VERSION ""

NS_ :

BS_:

BU_: SBZA_R_LS SBZA_L_LS VIS2_LS SDM_LS PEPS_LS UPA_LS PTM_LS MSM_LS HFP_LS EOCM_F_LS ECC_LS DCAC_LS CGM_LS BSM_LS BCM_LS AOS_LS

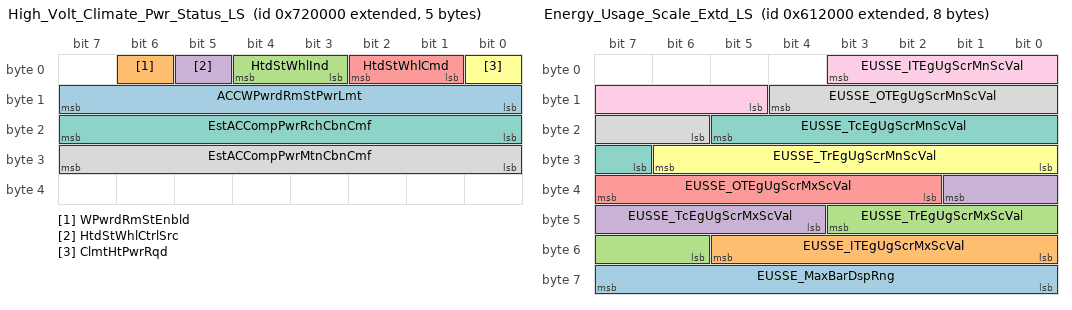
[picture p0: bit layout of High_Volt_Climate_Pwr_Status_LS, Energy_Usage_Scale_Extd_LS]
BO_ 2154954752 High_Volt_Climate_Pwr_Status_LS: 5 ECC_LS
 SG_ ACCWPwrdRmStPwrLmt : 15|8@0+ (0.1,0) [0|25.5] "kW"  CGM_LS
 SG_ WPwrdRmStEnbld : 6|1@0+ (1,0) [0|1] ""  CGM_LS
 SG_ HtdStWhlInd : 4|2@0+ (1,0) [0|3] ""  CGM_LS
 SG_ HtdStWhlCtrlSrc : 5|1@0+ (1,0) [0|1] ""  CGM_LS
 SG_ HtdStWhlCmd : 2|2@0+ (1,0) [0|3] ""  CGM_LS
 SG_ ClmtHtPwrRqd : 0|1@0+ (1,0) [0|1] ""  CGM_LS
 SG_ EstACCompPwrRchCbnCmf : 23|8@0+ (0.04,0) [0|10.2] "kw"  CGM_LS,BSM_LS
 SG_ EstACCompPwrMtnCbnCmf : 31|8@0+ (0.04,0) [0|10.2] "kW"  CGM_LS,BSM_LS

BO_ 2153848832 Energy_Usage_Scale_Extd_LS: 8 BSM_LS
 SG_ EUSSE_MaxBarDspRng : 63|8@0+ (1,0) [0|255] ""  CGM_LS
 SG_ EUSSE_ITEgUgScrMxScVal : 53|6@0+ (5,0) [0|315] ""  CGM_LS
 SG_ EUSSE_TrEgUgScrMxScVal : 43|6@0+ (5,0) [0|315] ""  CGM_LS
 SG_ EUSSE_TcEgUgScrMxScVal : 33|6@0+ (5,0) [0|315] ""  CGM_LS
 SG_ EUSSE_OTEgUgScrMxScVal : 39|6@0+ (5,0) [0|315] ""  CGM_LS
 SG_ EUSSE_TrEgUgScrMnScVal : 30|7@0- (5,0) [-320|315] ""  CGM_LS
 SG_ EUSSE_TcEgUgScrMnScVal : 21|7@0- (5,0) [-320|315] ""  CGM_LS
 SG_ EUSSE_OTEgUgScrMnScVal : 12|7@0- (5,0) [-320|315] ""  CGM_LS
 SG_ EUSSE_ITEgUgScrMnScVal : 3|7@0- (5,0) [-320|315] ""  CGM_LS

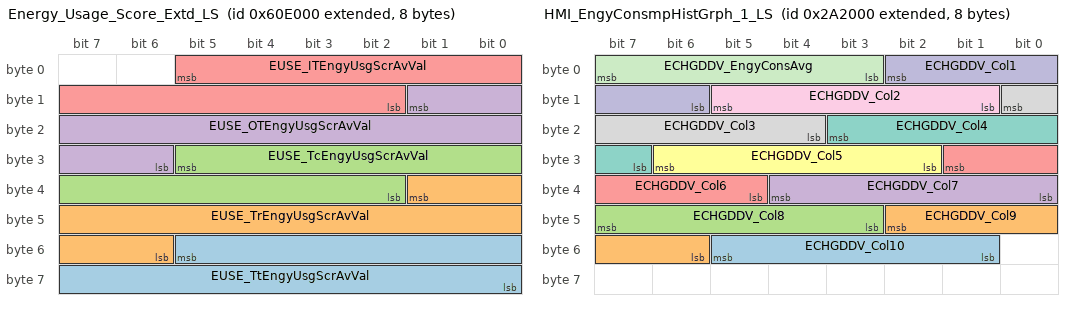
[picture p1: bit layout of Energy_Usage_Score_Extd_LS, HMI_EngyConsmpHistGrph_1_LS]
BO_ 2153832448 Energy_Usage_Score_Extd_LS: 8 BSM_LS
 SG_ EUSE_TtEngyUsgScrAvVal : 53|14@0- (0.1,0) [-819.2|819.1] ""  CGM_LS
 SG_ EUSE_TrEngyUsgScrAvVal : 33|12@0- (0.1,0) [-204.8|204.7] ""  CGM_LS
 SG_ EUSE_TcEngyUsgScrAvVal : 29|12@0- (0.1,0) [-204.8|204.7] ""  CGM_LS
 SG_ EUSE_OTEngyUsgScrAvVal : 9|12@0- (0.1,0) [-204.8|204.7] ""  CGM_LS
 SG_ EUSE_ITEngyUsgScrAvVal : 5|12@0- (0.1,0) [-204.8|204.7] ""  CGM_LS

BO_ 2150244352 HMI_EngyConsmpHistGrph_1_LS: 8 BSM_LS
 SG_ ECHGDDV_Col10 : 53|5@0+ (1,0) [0|31] ""  CGM_LS
 SG_ ECHGDDV_Col9 : 42|5@0+ (1,0) [0|31] ""  CGM_LS
 SG_ ECHGDDV_Col8 : 47|5@0+ (1,0) [0|31] ""  CGM_LS
 SG_ ECHGDDV_Col7 : 36|5@0+ (1,0) [0|31] ""  CGM_LS
 SG_ ECHGDDV_Col6 : 25|5@0+ (1,0) [0|31] ""  CGM_LS
 SG_ ECHGDDV_Col5 : 30|5@0+ (1,0) [0|31] ""  CGM_LS
 SG_ ECHGDDV_Col4 : 19|5@0+ (1,0) [0|31] ""  CGM_LS
 SG_ ECHGDDV_Col3 : 8|5@0+ (1,0) [0|31] ""  CGM_LS
 SG_ ECHGDDV_Col2 : 13|5@0+ (1,0) [0|31] ""  CGM_LS
 SG_ ECHGDDV_Col1 : 2|5@0+ (1,0) [0|31] ""  CGM_LS
 SG_ ECHGDDV_EngyConsAvg : 7|5@0+ (1,0) [0|31] ""  CGM_LS

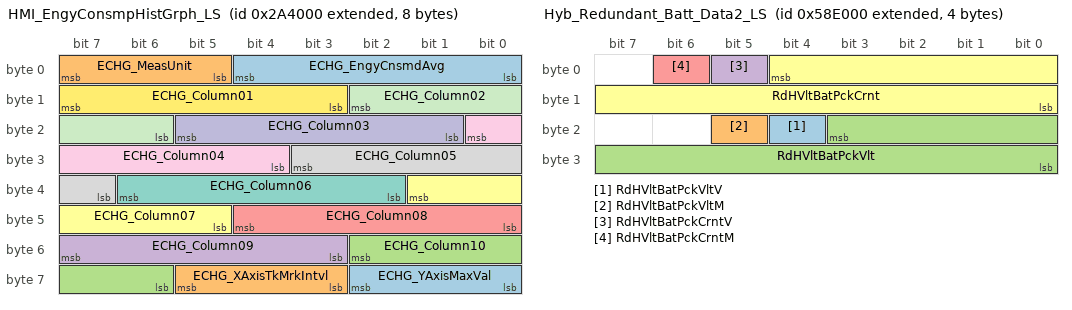
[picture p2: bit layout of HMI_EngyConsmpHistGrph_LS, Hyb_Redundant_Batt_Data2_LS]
BO_ 2150252544 HMI_EngyConsmpHistGrph_LS: 8 BSM_LS
 SG_ ECHG_YAxisMaxVal : 58|3@0+ (1,0) [0|7] ""  CGM_LS
 SG_ ECHG_XAxisTkMrkIntvl : 61|3@0+ (1,0) [0|7] ""  CGM_LS
 SG_ ECHG_Column10 : 50|5@0+ (1,0) [0|31] ""  CGM_LS
 SG_ ECHG_Column09 : 55|5@0+ (1,0) [0|31] ""  CGM_LS
 SG_ ECHG_Column08 : 44|5@0+ (1,0) [0|31] ""  CGM_LS
 SG_ ECHG_Column07 : 33|5@0+ (1,0) [0|31] ""  CGM_LS
 SG_ ECHG_Column06 : 38|5@0+ (1,0) [0|31] ""  CGM_LS
 SG_ ECHG_Column05 : 27|5@0+ (1,0) [0|31] ""  CGM_LS
 SG_ ECHG_Column04 : 16|5@0+ (1,0) [0|31] ""  CGM_LS
 SG_ ECHG_Column03 : 21|5@0+ (1,0) [0|31] ""  CGM_LS
 SG_ ECHG_Column02 : 10|5@0+ (1,0) [0|31] ""  CGM_LS
 SG_ ECHG_Column01 : 15|5@0+ (1,0) [0|31] ""  CGM_LS
 SG_ ECHG_EngyCnsmdAvg : 4|5@0+ (1,0) [0|31] ""  CGM_LS
 SG_ ECHG_MeasUnit : 7|3@0+ (1,0) [0|7] ""  CGM_LS

BO_ 2153308160 Hyb_Redundant_Batt_Data2_LS: 4 BSM_LS
 SG_ RdHVltBatPckVltV : 20|1@0+ (1,0) [0|1] ""  CGM_LS
 SG_ RdHVltBatPckVltM : 21|1@0+ (1,0) [0|1] ""  CGM_LS
 SG_ RdHVltBatPckVlt : 19|12@0+ (0.125,0) [0|511.875] "V"  CGM_LS
 SG_ RdHVltBatPckCrntV : 5|1@0+ (1,0) [0|1] ""  CGM_LS
 SG_ RdHVltBatPckCrntM : 6|1@0+ (1,0) [0|1] ""  CGM_LS
 SG_ RdHVltBatPckCrnt : 4|13@0- (0.15,0) [-614.4|614.25] "A"  CGM_LS

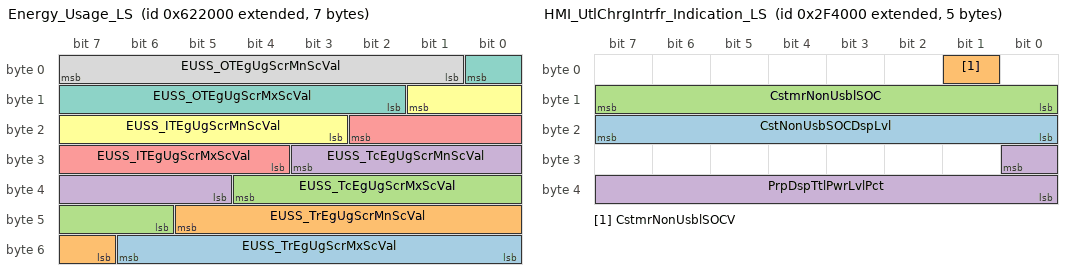
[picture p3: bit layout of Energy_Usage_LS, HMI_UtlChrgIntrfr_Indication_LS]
BO_ 2153914368 Energy_Usage_LS: 7 BSM_LS
 SG_ EUSS_TrEgUgScrMxScVal : 54|7@0- (0.1,0) [-5|5] ""  CGM_LS
 SG_ EUSS_TrEgUgScrMnScVal : 45|7@0- (0.1,0) [-5|5] ""  CGM_LS
 SG_ EUSS_TcEgUgScrMxScVal : 36|7@0- (0.1,0) [-5|5] ""  CGM_LS
 SG_ EUSS_TcEgUgScrMnScVal : 27|7@0- (0.1,0) [-5|5] ""  CGM_LS
 SG_ EUSS_ITEgUgScrMxScVal : 18|7@0- (0.1,0) [-5|5] ""  CGM_LS
 SG_ EUSS_ITEgUgScrMnScVal : 9|7@0- (0.1,0) [-5|5] ""  CGM_LS
 SG_ EUSS_OTEgUgScrMxScVal : 0|7@0- (0.1,0) [-5|5] ""  CGM_LS
 SG_ EUSS_OTEgUgScrMnScVal : 7|7@0- (0.1,0) [-5|5] ""  CGM_LS

BO_ 2150580224 HMI_UtlChrgIntrfr_Indication_LS: 5 BSM_LS
 SG_ CstNonUsbSOCDspLvl : 23|8@0+ (0.392157,0) [0|100.000035] "%"  CGM_LS
 SG_ CstmrNonUsblSOCV : 1|1@0+ (1,0) [0|1] ""  CGM_LS
 SG_ CstmrNonUsblSOC : 15|8@0+ (0.392157,0) [0|100.000035] "%"  CGM_LS
 SG_ PrpDspTtlPwrLvlPct : 24|9@0- (0.392157,0) [-100.392192|100.000035] "%"  CGM_LS

BO_ 2150080512 Aux_Coolant_Heater_Status_LS: 8 BSM_LS
 SG_ LBCVLS_VehGPSLctV : 27|1@0+ (1,0) [0|1] ""  CGM_LS
 SG_ LBCVLS_VehGPSLct : 26|3@0+ (1,0) [0|7] ""  CGM_LS
 SG_ LBCPSS_PosUpdtStat : 20|2@0+ (1,0) [0|3] ""  CGM_LS
 SG_ LBCPSS_PosUpdtLct : 18|3@0+ (1,0) [0|7] ""  CGM_LS
 SG_ LBCCsStAvl : 7|1@0+ (1,0) [0|1] ""  CGM_LS
 SG_ LBCCsCrStVal : 2|2@0+ (1,0) [0|3] ""  CGM_LS
 SG_ LBCCF_Lct4PosStrdIO : 28|1@0+ (1,0) [0|1] ""  CGM_LS
 SG_ LBCCF_Lct3PosStrdIO : 29|1@0+ (1,0) [0|1] ""  CGM_LS
 SG_ LBCCF_Lct2PosStrdIO : 30|1@0+ (1,0) [0|1] ""  CGM_LS
 SG_ LBCCF_Lct1PosStrdIO : 31|1@0+ (1,0) [0|1] ""  CGM_LS
 SG_ LBCCDRR_PosNumbr : 10|3@0+ (1,0) [0|7] ""  CGM_LS
 SG_ LBCCDRR_ClrStrdPosResp : 12|2@0+ (1,0) [0|3] ""  CGM_LS
 SG_ ChrgCyclOvrlEngyEcnEq : 51|12@0+ (0.1,0) [0|409.5] "km/l"  CGM_LS
 SG_ ChrgCyclElecEngyEcnEq : 35|12@0+ (0.1,0) [0|409.5] "km/l"  CGM_LS
 SG_ LBCChrgLvlPrfExpIO : 6|1@0+ (1,0) [0|1] ""  CGM_LS
 SG_ EngAstHtDfrdHtMdAct : 0|1@0+ (1,0) [0|1] ""  ECC_LS,CGM_LS
 SG_ AuxClntHtrVlvStat : 5|3@0+ (1,0) [0|7] ""  ECC_LS,CGM_LS

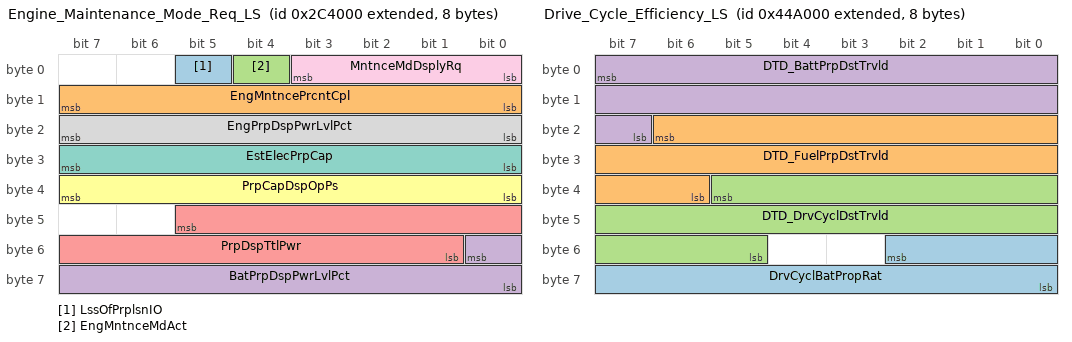
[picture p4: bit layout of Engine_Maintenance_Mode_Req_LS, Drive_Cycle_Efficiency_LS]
BO_ 2150383616 Engine_Maintenance_Mode_Req_LS: 8 BSM_LS
 SG_ LssOfPrplsnIO : 5|1@0+ (1,0) [0|1] ""  CGM_LS
 SG_ EngMntncePrcntCpl : 15|8@0+ (0.392157,0) [0|100.000035] "%"  CGM_LS
 SG_ EngMntnceMdAct : 4|1@0+ (1,0) [0|1] ""  CGM_LS
 SG_ BatPrpDspPwrLvlPct : 48|9@0- (0.392157,0) [-100.392192|100.000035] "%"  CGM_LS
 SG_ PrpDspTtlPwr : 45|13@0+ (0.5,-326.6) [-326.6|3768.9] "kW"  CGM_LS
 SG_ PrpCapDspOpPs : 39|8@0+ (0.392157,0) [0|100.000035] "%"  CGM_LS
 SG_ EstElecPrpCap : 31|8@0+ (0.392157,0) [0|100.000035] "%"  CGM_LS
 SG_ EngPrpDspPwrLvlPct : 23|8@0+ (0.392157,0) [0|100.000035] "%"  CGM_LS
 SG_ MntnceMdDsplyRq : 3|4@0+ (1,0) [0|15] ""  CGM_LS

BO_ 2151981056 Drive_Cycle_Efficiency_LS: 8 BSM_LS
 SG_ DrvCyclBatPropRat : 50|11@0+ (0.048852,0) [0|100.000044] "%"  CGM_LS
 SG_ DTD_FuelPrpDstTrvld : 22|17@0+ (0.015625,0) [0|2047.984375] "km"  CGM_LS
 SG_ DTD_DrvCyclDstTrvld : 37|17@0+ (0.015625,0) [0|2047.984375] "km"  CGM_LS
 SG_ DTD_BattPrpDstTrvld : 7|17@0+ (0.015625,0) [0|2047.984375] "km"  CGM_LS

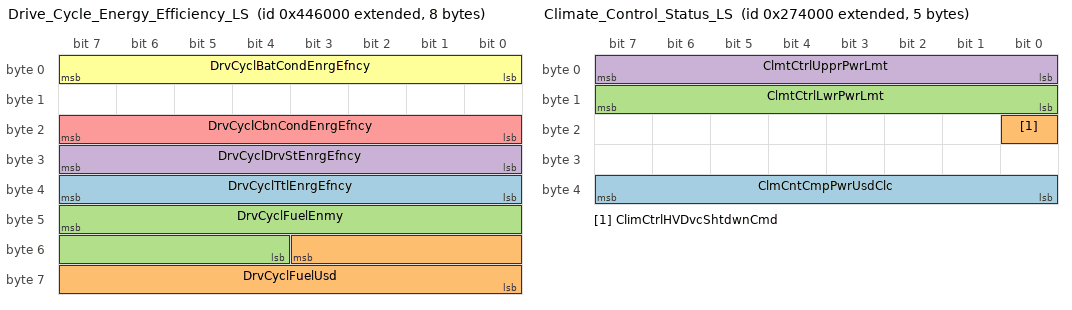
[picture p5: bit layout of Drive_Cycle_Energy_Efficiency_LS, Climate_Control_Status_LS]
BO_ 2151964672 Drive_Cycle_Energy_Efficiency_LS: 8 BSM_LS
 SG_ DrvCyclTtlEnrgEfncy : 39|8@0+ (0.392157,0) [0|100.000035] "%"  CGM_LS
 SG_ DrvCyclFuelUsd : 51|12@0+ (0.125,0) [0|511.875] "liters"  CGM_LS
 SG_ DrvCyclFuelEnmy : 47|12@0+ (0.1,0) [0|409.5] "km/liters"  CGM_LS
 SG_ DrvCyclDrvStEnrgEfncy : 31|8@0+ (0.392157,0) [0|100.000035] "%"  CGM_LS
 SG_ DrvCyclCbnCondEnrgEfncy : 23|8@0+ (0.392157,0) [0|100.000035] "%"  CGM_LS
 SG_ DrvCyclBatCondEnrgEfncy : 7|8@0+ (0.392157,0) [0|100.000035] "%"  CGM_LS

BO_ 2150055936 Climate_Control_Status_LS: 5 BSM_LS
 SG_ ClmCntCmpPwrUsdClc : 39|8@0+ (0.04,0) [0|10.2] "kW"  ECC_LS,CGM_LS
 SG_ ClimCtrlHVDvcShtdwnCmd : 16|1@0+ (1,0) [0|1] ""  ECC_LS,CGM_LS
 SG_ ClmtCtrlLwrPwrLmt : 15|8@0+ (0.1,0) [0|25.5] "kW"  ECC_LS,CGM_LS
 SG_ ClmtCtrlUpprPwrLmt : 7|8@0+ (0.1,0) [0|25.5] "kW"  ECC_LS,CGM_LS

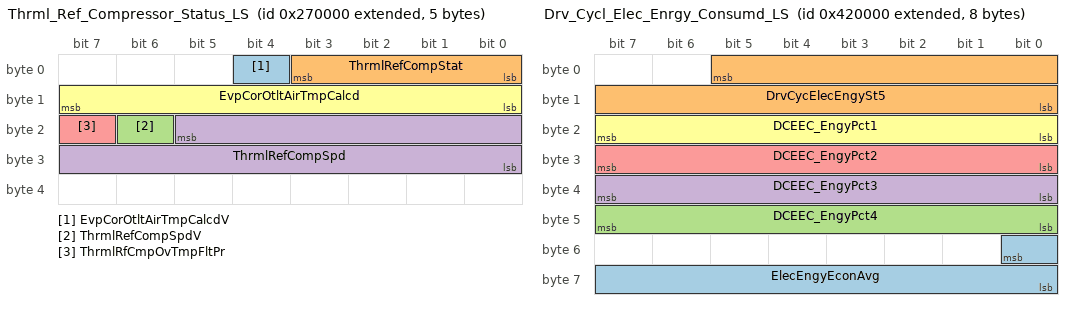
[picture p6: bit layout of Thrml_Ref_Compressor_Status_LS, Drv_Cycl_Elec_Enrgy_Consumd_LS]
BO_ 2150039552 Thrml_Ref_Compressor_Status_LS: 5 BSM_LS
 SG_ EvpCorOtltAirTmpCalcdV : 4|1@0+ (1,0) [0|1] ""  ECC_LS,CGM_LS
 SG_ ThrmlRefCompStat : 3|4@0+ (1,0) [0|15] ""  ECC_LS,CGM_LS
 SG_ ThrmlRefCompSpdV : 22|1@0+ (1,0) [0|1] ""  ECC_LS,CGM_LS
 SG_ ThrmlRefCompSpd : 21|14@0+ (1,0) [0|16383] "rpm"  ECC_LS,CGM_LS
 SG_ ThrmlRfCmpOvTmpFltPr : 23|1@0+ (1,0) [0|1] ""  ECC_LS,CGM_LS
 SG_ EvpCorOtltAirTmpCalcd : 15|8@0+ (0.5,-40) [-40|87.5] "deg C"  ECC_LS,CGM_LS

BO_ 2151809024 Drv_Cycl_Elec_Enrgy_Consumd_LS: 8 BSM_LS
 SG_ ElecEngyEconAvg : 48|9@0+ (0.1,0) [0|51.1] ""  CGM_LS
 SG_ DrvCycElecEngySt5 : 5|14@0+ (0.36,0) [0|5897.88] "MJ"  CGM_LS
 SG_ DCEEC_EngyPct4 : 47|8@0+ (0.392157,0) [0|100.000035] "%"  CGM_LS
 SG_ DCEEC_EngyPct3 : 39|8@0+ (0.392157,0) [0|100.000035] "%"  CGM_LS
 SG_ DCEEC_EngyPct2 : 31|8@0+ (0.392157,0) [0|100.000035] "%"  CGM_LS
 SG_ DCEEC_EngyPct1 : 23|8@0+ (0.392157,0) [0|100.000035] "%"  CGM_LS

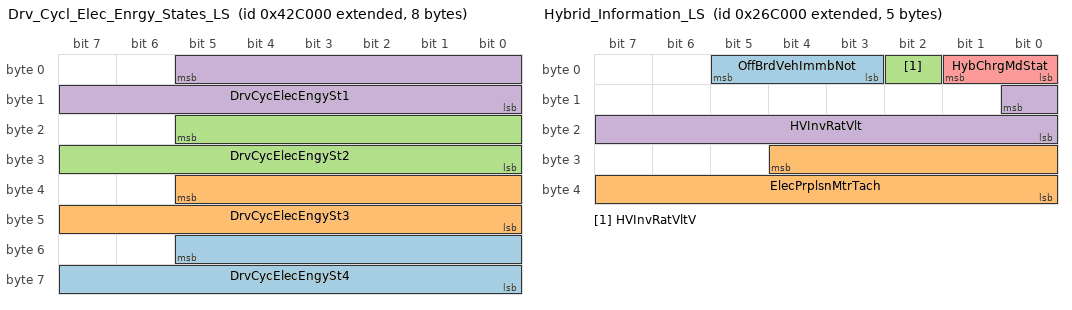
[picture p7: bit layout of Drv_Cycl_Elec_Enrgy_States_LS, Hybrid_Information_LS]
BO_ 2151858176 Drv_Cycl_Elec_Enrgy_States_LS: 8 BSM_LS
 SG_ DrvCycElecEngySt4 : 53|14@0+ (0.36,0) [0|5897.88] "MJ"  CGM_LS
 SG_ DrvCycElecEngySt3 : 37|14@0+ (0.36,0) [0|5897.88] "MJ"  CGM_LS
 SG_ DrvCycElecEngySt2 : 21|14@0+ (0.36,0) [0|5897.88] "MJ"  CGM_LS
 SG_ DrvCycElecEngySt1 : 5|14@0+ (0.36,0) [0|5897.88] "MJ"  CGM_LS

BO_ 2150023168 Hybrid_Information_LS: 5 BSM_LS
 SG_ OffBrdVehImmbNot : 5|3@0+ (1,0) [0|7] ""  CGM_LS
 SG_ ElecPrplsnMtrTach : 28|13@0+ (1,0) [0|8191] "rpm"  CGM_LS
 SG_ HVInvRatVltV : 2|1@0+ (1,0) [0|1] ""  ECC_LS,CGM_LS
 SG_ HVInvRatVlt : 8|9@0+ (1,0) [0|511] "volts"  ECC_LS,CGM_LS
 SG_ HybChrgMdStat : 1|2@0+ (1,0) [0|3] ""  ECC_LS,CGM_LS

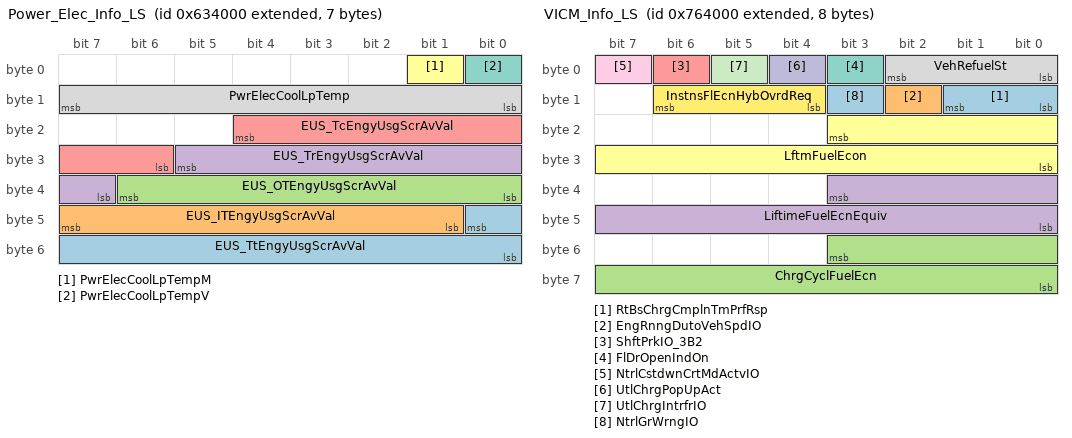
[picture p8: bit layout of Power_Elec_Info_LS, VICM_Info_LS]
BO_ 2153988096 Power_Elec_Info_LS: 7 BSM_LS
 SG_ EUS_TtEngyUsgScrAvVal : 40|9@0- (0.1,0) [-20|20] ""  CGM_LS
 SG_ EUS_ITEngyUsgScrAvVal : 47|7@0- (0.1,0) [-5|5] ""  CGM_LS
 SG_ EUS_OTEngyUsgScrAvVal : 38|7@0- (0.1,0) [-5|5] ""  CGM_LS
 SG_ EUS_TrEngyUsgScrAvVal : 29|7@0- (0.1,0) [-5|5] ""  CGM_LS
 SG_ EUS_TcEngyUsgScrAvVal : 20|7@0- (0.1,0) [-5|5] ""  CGM_LS
 SG_ PwrElecCoolLpTempM : 1|1@0+ (1,0) [0|1] ""  ECC_LS,CGM_LS
 SG_ PwrElecCoolLpTempV : 0|1@0+ (1,0) [0|1] ""  ECC_LS,CGM_LS
 SG_ PwrElecCoolLpTemp : 15|8@0+ (1,-40) [-40|215] "deg C"  ECC_LS,CGM_LS

BO_ 1516 UUDT_Resp_From_VICM_LS: 8 BSM_LS
 SG_ DgnInf_LS5EC : 7|64@0+ (1,0) [0|1.84467440737096E+019] ""  CGM_LS

BO_ 2155233280 VICM_Info_LS: 8 BSM_LS
 SG_ RtBsChrgCmplnTmPrfRsp : 9|2@0+ (1,0) [0|3] ""  CGM_LS
 SG_ EngRnngDutoVehSpdIO : 10|1@0+ (1,0) [0|1] ""  CGM_LS
 SG_ ChrgCyclFuelEcn : 51|12@0+ (0.1,0) [0|409.5] "km/l"  CGM_LS
 SG_ LiftimeFuelEcnEquiv : 35|12@0+ (0.1,0) [0|409.5] "km/l"  CGM_LS
 SG_ ShftPrkIO_3B2 : 6|1@0+ (1,0) [0|1] ""  CGM_LS
 SG_ LftmFuelEcon : 19|12@0+ (0.1,0) [0|409.5] "kilometers/liter"  CGM_LS
 SG_ FlDrOpenIndOn : 3|1@0+ (1,0) [0|1] ""  CGM_LS
 SG_ VehRefuelSt : 2|3@0+ (1,0) [0|7] ""  CGM_LS
 SG_ NtrlCstdwnCrtMdActvIO : 7|1@0+ (1,0) [0|1] ""  CGM_LS
 SG_ UtlChrgPopUpAct : 4|1@0+ (1,0) [0|1] ""  CGM_LS
 SG_ UtlChrgIntrfrIO : 5|1@0+ (1,0) [0|1] ""  CGM_LS
 SG_ InstnsFlEcnHybOvrdReq : 14|3@0+ (1,0) [0|7] ""  CGM_LS
 SG_ NtrlGrWrngIO : 11|1@0+ (1,0) [0|1] ""  CGM_LS

BO_ 2028 USDT_Resp_From_VICM_LS: 8 BSM_LS
 SG_ DgnInf : 7|64@0+ (1,0) [0|1.84467440737096E+019] ""  CGM_LS

BO_ 2150121472 Remote_Trailer_Lighting_Req_LS: 1 CGM_LS
 SG_ RmtTrlrLtngSeqReq : 7|2@0+ (1,0) [0|3] ""  BCM_LS

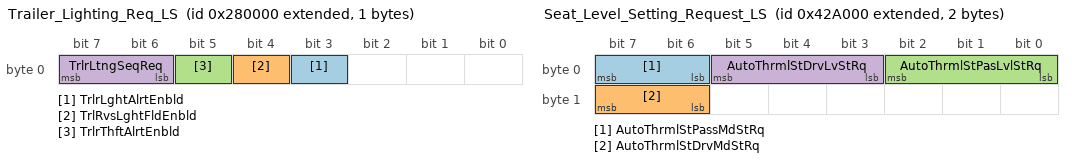
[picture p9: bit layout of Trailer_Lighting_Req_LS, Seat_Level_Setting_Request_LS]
BO_ 2150105088 Trailer_Lighting_Req_LS: 1 CGM_LS
 SG_ TrlrLghtAlrtEnbld : 3|1@0+ (1,0) [0|1] "" Vector__XXX
 SG_ TrlRvsLghtFldEnbld : 4|1@0+ (1,0) [0|1] "" Vector__XXX
 SG_ TrlrThftAlrtEnbld : 5|1@0+ (1,0) [0|1] "" Vector__XXX
 SG_ TrlrLtngSeqReq : 7|2@0+ (1,0) [0|3] ""  BCM_LS

BO_ 2152013824 Smart_High_Beam_Cust_LS: 1 VIS2_LS
 SG_ SmrtHgBmAstCstSetAvail : 4|1@0+ (1,0) [0|1] ""  CGM_LS
 SG_ SmrtHgBmAstCstCurrSetVal : 7|3@0+ (1,0) [0|7] ""  CGM_LS,BCM_LS

BO_ 2159255552 ODI_CenterStack_2_BCM_LS: 8 CGM_LS
 SG_ ODI_CntrStck2BCM : 7|64@0+ (1,0) [0|1.84467440737096E+019] ""  BCM_LS

BO_ 2151817216 Heated_Wndshild_Cstmr_Req_LS: 1 ECC_LS
 SG_ HtdFrntWSCustRq : 7|1@0+ (1,0) [0|1] ""  CGM_LS,BCM_LS

BO_ 2151849984 Seat_Level_Setting_Request_LS: 2 ECC_LS
 SG_ AutoThrmlStPassMdStRq : 7|2@0+ (1,0) [0|3] ""  CGM_LS,BCM_LS
 SG_ AutoThrmlStDrvMdStRq : 15|2@0+ (1,0) [0|3] ""  CGM_LS,BCM_LS
 SG_ AutoThrmlStPasLvlStRq : 2|3@0+ (1,0) [0|7] ""  CGM_LS,BCM_LS
 SG_ AutoThrmlStDrvLvStRq : 5|3@0+ (1,0) [0|7] ""  CGM_LS,BCM_LS

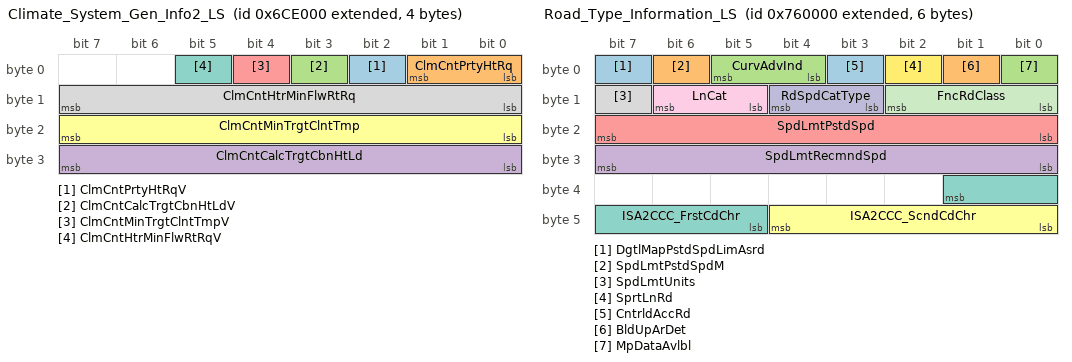
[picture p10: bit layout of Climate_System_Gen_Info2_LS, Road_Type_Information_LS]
BO_ 2154618880 Climate_System_Gen_Info2_LS: 4 ECC_LS
 SG_ ClmCntPrtyHtRqV : 2|1@0+ (1,0) [0|1] ""  CGM_LS,BCM_LS
 SG_ ClmCntPrtyHtRq : 1|2@0+ (1,0) [0|3] ""  CGM_LS,BCM_LS
 SG_ ClmCntCalcTrgtCbnHtLdV : 3|1@0+ (1,0) [0|1] ""  CGM_LS,BCM_LS
 SG_ ClmCntCalcTrgtCbnHtLd : 31|8@0+ (0.12549,0) [0|32] "kW"  CGM_LS,BCM_LS
 SG_ ClmCntMinTrgtClntTmpV : 4|1@0+ (1,0) [0|1] ""  CGM_LS,BCM_LS
 SG_ ClmCntMinTrgtClntTmp : 23|8@0+ (0.39216,0) [0|100.0008] "degC"  CGM_LS,BCM_LS
 SG_ ClmCntHtrMinFlwRtRqV : 5|1@0+ (1,0) [0|1] ""  CGM_LS,BCM_LS
 SG_ ClmCntHtrMinFlwRtRq : 15|8@0+ (0.25098,0) [0|63.9999] "l/min"  CGM_LS,BCM_LS

BO_ 2150129664 Hitch_Park_Brake_Assist_LS: 1 CGM_LS
 SG_ HtVwAutnmsEPBAplyReqd : 7|1@0+ (1,0) [0|1] ""  BCM_LS

BO_ 2155216896 Road_Type_Information_LS: 6 CGM_LS
 SG_ DgtlMapPstdSpdLimAsrd : 7|1@0+ (1,0) [0|1] ""  VIS2_LS
 SG_ SpdLmtPstdSpdM : 6|1@0+ (1,0) [0|1] ""  VIS2_LS
 SG_ CurvAdvInd : 5|2@0+ (1,0) [0|3] "" Vector__XXX
 SG_ SpdLmtRecmndSpd : 31|8@0+ (1,0) [0|255] ""  VIS2_LS
 SG_ SpdLmtPstdSpd : 23|8@0+ (1,0) [0|255] ""  VIS2_LS
 SG_ ISA2CCC_ScndCdChr : 44|5@0+ (1,0) [0|31] ""  VIS2_LS,BCM_LS
 SG_ ISA2CCC_FrstCdChr : 33|5@0+ (1,0) [0|31] ""  VIS2_LS,BCM_LS
 SG_ SpdLmtUnits : 15|1@0+ (1,0) [0|1] ""  VIS2_LS,BCM_LS
 SG_ LnCat : 14|2@0+ (1,0) [0|3] ""  VIS2_LS,BCM_LS
 SG_ RdSpdCatType : 12|2@0+ (1,0) [0|3] ""  VIS2_LS,EOCM_F_LS,BCM_LS
 SG_ FncRdClass : 10|3@0+ (1,0) [0|7] ""  VIS2_LS,EOCM_F_LS,BCM_LS
 SG_ SprtLnRd : 2|1@0+ (1,0) [0|1] ""  VIS2_LS,BCM_LS
 SG_ CntrldAccRd : 3|1@0+ (1,0) [0|1] ""  VIS2_LS,BCM_LS
 SG_ BldUpArDet : 1|1@0+ (1,0) [0|1] ""  VIS2_LS,EOCM_F_LS,BCM_LS
 SG_ MpDataAvlbl : 0|1@0+ (1,0) [0|1] ""  VIS2_LS,EOCM_F_LS,BCM_LS

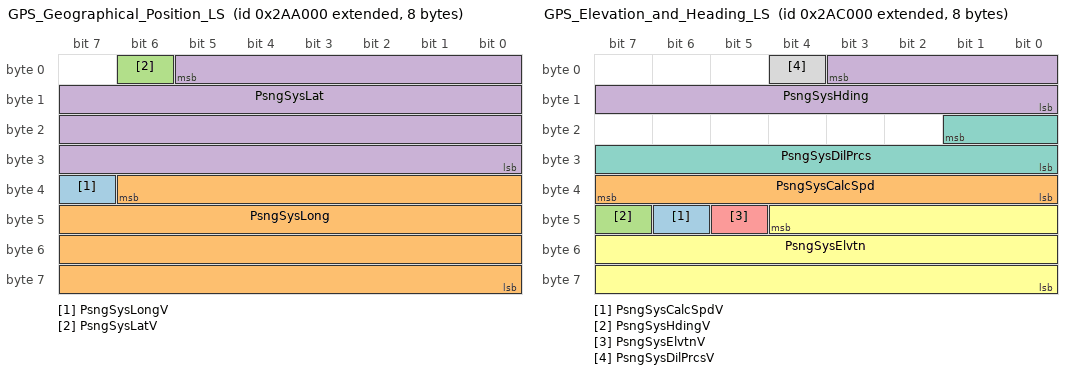
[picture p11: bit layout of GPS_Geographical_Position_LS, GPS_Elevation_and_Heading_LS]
BO_ 2150277120 GPS_Geographical_Position_LS: 8 CGM_LS
 SG_ PsngSysLongV : 39|1@0+ (1,0) [0|1] ""  SBZA_R_LS,SBZA_L_LS,VIS2_LS,EOCM_F_LS,ECC_LS,BCM_LS
 SG_ PsngSysLong : 38|31@0- (1,0) [-1073741824|1073741823] "ms arc"  SBZA_R_LS,SBZA_L_LS,VIS2_LS,EOCM_F_LS,ECC_LS,BCM_LS
 SG_ PsngSysLatV : 6|1@0+ (1,0) [0|1] ""  SBZA_R_LS,SBZA_L_LS,VIS2_LS,EOCM_F_LS,ECC_LS,BCM_LS
 SG_ PsngSysLat : 5|30@0- (1,0) [-536870912|536870911] "ms arc"  SBZA_R_LS,SBZA_L_LS,VIS2_LS,EOCM_F_LS,ECC_LS,BCM_LS

BO_ 2150285312 GPS_Elevation_and_Heading_LS: 8 CGM_LS
 SG_ PsngSysCalcSpdV : 46|1@0+ (1,0) [0|1] ""  SBZA_R_LS,SBZA_L_LS,EOCM_F_LS
 SG_ PsngSysCalcSpd : 39|8@0+ (1,0) [0|255] "km / h"  SBZA_R_LS,SBZA_L_LS,EOCM_F_LS
 SG_ PsngSysHdingV : 47|1@0+ (1,0) [0|1] ""  SBZA_R_LS,SBZA_L_LS,EOCM_F_LS,ECC_LS,BCM_LS
 SG_ PsngSysHding : 3|12@0+ (0.1,0) [0|409.5] "deg"  SBZA_R_LS,SBZA_L_LS,EOCM_F_LS,ECC_LS,BCM_LS
 SG_ PsngSysElvtnV : 45|1@0+ (1,0) [0|1] ""  SBZA_R_LS,SBZA_L_LS,EOCM_F_LS,ECC_LS,BSM_LS,BCM_LS
 SG_ PsngSysElvtn : 44|21@0+ (1,-100000) [-100000|1997151] "cm"  SBZA_R_LS,SBZA_L_LS,EOCM_F_LS,ECC_LS,BSM_LS,BCM_LS
 SG_ PsngSysDilPrcs : 17|10@0+ (0.1,0) [0|102.3] ""  SBZA_R_LS,SBZA_L_LS,EOCM_F_LS,BCM_LS
 SG_ PsngSysDilPrcsV : 4|1@0+ (1,0) [0|1] ""  SBZA_R_LS,SBZA_L_LS,EOCM_F_LS,BCM_LS

BO_ 2151047168 HUD_Status_LS: 1 CGM_LS
 SG_ HdUpDspAnmtStat : 3|3@0+ (1,0) [0|7] "" Vector__XXX
 SG_ HUDActv : 0|1@0+ (1,0) [0|1] ""  EOCM_F_LS,BCM_LS

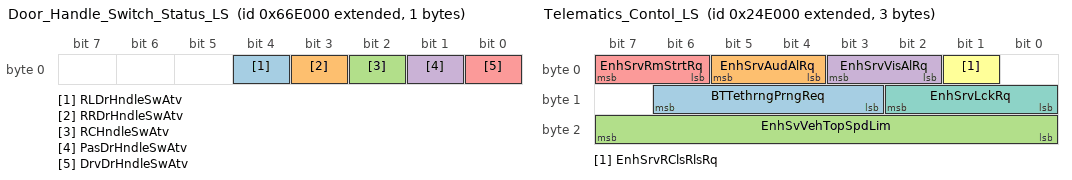
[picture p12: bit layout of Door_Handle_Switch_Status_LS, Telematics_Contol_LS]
BO_ 2154225664 Door_Handle_Switch_Status_LS: 1 PEPS_LS
 SG_ RLDrHndleSwAtv : 4|1@0+ (1,0) [0|1] ""  CGM_LS,BCM_LS
 SG_ RRDrHndleSwAtv : 3|1@0+ (1,0) [0|1] ""  CGM_LS,BCM_LS
 SG_ RCHndleSwAtv : 2|1@0+ (1,0) [0|1] ""  CGM_LS,BCM_LS
 SG_ PasDrHndleSwAtv : 1|1@0+ (1,0) [0|1] ""  CGM_LS,BCM_LS
 SG_ DrvDrHndleSwAtv : 0|1@0+ (1,0) [0|1] ""  CGM_LS,BCM_LS

BO_ 2149900288 Telematics_Contol_LS: 3 CGM_LS
 SG_ BTTethrngPrngReq : 14|4@0+ (1,0) [0|15] "" Vector__XXX
 SG_ EnhSrvAudAlRq : 5|2@0+ (1,0) [0|3] ""  BCM_LS
 SG_ EnhSvVehTopSpdLim : 23|8@0+ (2,0) [0|510] "km / h"  BCM_LS
 SG_ EnhSrvVisAlRq : 3|2@0+ (1,0) [0|3] ""  BCM_LS
 SG_ EnhSrvRmStrtRq : 7|2@0+ (1,0) [0|3] ""  BCM_LS
 SG_ EnhSrvRClsRlsRq : 1|1@0+ (1,0) [0|1] ""  PTM_LS,BCM_LS
 SG_ EnhSrvLckRq : 10|3@0+ (1,0) [0|7] ""  BCM_LS

BO_ 2157985792 Fob_Programming_Request_LS: 1 CGM_LS
 SG_ FobProgEvntRqd : 0|1@0+ (1,0) [0|1] ""  BCM_LS

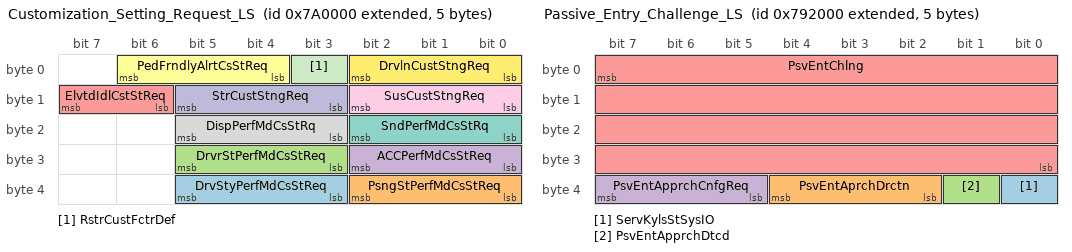
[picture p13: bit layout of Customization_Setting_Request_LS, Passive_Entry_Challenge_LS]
BO_ 2155479040 Customization_Setting_Request_LS: 5 CGM_LS
 SG_ DrvStyPerfMdCsStReq : 37|3@0+ (1,0) [0|7] ""  BCM_LS
 SG_ PsngStPerfMdCsStReq : 34|3@0+ (1,0) [0|7] ""  BCM_LS
 SG_ DrvrStPerfMdCsStReq : 29|3@0+ (1,0) [0|7] ""  BCM_LS
 SG_ ACCPerfMdCsStReq : 26|3@0+ (1,0) [0|7] ""  BCM_LS
 SG_ ElvtdIdlCstStReq : 15|2@0+ (1,0) [0|3] ""  BCM_LS
 SG_ PedFrndlyAlrtCsStReq : 6|3@0+ (1,0) [0|7] ""  BCM_LS
 SG_ SndPerfMdCsStRq : 18|3@0+ (1,0) [0|7] ""  BCM_LS
 SG_ DispPerfMdCsStRq : 21|3@0+ (1,0) [0|7] ""  BCM_LS
 SG_ SusCustStngReq : 10|3@0+ (1,0) [0|7] ""  BCM_LS
 SG_ StrCustStngReq : 13|3@0+ (1,0) [0|7] ""  BCM_LS
 SG_ RstrCustFctrDef : 3|1@0+ (1,0) [0|1] ""  VIS2_LS,BSM_LS,BCM_LS
 SG_ DrvlnCustStngReq : 2|3@0+ (1,0) [0|7] ""  BCM_LS

BO_ 2151383040 Reset_TP_request_LS: 1 CGM_LS
 SG_ TreInfMonSysRstReq : 0|1@0+ (1,0) [0|1] ""  BCM_LS

BO_ 2155421696 Passive_Entry_Challenge_LS: 5 PEPS_LS
 SG_ ServKylsStSysIO : 32|1@0+ (1,0) [0|1] ""  CGM_LS
 SG_ PsvEntAprchDrctn : 36|3@0+ (1,0) [0|7] ""  CGM_LS,BCM_LS
 SG_ PsvEntApprchDtcd : 33|1@0+ (1,0) [0|1] ""  CGM_LS,BCM_LS
 SG_ PsvEntApprchCnfgReq : 39|3@0+ (1,0) [0|7] ""  CGM_LS,BCM_LS
 SG_ PsvEntChlng : 7|32@0+ (1,0) [0|4294967295] "passwrd"  CGM_LS,BCM_LS

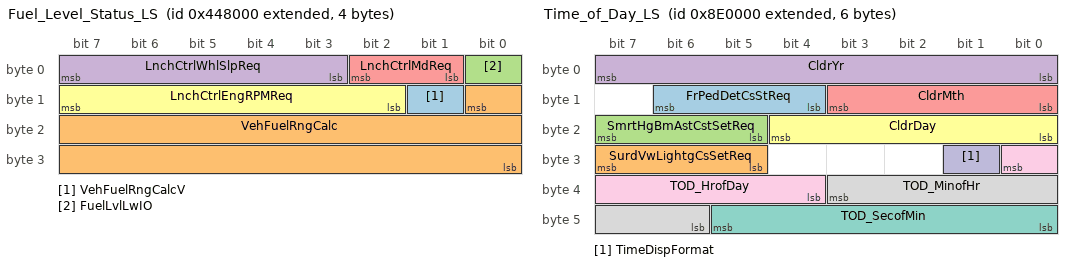
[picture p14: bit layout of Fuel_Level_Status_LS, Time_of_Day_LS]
BO_ 2151972864 Fuel_Level_Status_LS: 4 CGM_LS
 SG_ VehFuelRngCalcV : 9|1@0+ (1,0) [0|1] "" Vector__XXX
 SG_ VehFuelRngCalc : 8|17@0+ (0.015625,0) [0|2047.984375] "km" Vector__XXX
 SG_ FuelLvlLwIO : 0|1@0+ (1,0) [0|1] "" Vector__XXX
 SG_ LnchCtrlWhlSlpReq : 7|5@0+ (1,0) [0|31] ""  BCM_LS
 SG_ LnchCtrlMdReq : 2|2@0+ (1,0) [0|3] ""  BCM_LS
 SG_ LnchCtrlEngRPMReq : 15|6@0+ (1,0) [0|63] ""  BCM_LS

BO_ 2156789760 Time_of_Day_LS: 6 CGM_LS
 SG_ FrPedDetCsStReq : 14|3@0+ (1,0) [0|7] ""  EOCM_F_LS
 SG_ SurdVwLightgCsSetReq : 31|3@0+ (1,0) [0|7] "" Vector__XXX
 SG_ SmrtHgBmAstCstSetReq : 23|3@0+ (1,0) [0|7] ""  VIS2_LS
 SG_ CldrYr : 7|8@0+ (1,2000) [2000|2255] "year"  EOCM_F_LS,BSM_LS,BCM_LS
 SG_ CldrMth : 11|4@0+ (1,0) [0|15] ""  EOCM_F_LS,ECC_LS,BSM_LS,BCM_LS
 SG_ CldrDay : 20|5@0+ (1,0) [0|31] "days"  EOCM_F_LS,ECC_LS,BSM_LS,BCM_LS
 SG_ TOD_SecofMin : 45|6@0+ (1,0) [0|63] "s"  VIS2_LS,ECC_LS,BSM_LS,BCM_LS
 SG_ TOD_MinofHr : 35|6@0+ (1,0) [0|63] "min"  VIS2_LS,ECC_LS,BSM_LS,BCM_LS
 SG_ TOD_HrofDay : 24|5@0+ (1,0) [0|31] "hr"  VIS2_LS,ECC_LS,BSM_LS,BCM_LS
 SG_ TimeDispFormat : 25|1@0+ (1,0) [0|1] ""  BSM_LS

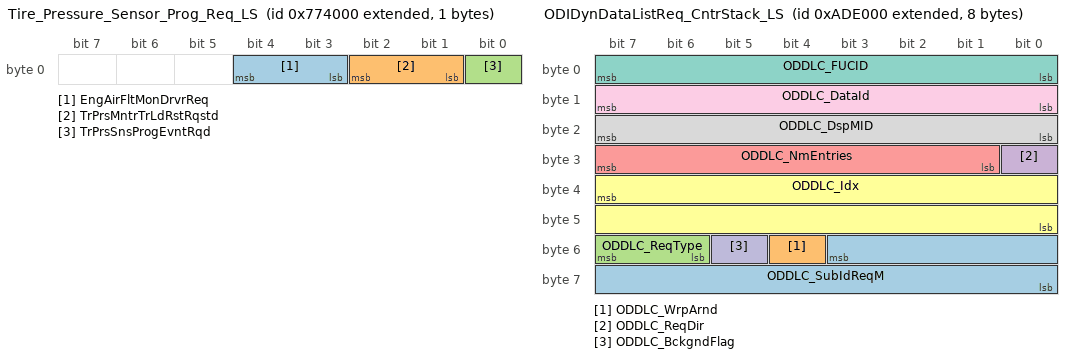
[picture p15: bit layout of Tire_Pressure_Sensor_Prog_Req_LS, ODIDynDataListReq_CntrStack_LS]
BO_ 2155298816 Tire_Pressure_Sensor_Prog_Req_LS: 1 CGM_LS
 SG_ EngAirFltMonDrvrReq : 4|2@0+ (1,0) [0|3] ""  BCM_LS
 SG_ TrPrsMntrTrLdRstRqstd : 2|2@0+ (1,0) [0|3] ""  BCM_LS
 SG_ TrPrsSnsProgEvntRqd : 0|1@0+ (1,0) [0|1] ""  BCM_LS

BO_ 2158878720 ODIDynDataListReq_CntrStack_LS: 8 CGM_LS
 SG_ ODDLC_SubIdReqM : 51|12@0+ (1,0) [0|4095] ""  VIS2_LS,BCM_LS
 SG_ ODDLC_WrpArnd : 52|1@0+ (1,0) [0|1] ""  VIS2_LS,BCM_LS
 SG_ ODDLC_ReqType : 55|2@0+ (1,0) [0|3] ""  VIS2_LS,BCM_LS
 SG_ ODDLC_ReqDir : 24|1@0+ (1,0) [0|1] ""  VIS2_LS,BCM_LS
 SG_ ODDLC_NmEntries : 31|7@0+ (1,0) [0|127] ""  VIS2_LS,BCM_LS
 SG_ ODDLC_Idx : 39|16@0+ (1,0) [0|65535] ""  VIS2_LS,BCM_LS
 SG_ ODDLC_FUCID : 7|8@0+ (1,0) [0|255] ""  VIS2_LS,BCM_LS
 SG_ ODDLC_DspMID : 23|8@0+ (1,0) [0|255] ""  VIS2_LS,BCM_LS
 SG_ ODDLC_DataId : 15|8@0+ (1,0) [0|255] ""  VIS2_LS,BCM_LS
 SG_ ODDLC_BckgndFlag : 53|1@0+ (1,0) [0|1] ""  VIS2_LS,BCM_LS

BO_ 2153938944 Remote_Reflash_Req_LS: 1 CGM_LS
 SG_ RmtRflshMdReqtd : 7|1@0+ (1,0) [0|1] ""  BCM_LS

BO_ 2150662144 Environment_Id_Resp_3_LS: 3 CGM_LS
 SG_ EnvIdRsp3 : 7|16@0+ (1,0) [0|65535] ""  BCM_LS
 SG_ EnvIdRspSt3 : 17|2@0+ (1,0) [0|3] ""  BCM_LS

BO_ 2150653952 Environment_Id_Resp_2_LS: 3 ECC_LS
 SG_ EnvIdRspSt2 : 17|2@0+ (1,0) [0|3] ""  CGM_LS,BCM_LS
 SG_ EnvIdRsp2 : 7|16@0+ (1,0) [0|65535] ""  CGM_LS,BCM_LS

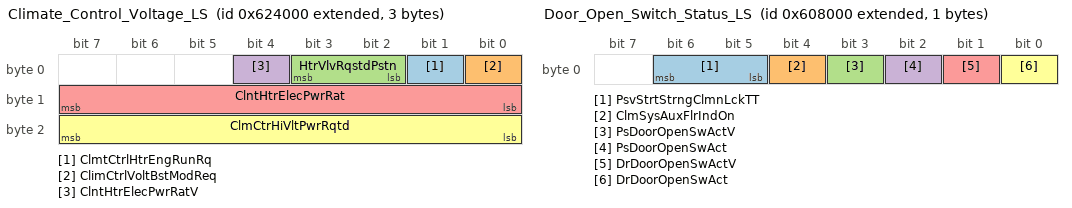
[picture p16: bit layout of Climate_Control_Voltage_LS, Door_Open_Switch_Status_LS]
BO_ 2153922560 Climate_Control_Voltage_LS: 3 ECC_LS
 SG_ ClmtCtrlHtrEngRunRq : 1|1@0+ (1,0) [0|1] ""  CGM_LS,BCM_LS
 SG_ ClimCtrlVoltBstModReq : 0|1@0+ (1,0) [0|1] ""  CGM_LS,BCM_LS
 SG_ HtrVlvRqstdPstn : 3|2@0+ (1,0) [0|3] ""  BSM_LS,CGM_LS
 SG_ ClntHtrElecPwrRatV : 4|1@0+ (1,0) [0|1] ""  BSM_LS,CGM_LS
 SG_ ClntHtrElecPwrRat : 15|8@0+ (0.04,0) [0|10.2] "kW"  BSM_LS,CGM_LS
 SG_ ClmCtrHiVltPwrRqtd : 23|8@0+ (0.1,0) [0|25.5] "kW"  BSM_LS,CGM_LS

BO_ 2153807872 Door_Open_Switch_Status_LS: 1 PEPS_LS
 SG_ PsvStrtStrngClmnLckTT : 6|2@0+ (1,0) [0|3] ""  CGM_LS
 SG_ ClmSysAuxFlrIndOn : 4|1@0+ (1,0) [0|1] ""  CGM_LS
 SG_ PsDoorOpenSwActV : 3|1@0+ (1,0) [0|1] ""  CGM_LS,BCM_LS
 SG_ PsDoorOpenSwAct : 2|1@0+ (1,0) [0|1] ""  CGM_LS,BCM_LS
 SG_ DrDoorOpenSwActV : 1|1@0+ (1,0) [0|1] ""  EOCM_F_LS,CGM_LS,BCM_LS
 SG_ DrDoorOpenSwAct : 0|1@0+ (1,0) [0|1] ""  EOCM_F_LS,CGM_LS,BCM_LS

BO_ 2151399424 Wash_Level_LS: 1 CGM_LS
 SG_ VhlFlRngLwIO : 1|1@0+ (1,0) [0|1] "" Vector__XXX
 SG_ WshFldLw : 0|1@0+ (1,0) [0|1] ""  BCM_LS

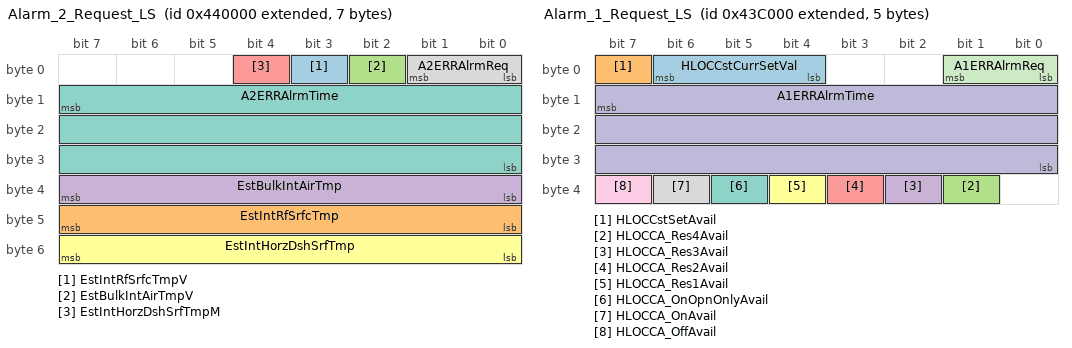
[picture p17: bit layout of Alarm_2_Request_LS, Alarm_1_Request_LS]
BO_ 2151940096 Alarm_2_Request_LS: 7 ECC_LS
 SG_ EstIntRfSrfcTmpV : 3|1@0+ (1,0) [0|1] ""  CGM_LS
 SG_ EstIntRfSrfcTmp : 47|8@0+ (0.5,-40) [-40|87.5] "deg C"  CGM_LS
 SG_ EstBulkIntAirTmpV : 2|1@0+ (1,0) [0|1] ""  CGM_LS
 SG_ EstBulkIntAirTmp : 39|8@0+ (0.5,-40) [-40|87.5] "deg C"  CGM_LS
 SG_ EstIntHorzDshSrfTmpM : 4|1@0+ (1,0) [0|1] ""  CGM_LS,BCM_LS
 SG_ EstIntHorzDshSrfTmp : 55|8@0+ (1,-40) [-40|215] "deg C"  CGM_LS,BCM_LS
 SG_ A2ERRAlrmTime : 15|24@0+ (1,0) [0|16777215] "min"  CGM_LS,BCM_LS
 SG_ A2ERRAlrmReq : 1|2@0+ (1,0) [0|3] ""  CGM_LS,BCM_LS

BO_ 2151923712 Alarm_1_Request_LS: 5 PTM_LS
 SG_ HLOCCstCurrSetVal : 6|3@0+ (1,0) [0|7] ""  PEPS_LS,CGM_LS
 SG_ HLOCCstSetAvail : 7|1@0+ (1,0) [0|1] ""  CGM_LS
 SG_ HLOCCA_Res4Avail : 33|1@0+ (1,0) [0|1] ""  CGM_LS
 SG_ HLOCCA_Res3Avail : 34|1@0+ (1,0) [0|1] ""  CGM_LS
 SG_ HLOCCA_Res2Avail : 35|1@0+ (1,0) [0|1] ""  CGM_LS
 SG_ HLOCCA_Res1Avail : 36|1@0+ (1,0) [0|1] ""  CGM_LS
 SG_ HLOCCA_OnOpnOnlyAvail : 37|1@0+ (1,0) [0|1] ""  CGM_LS
 SG_ HLOCCA_OnAvail : 38|1@0+ (1,0) [0|1] ""  CGM_LS
 SG_ HLOCCA_OffAvail : 39|1@0+ (1,0) [0|1] ""  CGM_LS
 SG_ A1ERRAlrmTime : 15|24@0+ (1,0) [0|16777215] "min"  CGM_LS,BCM_LS
 SG_ A1ERRAlrmReq : 1|2@0+ (1,0) [0|3] ""  CGM_LS,BCM_LS

BO_ 2150645760 Environment_Id_Resp_1_LS: 3 SDM_LS
 SG_ EnvIdRspSt1 : 17|2@0+ (1,0) [0|3] ""  CGM_LS,BCM_LS
 SG_ EnvIdRsp1 : 7|16@0+ (1,0) [0|65535] ""  CGM_LS,BCM_LS

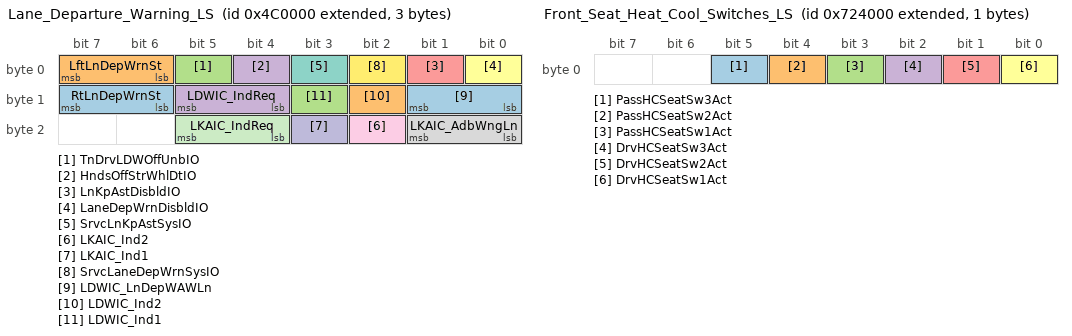
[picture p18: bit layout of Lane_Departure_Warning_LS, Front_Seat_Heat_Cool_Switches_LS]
BO_ 2152464384 Lane_Departure_Warning_LS: 3 EOCM_F_LS
 SG_ RtLnDepWrnSt : 15|2@0+ (1,0) [0|3] ""  CGM_LS
 SG_ LftLnDepWrnSt : 7|2@0+ (1,0) [0|3] ""  CGM_LS
 SG_ TnDrvLDWOffUnbIO : 5|1@0+ (1,0) [0|1] ""  CGM_LS
 SG_ HndsOffStrWhlDtIO : 4|1@0+ (1,0) [0|1] ""  CGM_LS
 SG_ LnKpAstDisbldIO : 1|1@0+ (1,0) [0|1] ""  CGM_LS
 SG_ LaneDepWrnDisbldIO : 0|1@0+ (1,0) [0|1] ""  CGM_LS
 SG_ SrvcLnKpAstSysIO : 3|1@0+ (1,0) [0|1] ""  CGM_LS,BCM_LS
 SG_ LKAIC_AdbWngLn : 17|2@0+ (1,0) [0|3] ""  CGM_LS,BCM_LS
 SG_ LKAIC_Ind2 : 18|1@0+ (1,0) [0|1] ""  CGM_LS,BCM_LS
 SG_ LKAIC_Ind1 : 19|1@0+ (1,0) [0|1] ""  CGM_LS,BCM_LS
 SG_ LKAIC_IndReq : 21|2@0+ (1,0) [0|3] ""  CGM_LS,BCM_LS
 SG_ SrvcLaneDepWrnSysIO : 2|1@0+ (1,0) [0|1] ""  CGM_LS,BCM_LS
 SG_ LDWIC_LnDepWAWLn : 9|2@0+ (1,0) [0|3] ""  CGM_LS,BCM_LS
 SG_ LDWIC_Ind2 : 10|1@0+ (1,0) [0|1] ""  CGM_LS,BCM_LS
 SG_ LDWIC_Ind1 : 11|1@0+ (1,0) [0|1] ""  CGM_LS,BCM_LS
 SG_ LDWIC_IndReq : 13|2@0+ (1,0) [0|3] ""  CGM_LS,BCM_LS

BO_ 2154971136 Front_Seat_Heat_Cool_Switches_LS: 1 CGM_LS
 SG_ PassHCSeatSw3Act : 5|1@0+ (1,0) [0|1] ""  MSM_LS,BCM_LS
 SG_ PassHCSeatSw2Act : 4|1@0+ (1,0) [0|1] ""  MSM_LS,BCM_LS
 SG_ PassHCSeatSw1Act : 3|1@0+ (1,0) [0|1] ""  MSM_LS,BCM_LS
 SG_ DrvHCSeatSw3Act : 2|1@0+ (1,0) [0|1] ""  MSM_LS,BCM_LS
 SG_ DrvHCSeatSw2Act : 1|1@0+ (1,0) [0|1] ""  MSM_LS,BCM_LS
 SG_ DrvHCSeatSw1Act : 0|1@0+ (1,0) [0|1] ""  MSM_LS,BCM_LS

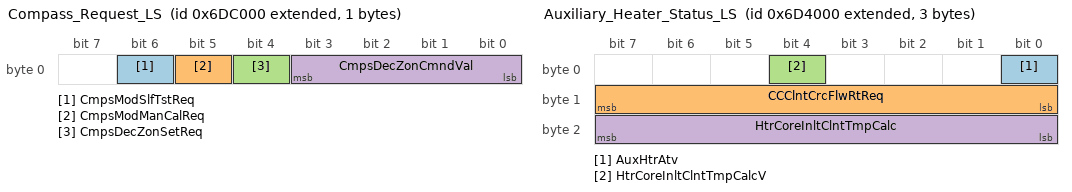
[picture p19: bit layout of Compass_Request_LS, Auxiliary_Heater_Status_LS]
BO_ 2154676224 Compass_Request_LS: 1 CGM_LS
 SG_ CmpsModSlfTstReq : 6|1@0+ (1,0) [0|1] ""  BCM_LS
 SG_ CmpsModManCalReq : 5|1@0+ (1,0) [0|1] ""  BCM_LS
 SG_ CmpsDecZonSetReq : 4|1@0+ (1,0) [0|1] ""  BCM_LS
 SG_ CmpsDecZonCmndVal : 3|4@0+ (1,0) [0|15] ""  BCM_LS

BO_ 2154643456 Auxiliary_Heater_Status_LS: 3 ECC_LS
 SG_ AuxHtrAtv : 0|1@0+ (1,0) [0|1] ""  CGM_LS,BCM_LS
 SG_ CCClntCrcFlwRtReq : 15|8@0+ (0.392157,0) [0|100.000035] "%"  CGM_LS,BSM_LS,BCM_LS
 SG_ HtrCoreInltClntTmpCalcV : 4|1@0+ (1,0) [0|1] ""  CGM_LS,BSM_LS
 SG_ HtrCoreInltClntTmpCalc : 23|8@0+ (1,-40) [-40|215] "deg C"  CGM_LS,BSM_LS

BO_TX_BU_ 2154971136 : ECC_LS,CGM_LS;
CM_ SG_ 2155216896 SpdLmtRecmndSpd "Seperate signal 'Speed Limit Units' must be used to define selectable units for this signal";
CM_ SG_ 2155216896 SpdLmtPstdSpd "Seperate signal 'Speed Limit Units' must be used to define selectable units for this signal";
CM_ SG_ 2155216896 SpdLmtUnits "This signal indicates the units used for the Speed Limit Posted Speed and Speed Limit Recommended Speed signals";
CM_ SG_ 2150277120 PsngSysLong "The units of the data are milli-arcseconds (1/3,600,000 of a degree).  The actual 'usable' range of this data is somewhat less than the encoded range (+/- 648,000,000, corresponding to +/- 180 degrees)";
CM_ SG_ 2150277120 PsngSysLat "The units of the data are milli-arcseconds (1/3,600,000 of a degree).  The actual 'usable' range of this data is somewhat less than the encoded range (+/- 324,000,000, corresponding to +/- 90 degrees)";
CM_ SG_ 2150285312 PsngSysHding "The 'usable' range is somewhat less than the encoded range (0.0 to 359.9 degrees).  0.0 degrees represents North, 90.0 degrees represents East.";
CM_ SG_ 2158878720 ODDLC_SubIdReqM "ODI-The number of list entries, starting at the Index, to send";
CM_ SG_ 2158878720 ODDLC_WrpArnd "ODI-Boolean that shall be set to true if the list shall wrap around.";
CM_ SG_ 2158878720 ODDLC_ReqType "ODI - Type of Request";
CM_ SG_ 2158878720 ODDLC_ReqDir "ODI-Boolean that shall be set to true if req down, set to false if set to up";
CM_ SG_ 2158878720 ODDLC_NmEntries "ODI-The number of list entries, starting at the Index, to send";
CM_ SG_ 2158878720 ODDLC_Idx "ODI-The index within the remote FU’s list at which to start sending data";
CM_ SG_ 2158878720 ODDLC_FUCID "ODI - Primary ID of Functional Unit in FU Database";
CM_ SG_ 2158878720 ODDLC_DspMID "ODI - ID that identifies the display requesting the data.  See detailed requirements in ODI GMLAN Protocol.";
CM_ SG_ 2158878720 ODDLC_DataId "ODI-Data Id for the dynamic list";
CM_ SG_ 2158878720 ODDLC_BckgndFlag "ODI-Informs FU as to priority of response.
Applies to all DataIds in the message.
$0=Immediate response required
$1=Background response";
CM_ SG_ 2154643456 AuxHtrAtv "Auxiliary Heater shall be used to denote a heater function that uses some kind of power, electrical or mechanical,  that was generated by the engine.";
BA_DEF_ SG_  "VNSigDiagnostic" ENUM  "No","Yes","DLCLS","DLCHS","DLCCE","DLCFO";
BA_DEF_ SG_  "VNSigUnused_4" ENUM  "No","Yes","DLCLS","DLCHS","DLCCE","DLCFO";
BA_DEF_ SG_  "VNSigIntermediate" ENUM  "No","Yes","DLCLS","DLCHS","DLCCE","DLCFO";
BA_DEF_ SG_  "VNSigParkedVehicle" ENUM  "No","Yes","DLCLS","DLCHS","DLCCE","DLCFO";
BA_DEF_ SG_  "VNSigRemoteDiagnostics" ENUM  "No","Yes","DLCLS","DLCHS","DLCCE","DLCFO";
BA_DEF_ SG_  "GenSigSendOnInit" ENUM  "Not Initialized","Application","Handler","DLCLS","DLCHS","DLCCE","DLCFO";
BA_DEF_ SG_  "GenSigSendType" ENUM  "not used","not used","not used","not used","not used","not used","not used","NoSigSendType","not used","not used","OnAnyChange","OnChangeIfActive","OnDelta","DLCLS","DLCHS","DLCCE","DLCFO";
BA_DEF_ SG_  "GenSigInactiveValue" INT 0 0;
BA_DEF_ SG_  "GenSigDeltaValue" INT 0 0;
BA_DEF_ SG_  "VNSigAllNodes" ENUM  "No","Yes","DLCLS","DLCHS","DLCCE","DLCFO";
BA_DEF_ SG_  "SignalType" STRING ;
BA_DEF_ SG_  "PacketOrder" INT 0 65535;
BA_DEF_ SG_  "SignalLongName" STRING ;
BA_DEF_ SG_  "GenSigStartValue" INT 0 65535;
BA_DEF_ SG_  "TxSignalSendOnInit" ENUM  "Not Initialized","Application","Handler";
BA_DEF_ BO_  "GenMsgILSupport" ENUM  "No","Yes","DLCLS","DLCHS","DLCCE","DLCFO";
BA_DEF_ BO_  "TpApplType" STRING ;
BA_DEF_ BO_  "Prio" INT 0 7;
BA_DEF_ BO_  "MessageSubnet" ENUM  "LS","MS","HS","CE","PE","HV","FO","S1","HE","LE","HE2","DLCLS","DLCHS","DLCCE","DLCFO","vector_leerstring";
BA_DEF_ BO_  "DiagState" ENUM  "No","Yes";
BA_DEF_ BO_  "GenMsgIlSupport" ENUM  "No","Yes";
BA_DEF_ BO_  "GenMsgStartDelayTime" INT 0 100000;
BA_DEF_ BO_  "GenMsgDelayTime" INT 0 100000;
BA_DEF_ BO_  "GenMsgCycleTime" INT 0 100000;
BA_DEF_ BO_  "GenMsgSendType" ENUM  "cyclicX","spontanX","cyclicIfActiveX","spontanWithDelay","cyclicAndSpontanX","cyclicAndSpontanWithDelay","spontanWithRepitition","cyclicIfActiveAndSpontanWD";
BA_DEF_ BO_  "DiagResponse" ENUM  "No","Yes";
BA_DEF_ BO_  "DiagRequest" ENUM  "No","Yes";
BA_DEF_ BO_  "NmMessage" ENUM  "No","Yes";
BA_DEF_REL_ BU_SG_REL_  "GenSigSuprvResp" ENUM  "None","Notify App","Substitute Default","DLCLS","DLCHS","DLCCE","DLCFO";
BA_DEF_REL_ BU_SG_REL_  "GenSigSuprvRespSubValue" INT 0 65535;
BA_DEF_REL_ BU_SG_REL_  "GenSigRxStartValue" STRING ;
BA_DEF_REL_ BU_SG_REL_  "GenSigVDAFailResp" ENUM  "No","Yes","DLCLS","DLCHS","DLCCE","DLCFO";
BA_DEF_REL_ BU_SG_REL_  "GenSigVDAFailComment" STRING ;
BA_DEF_REL_ BU_SG_REL_  "GenSigVBitRespComment" STRING ;
BA_DEF_REL_ BU_SG_REL_  "GenSigVBitResp" ENUM  "No","Yes","DLCLS","DLCHS","DLCCE","DLCFO";
BA_DEF_REL_ BU_SG_REL_  "GenSigSuprvRespComment" STRING ;
BA_DEF_REL_ BU_SG_REL_  "GenSigTimeoutTime" INT 0 5000;
BA_DEF_DEF_  "VNSigDiagnostic" "No";
BA_DEF_DEF_  "VNSigUnused_4" "No";
BA_DEF_DEF_  "VNSigIntermediate" "No";
BA_DEF_DEF_  "VNSigParkedVehicle" "No";
BA_DEF_DEF_  "VNSigRemoteDiagnostics" "No";
BA_DEF_DEF_  "GenSigSendOnInit" "Not Initialized";
BA_DEF_DEF_  "GenSigSendType" "NoSigSendType";
BA_DEF_DEF_  "GenSigInactiveValue" 0;
BA_DEF_DEF_  "GenSigDeltaValue" 0;
BA_DEF_DEF_  "VNSigAllNodes" "No";
BA_DEF_DEF_  "SignalType" "";
BA_DEF_DEF_  "PacketOrder" 0;
BA_DEF_DEF_  "SignalLongName" "";
BA_DEF_DEF_  "GenSigStartValue" 0;
BA_DEF_DEF_  "TxSignalSendOnInit" "Not Initialized";
BA_DEF_DEF_  "GenMsgILSupport" "Yes";
BA_DEF_DEF_  "TpApplType" "";
BA_DEF_DEF_  "Prio" 0;
BA_DEF_DEF_  "MessageSubnet" "LS";
BA_DEF_DEF_  "DiagState" "No";
BA_DEF_DEF_  "GenMsgIlSupport" "Yes";
BA_DEF_DEF_  "GenMsgStartDelayTime" 0;
BA_DEF_DEF_  "GenMsgDelayTime" 0;
BA_DEF_DEF_  "GenMsgCycleTime" 0;
BA_DEF_DEF_  "GenMsgSendType" "spontanX";
BA_DEF_DEF_  "DiagResponse" "No";
BA_DEF_DEF_  "DiagRequest" "No";
BA_DEF_DEF_  "NmMessage" "No";
BA_DEF_DEF_REL_ "GenSigSuprvResp" "None";
BA_DEF_DEF_REL_ "GenSigSuprvRespSubValue" 0;
BA_DEF_DEF_REL_ "GenSigRxStartValue" "";
BA_DEF_DEF_REL_ "GenSigVDAFailResp" "No";
BA_DEF_DEF_REL_ "GenSigVDAFailComment" "";
BA_DEF_DEF_REL_ "GenSigVBitRespComment" "";
BA_DEF_DEF_REL_ "GenSigVBitResp" "No";
BA_DEF_DEF_REL_ "GenSigSuprvRespComment" "";
BA_DEF_DEF_REL_ "GenSigTimeoutTime" 0;
BA_ "Prio" BO_ 2154954752 4;
BA_ "GenMsgDelayTime" BO_ 2154954752 100;
BA_ "Prio" BO_ 2153848832 4;
BA_ "GenMsgDelayTime" BO_ 2153848832 100;
BA_ "Prio" BO_ 2153832448 4;
BA_ "GenMsgDelayTime" BO_ 2153832448 100;
BA_ "Prio" BO_ 2150244352 4;
BA_ "GenMsgDelayTime" BO_ 2150244352 100;
BA_ "Prio" BO_ 2150252544 4;
BA_ "GenMsgDelayTime" BO_ 2150252544 100;
BA_ "Prio" BO_ 2153308160 4;
BA_ "GenMsgStartDelayTime" BO_ 2153308160 100;
BA_ "GenMsgCycleTime" BO_ 2153308160 1000;
BA_ "GenMsgSendType" BO_ 2153308160 0;
BA_ "Prio" BO_ 2153914368 4;
BA_ "GenMsgDelayTime" BO_ 2153914368 100;
BA_ "Prio" BO_ 2150580224 4;
BA_ "GenMsgDelayTime" BO_ 2150580224 100;
BA_ "Prio" BO_ 2150080512 4;
BA_ "GenMsgDelayTime" BO_ 2150080512 100;
BA_ "Prio" BO_ 2150383616 4;
BA_ "GenMsgDelayTime" BO_ 2150383616 100;
BA_ "Prio" BO_ 2151981056 4;
BA_ "GenMsgDelayTime" BO_ 2151981056 100;
BA_ "Prio" BO_ 2151964672 4;
BA_ "GenMsgDelayTime" BO_ 2151964672 100;
BA_ "Prio" BO_ 2150055936 4;
BA_ "GenMsgDelayTime" BO_ 2150055936 100;
BA_ "Prio" BO_ 2150039552 4;
BA_ "GenMsgDelayTime" BO_ 2150039552 100;
BA_ "Prio" BO_ 2151809024 4;
BA_ "GenMsgDelayTime" BO_ 2151809024 100;
BA_ "Prio" BO_ 2151858176 4;
BA_ "GenMsgDelayTime" BO_ 2151858176 100;
BA_ "Prio" BO_ 2150023168 4;
BA_ "GenMsgCycleTime" BO_ 2150023168 250;
BA_ "GenMsgSendType" BO_ 2150023168 0;
BA_ "Prio" BO_ 2153988096 4;
BA_ "GenMsgDelayTime" BO_ 2153988096 100;
BA_ "GenMsgILSupport" BO_ 1516 0;
BA_ "TpApplType" BO_ 1516 "DiagUUDTResponse";
BA_ "Prio" BO_ 2155233280 4;
BA_ "GenMsgDelayTime" BO_ 2155233280 100;
BA_ "DiagResponse" BO_ 2028 1;
BA_ "Prio" BO_ 2150121472 4;
BA_ "GenMsgDelayTime" BO_ 2150121472 100;
BA_ "Prio" BO_ 2150105088 4;
BA_ "GenMsgDelayTime" BO_ 2150105088 100;
BA_ "Prio" BO_ 2152013824 4;
BA_ "GenMsgDelayTime" BO_ 2152013824 100;
BA_ "Prio" BO_ 2159255552 4;
BA_ "GenMsgDelayTime" BO_ 2159255552 10;
BA_ "Prio" BO_ 2151817216 4;
BA_ "GenMsgDelayTime" BO_ 2151817216 20;
BA_ "Prio" BO_ 2151849984 4;
BA_ "GenMsgDelayTime" BO_ 2151849984 250;
BA_ "Prio" BO_ 2154618880 4;
BA_ "GenMsgCycleTime" BO_ 2154618880 1000;
BA_ "GenMsgSendType" BO_ 2154618880 0;
BA_ "Prio" BO_ 2150129664 4;
BA_ "GenMsgDelayTime" BO_ 2150129664 100;
BA_ "Prio" BO_ 2155216896 4;
BA_ "GenMsgDelayTime" BO_ 2155216896 100;
BA_ "Prio" BO_ 2150277120 4;
BA_ "GenMsgDelayTime" BO_ 2150277120 100;
BA_ "Prio" BO_ 2150285312 4;
BA_ "GenMsgDelayTime" BO_ 2150285312 100;
BA_ "Prio" BO_ 2151047168 4;
BA_ "GenMsgDelayTime" BO_ 2151047168 100;
BA_ "Prio" BO_ 2154225664 3;
BA_ "GenMsgDelayTime" BO_ 2154225664 100;
BA_ "Prio" BO_ 2149900288 4;
BA_ "GenMsgDelayTime" BO_ 2149900288 100;
BA_ "Prio" BO_ 2157985792 4;
BA_ "GenMsgDelayTime" BO_ 2157985792 100;
BA_ "Prio" BO_ 2155479040 4;
BA_ "GenMsgDelayTime" BO_ 2155479040 100;
BA_ "Prio" BO_ 2151383040 4;
BA_ "GenMsgDelayTime" BO_ 2151383040 100;
BA_ "Prio" BO_ 2155421696 3;
BA_ "GenMsgDelayTime" BO_ 2155421696 100;
BA_ "Prio" BO_ 2151972864 4;
BA_ "GenMsgDelayTime" BO_ 2151972864 100;
BA_ "Prio" BO_ 2156789760 4;
BA_ "GenMsgDelayTime" BO_ 2156789760 100;
BA_ "Prio" BO_ 2155298816 4;
BA_ "GenMsgDelayTime" BO_ 2155298816 100;
BA_ "Prio" BO_ 2158878720 4;
BA_ "GenMsgDelayTime" BO_ 2158878720 20;
BA_ "Prio" BO_ 2153938944 4;
BA_ "GenMsgDelayTime" BO_ 2153938944 100;
BA_ "Prio" BO_ 2150662144 4;
BA_ "GenMsgDelayTime" BO_ 2150662144 100;
BA_ "Prio" BO_ 2150653952 4;
BA_ "GenMsgDelayTime" BO_ 2150653952 100;
BA_ "Prio" BO_ 2153922560 4;
BA_ "GenMsgDelayTime" BO_ 2153922560 100;
BA_ "Prio" BO_ 2153807872 3;
BA_ "GenMsgDelayTime" BO_ 2153807872 100;
BA_ "Prio" BO_ 2151399424 4;
BA_ "GenMsgDelayTime" BO_ 2151399424 100;
BA_ "Prio" BO_ 2151940096 4;
BA_ "GenMsgDelayTime" BO_ 2151940096 100;
BA_ "Prio" BO_ 2151923712 4;
BA_ "GenMsgDelayTime" BO_ 2151923712 100;
BA_ "Prio" BO_ 2150645760 4;
BA_ "GenMsgDelayTime" BO_ 2150645760 100;
BA_ "Prio" BO_ 2152464384 4;
BA_ "GenMsgDelayTime" BO_ 2152464384 100;
BA_ "Prio" BO_ 2154971136 4;
BA_ "GenMsgDelayTime" BO_ 2154971136 100;
BA_ "Prio" BO_ 2154676224 4;
BA_ "GenMsgDelayTime" BO_ 2154676224 100;
BA_ "Prio" BO_ 2154643456 4;
BA_ "GenMsgDelayTime" BO_ 2154643456 100;
BA_ "GenSigSendType" SG_ 2154954752 ACCWPwrdRmStPwrLmt 12;
BA_ "GenSigDeltaValue" SG_ 2154954752 ACCWPwrdRmStPwrLmt 1;
BA_ "VNSigAllNodes" SG_ 2154954752 ACCWPwrdRmStPwrLmt 1;
BA_ "SignalType" SG_ 2154954752 ACCWPwrdRmStPwrLmt "UNM";
BA_ "SignalLongName" SG_ 2154954752 ACCWPwrdRmStPwrLmt "Air Conditioning Compressor Wall Powered Remote Start Power Limit";
BA_ "GenSigSendType" SG_ 2154954752 WPwrdRmStEnbld 10;
BA_ "VNSigAllNodes" SG_ 2154954752 WPwrdRmStEnbld 1;
BA_ "SignalType" SG_ 2154954752 WPwrdRmStEnbld "BLN";
BA_ "SignalLongName" SG_ 2154954752 WPwrdRmStEnbld "Wall Powered Remote Start Enabled";
BA_ "GenSigSendType" SG_ 2154954752 HtdStWhlInd 10;
BA_ "VNSigAllNodes" SG_ 2154954752 HtdStWhlInd 1;
BA_ "SignalType" SG_ 2154954752 HtdStWhlInd "ENM";
BA_ "SignalLongName" SG_ 2154954752 HtdStWhlInd "Heated Steering Wheel Indication";
BA_ "GenSigSendType" SG_ 2154954752 HtdStWhlCtrlSrc 10;
BA_ "VNSigAllNodes" SG_ 2154954752 HtdStWhlCtrlSrc 1;
BA_ "SignalType" SG_ 2154954752 HtdStWhlCtrlSrc "ENM";
BA_ "SignalLongName" SG_ 2154954752 HtdStWhlCtrlSrc "Heated Steering Wheel Control Source";
BA_ "GenSigSendType" SG_ 2154954752 HtdStWhlCmd 10;
BA_ "VNSigAllNodes" SG_ 2154954752 HtdStWhlCmd 1;
BA_ "SignalType" SG_ 2154954752 HtdStWhlCmd "ENM";
BA_ "SignalLongName" SG_ 2154954752 HtdStWhlCmd "Heated Steering Wheel Command";
BA_ "GenSigSendType" SG_ 2154954752 ClmtHtPwrRqd 10;
BA_ "VNSigAllNodes" SG_ 2154954752 ClmtHtPwrRqd 1;
BA_ "SignalType" SG_ 2154954752 ClmtHtPwrRqd "BLN";
BA_ "SignalLongName" SG_ 2154954752 ClmtHtPwrRqd "Climate Heating Power Required";
BA_ "GenSigSendType" SG_ 2154954752 EstACCompPwrRchCbnCmf 12;
BA_ "GenSigDeltaValue" SG_ 2154954752 EstACCompPwrRchCbnCmf 1;
BA_ "VNSigAllNodes" SG_ 2154954752 EstACCompPwrRchCbnCmf 1;
BA_ "SignalType" SG_ 2154954752 EstACCompPwrRchCbnCmf "UNM";
BA_ "SignalLongName" SG_ 2154954752 EstACCompPwrRchCbnCmf "Estimated Air Conditioning Control Power to Reach Cabin Comfort";
BA_ "GenSigSendType" SG_ 2154954752 EstACCompPwrMtnCbnCmf 12;
BA_ "GenSigDeltaValue" SG_ 2154954752 EstACCompPwrMtnCbnCmf 1;
BA_ "VNSigAllNodes" SG_ 2154954752 EstACCompPwrMtnCbnCmf 1;
BA_ "SignalType" SG_ 2154954752 EstACCompPwrMtnCbnCmf "UNM";
BA_ "SignalLongName" SG_ 2154954752 EstACCompPwrMtnCbnCmf "Estimated Air Conditioning Control Power to Maintain Cabin Comfort";
BA_ "GenSigSendOnInit" SG_ 2153848832 EUSSE_MaxBarDspRng 1;
BA_ "GenSigSendType" SG_ 2153848832 EUSSE_MaxBarDspRng 12;
BA_ "GenSigDeltaValue" SG_ 2153848832 EUSSE_MaxBarDspRng 1;
BA_ "VNSigAllNodes" SG_ 2153848832 EUSSE_MaxBarDspRng 1;
BA_ "SignalType" SG_ 2153848832 EUSSE_MaxBarDspRng "UNM";
BA_ "PacketOrder" SG_ 2153848832 EUSSE_MaxBarDspRng 9;
BA_ "SignalLongName" SG_ 2153848832 EUSSE_MaxBarDspRng "Energy Usage Score Scaling Extended : Maximum Bar Display Range";
BA_ "GenSigSendOnInit" SG_ 2153848832 EUSSE_ITEgUgScrMxScVal 1;
BA_ "GenSigSendType" SG_ 2153848832 EUSSE_ITEgUgScrMxScVal 12;
BA_ "GenSigDeltaValue" SG_ 2153848832 EUSSE_ITEgUgScrMxScVal 1;
BA_ "VNSigAllNodes" SG_ 2153848832 EUSSE_ITEgUgScrMxScVal 1;
BA_ "SignalType" SG_ 2153848832 EUSSE_ITEgUgScrMxScVal "UNM";
BA_ "PacketOrder" SG_ 2153848832 EUSSE_ITEgUgScrMxScVal 8;
BA_ "SignalLongName" SG_ 2153848832 EUSSE_ITEgUgScrMxScVal "Energy Usage Score Scaling Extended : Inside Temperature Energy Usage Score Maximum Scale Value";
BA_ "GenSigSendOnInit" SG_ 2153848832 EUSSE_TrEgUgScrMxScVal 1;
BA_ "GenSigSendType" SG_ 2153848832 EUSSE_TrEgUgScrMxScVal 12;
BA_ "GenSigDeltaValue" SG_ 2153848832 EUSSE_TrEgUgScrMxScVal 1;
BA_ "VNSigAllNodes" SG_ 2153848832 EUSSE_TrEgUgScrMxScVal 1;
BA_ "SignalType" SG_ 2153848832 EUSSE_TrEgUgScrMxScVal "UNM";
BA_ "PacketOrder" SG_ 2153848832 EUSSE_TrEgUgScrMxScVal 7;
BA_ "SignalLongName" SG_ 2153848832 EUSSE_TrEgUgScrMxScVal "Energy Usage Score Scaling Extended : Terrain Energy Usage Score Maximum Scale Value";
BA_ "GenSigSendOnInit" SG_ 2153848832 EUSSE_TcEgUgScrMxScVal 1;
BA_ "GenSigSendType" SG_ 2153848832 EUSSE_TcEgUgScrMxScVal 12;
BA_ "GenSigDeltaValue" SG_ 2153848832 EUSSE_TcEgUgScrMxScVal 1;
BA_ "VNSigAllNodes" SG_ 2153848832 EUSSE_TcEgUgScrMxScVal 1;
BA_ "SignalType" SG_ 2153848832 EUSSE_TcEgUgScrMxScVal "UNM";
BA_ "PacketOrder" SG_ 2153848832 EUSSE_TcEgUgScrMxScVal 6;
BA_ "SignalLongName" SG_ 2153848832 EUSSE_TcEgUgScrMxScVal "Energy Usage Score Scaling Extended : Technique Energy Usage Score Maximum Scale Value";
BA_ "GenSigSendOnInit" SG_ 2153848832 EUSSE_OTEgUgScrMxScVal 1;
BA_ "GenSigSendType" SG_ 2153848832 EUSSE_OTEgUgScrMxScVal 12;
BA_ "GenSigDeltaValue" SG_ 2153848832 EUSSE_OTEgUgScrMxScVal 1;
BA_ "VNSigAllNodes" SG_ 2153848832 EUSSE_OTEgUgScrMxScVal 1;
BA_ "SignalType" SG_ 2153848832 EUSSE_OTEgUgScrMxScVal "UNM";
BA_ "PacketOrder" SG_ 2153848832 EUSSE_OTEgUgScrMxScVal 5;
BA_ "SignalLongName" SG_ 2153848832 EUSSE_OTEgUgScrMxScVal "Energy Usage Score Scaling Extended : Outside Temperature Energy Usage Score Maximum Scale Value";
BA_ "GenSigSendOnInit" SG_ 2153848832 EUSSE_TrEgUgScrMnScVal 1;
BA_ "GenSigSendType" SG_ 2153848832 EUSSE_TrEgUgScrMnScVal 12;
BA_ "GenSigDeltaValue" SG_ 2153848832 EUSSE_TrEgUgScrMnScVal 1;
BA_ "VNSigAllNodes" SG_ 2153848832 EUSSE_TrEgUgScrMnScVal 1;
BA_ "SignalType" SG_ 2153848832 EUSSE_TrEgUgScrMnScVal "SNM";
BA_ "PacketOrder" SG_ 2153848832 EUSSE_TrEgUgScrMnScVal 4;
BA_ "SignalLongName" SG_ 2153848832 EUSSE_TrEgUgScrMnScVal "Energy Usage Score Scaling Extended : Terrain Energy Usage Score Minimum Scale Value";
BA_ "GenSigSendOnInit" SG_ 2153848832 EUSSE_TcEgUgScrMnScVal 1;
BA_ "GenSigSendType" SG_ 2153848832 EUSSE_TcEgUgScrMnScVal 12;
BA_ "GenSigDeltaValue" SG_ 2153848832 EUSSE_TcEgUgScrMnScVal 1;
BA_ "VNSigAllNodes" SG_ 2153848832 EUSSE_TcEgUgScrMnScVal 1;
BA_ "SignalType" SG_ 2153848832 EUSSE_TcEgUgScrMnScVal "SNM";
BA_ "PacketOrder" SG_ 2153848832 EUSSE_TcEgUgScrMnScVal 3;
BA_ "SignalLongName" SG_ 2153848832 EUSSE_TcEgUgScrMnScVal "Energy Usage Score Scaling Extended : Technique Energy Usage Score Minimum Scale Value";
BA_ "GenSigSendOnInit" SG_ 2153848832 EUSSE_OTEgUgScrMnScVal 1;
BA_ "GenSigSendType" SG_ 2153848832 EUSSE_OTEgUgScrMnScVal 12;
BA_ "GenSigDeltaValue" SG_ 2153848832 EUSSE_OTEgUgScrMnScVal 1;
BA_ "VNSigAllNodes" SG_ 2153848832 EUSSE_OTEgUgScrMnScVal 1;
BA_ "SignalType" SG_ 2153848832 EUSSE_OTEgUgScrMnScVal "SNM";
BA_ "PacketOrder" SG_ 2153848832 EUSSE_OTEgUgScrMnScVal 2;
BA_ "SignalLongName" SG_ 2153848832 EUSSE_OTEgUgScrMnScVal "Energy Usage Score Scaling Extended : Outside Temperature Energy Usage Score Minimum Scale Value";
BA_ "GenSigSendOnInit" SG_ 2153848832 EUSSE_ITEgUgScrMnScVal 1;
BA_ "GenSigSendType" SG_ 2153848832 EUSSE_ITEgUgScrMnScVal 12;
BA_ "GenSigDeltaValue" SG_ 2153848832 EUSSE_ITEgUgScrMnScVal 1;
BA_ "VNSigAllNodes" SG_ 2153848832 EUSSE_ITEgUgScrMnScVal 1;
BA_ "SignalType" SG_ 2153848832 EUSSE_ITEgUgScrMnScVal "SNM";
BA_ "PacketOrder" SG_ 2153848832 EUSSE_ITEgUgScrMnScVal 1;
BA_ "SignalLongName" SG_ 2153848832 EUSSE_ITEgUgScrMnScVal "Energy Usage Score Scaling Extended : Inside Temperature Energy Usage Score Minimum Scale Value";
BA_ "GenSigSendOnInit" SG_ 2153832448 EUSE_TtEngyUsgScrAvVal 1;
BA_ "GenSigSendType" SG_ 2153832448 EUSE_TtEngyUsgScrAvVal 12;
BA_ "GenSigDeltaValue" SG_ 2153832448 EUSE_TtEngyUsgScrAvVal 1;
BA_ "VNSigAllNodes" SG_ 2153832448 EUSE_TtEngyUsgScrAvVal 1;
BA_ "SignalType" SG_ 2153832448 EUSE_TtEngyUsgScrAvVal "SNM";
BA_ "PacketOrder" SG_ 2153832448 EUSE_TtEngyUsgScrAvVal 5;
BA_ "SignalLongName" SG_ 2153832448 EUSE_TtEngyUsgScrAvVal "Energy Usage Score Extended : Total Energy Usage Score Value";
BA_ "GenSigSendOnInit" SG_ 2153832448 EUSE_TrEngyUsgScrAvVal 1;
BA_ "GenSigSendType" SG_ 2153832448 EUSE_TrEngyUsgScrAvVal 12;
BA_ "GenSigDeltaValue" SG_ 2153832448 EUSE_TrEngyUsgScrAvVal 1;
BA_ "VNSigAllNodes" SG_ 2153832448 EUSE_TrEngyUsgScrAvVal 1;
BA_ "SignalType" SG_ 2153832448 EUSE_TrEngyUsgScrAvVal "SNM";
BA_ "PacketOrder" SG_ 2153832448 EUSE_TrEngyUsgScrAvVal 4;
BA_ "SignalLongName" SG_ 2153832448 EUSE_TrEngyUsgScrAvVal "Energy Usage Score Extended : Terrain Energy Usage Score Average Value";
BA_ "GenSigSendOnInit" SG_ 2153832448 EUSE_TcEngyUsgScrAvVal 1;
BA_ "GenSigSendType" SG_ 2153832448 EUSE_TcEngyUsgScrAvVal 12;
BA_ "GenSigDeltaValue" SG_ 2153832448 EUSE_TcEngyUsgScrAvVal 1;
BA_ "VNSigAllNodes" SG_ 2153832448 EUSE_TcEngyUsgScrAvVal 1;
BA_ "SignalType" SG_ 2153832448 EUSE_TcEngyUsgScrAvVal "SNM";
BA_ "PacketOrder" SG_ 2153832448 EUSE_TcEngyUsgScrAvVal 3;
BA_ "SignalLongName" SG_ 2153832448 EUSE_TcEngyUsgScrAvVal "Energy Usage Score Extended : Technique Energy Usage Score Average Value";
BA_ "GenSigSendOnInit" SG_ 2153832448 EUSE_OTEngyUsgScrAvVal 1;
BA_ "GenSigSendType" SG_ 2153832448 EUSE_OTEngyUsgScrAvVal 12;
BA_ "GenSigDeltaValue" SG_ 2153832448 EUSE_OTEngyUsgScrAvVal 1;
BA_ "VNSigAllNodes" SG_ 2153832448 EUSE_OTEngyUsgScrAvVal 1;
BA_ "SignalType" SG_ 2153832448 EUSE_OTEngyUsgScrAvVal "SNM";
BA_ "PacketOrder" SG_ 2153832448 EUSE_OTEngyUsgScrAvVal 2;
BA_ "SignalLongName" SG_ 2153832448 EUSE_OTEngyUsgScrAvVal "Energy Usage Score Extended : Outside Temperature Energy Usage Score Average Value";
BA_ "GenSigSendOnInit" SG_ 2153832448 EUSE_ITEngyUsgScrAvVal 1;
BA_ "GenSigSendType" SG_ 2153832448 EUSE_ITEngyUsgScrAvVal 12;
BA_ "GenSigDeltaValue" SG_ 2153832448 EUSE_ITEngyUsgScrAvVal 1;
BA_ "VNSigAllNodes" SG_ 2153832448 EUSE_ITEngyUsgScrAvVal 1;
BA_ "SignalType" SG_ 2153832448 EUSE_ITEngyUsgScrAvVal "SNM";
BA_ "PacketOrder" SG_ 2153832448 EUSE_ITEngyUsgScrAvVal 1;
BA_ "SignalLongName" SG_ 2153832448 EUSE_ITEngyUsgScrAvVal "Energy Usage Score Extended : Inside Temperature Energy Usage Score Average Value";
BA_ "GenSigSendOnInit" SG_ 2150244352 ECHGDDV_Col10 1;
BA_ "GenSigSendType" SG_ 2150244352 ECHGDDV_Col10 12;
BA_ "GenSigDeltaValue" SG_ 2150244352 ECHGDDV_Col10 1;
BA_ "VNSigAllNodes" SG_ 2150244352 ECHGDDV_Col10 1;
BA_ "SignalType" SG_ 2150244352 ECHGDDV_Col10 "UNM";
BA_ "PacketOrder" SG_ 2150244352 ECHGDDV_Col10 11;
BA_ "SignalLongName" SG_ 2150244352 ECHGDDV_Col10 "Energy Consumption History Graph Display Data Values : Column 10";
BA_ "GenSigSendOnInit" SG_ 2150244352 ECHGDDV_Col9 1;
BA_ "GenSigSendType" SG_ 2150244352 ECHGDDV_Col9 12;
BA_ "GenSigDeltaValue" SG_ 2150244352 ECHGDDV_Col9 1;
BA_ "VNSigAllNodes" SG_ 2150244352 ECHGDDV_Col9 1;
BA_ "SignalType" SG_ 2150244352 ECHGDDV_Col9 "UNM";
BA_ "PacketOrder" SG_ 2150244352 ECHGDDV_Col9 10;
BA_ "SignalLongName" SG_ 2150244352 ECHGDDV_Col9 "Energy Consumption History Graph Display Data Values : Column 09";
BA_ "GenSigSendOnInit" SG_ 2150244352 ECHGDDV_Col8 1;
BA_ "GenSigSendType" SG_ 2150244352 ECHGDDV_Col8 12;
BA_ "GenSigDeltaValue" SG_ 2150244352 ECHGDDV_Col8 1;
BA_ "VNSigAllNodes" SG_ 2150244352 ECHGDDV_Col8 1;
BA_ "SignalType" SG_ 2150244352 ECHGDDV_Col8 "UNM";
BA_ "PacketOrder" SG_ 2150244352 ECHGDDV_Col8 9;
BA_ "SignalLongName" SG_ 2150244352 ECHGDDV_Col8 "Energy Consumption History Graph Display Data Values : Column 08";
BA_ "GenSigSendOnInit" SG_ 2150244352 ECHGDDV_Col7 1;
BA_ "GenSigSendType" SG_ 2150244352 ECHGDDV_Col7 12;
BA_ "GenSigDeltaValue" SG_ 2150244352 ECHGDDV_Col7 1;
BA_ "VNSigAllNodes" SG_ 2150244352 ECHGDDV_Col7 1;
BA_ "SignalType" SG_ 2150244352 ECHGDDV_Col7 "UNM";
BA_ "PacketOrder" SG_ 2150244352 ECHGDDV_Col7 8;
BA_ "SignalLongName" SG_ 2150244352 ECHGDDV_Col7 "Energy Consumption History Graph Display Data Values : Column 07";
BA_ "GenSigSendOnInit" SG_ 2150244352 ECHGDDV_Col6 1;
BA_ "GenSigSendType" SG_ 2150244352 ECHGDDV_Col6 12;
BA_ "GenSigDeltaValue" SG_ 2150244352 ECHGDDV_Col6 1;
BA_ "VNSigAllNodes" SG_ 2150244352 ECHGDDV_Col6 1;
BA_ "SignalType" SG_ 2150244352 ECHGDDV_Col6 "UNM";
BA_ "PacketOrder" SG_ 2150244352 ECHGDDV_Col6 7;
BA_ "SignalLongName" SG_ 2150244352 ECHGDDV_Col6 "Energy Consumption History Graph Display Data Values : Column 06";
BA_ "GenSigSendOnInit" SG_ 2150244352 ECHGDDV_Col5 1;
BA_ "GenSigSendType" SG_ 2150244352 ECHGDDV_Col5 12;
BA_ "GenSigDeltaValue" SG_ 2150244352 ECHGDDV_Col5 1;
BA_ "VNSigAllNodes" SG_ 2150244352 ECHGDDV_Col5 1;
BA_ "SignalType" SG_ 2150244352 ECHGDDV_Col5 "UNM";
BA_ "PacketOrder" SG_ 2150244352 ECHGDDV_Col5 6;
BA_ "SignalLongName" SG_ 2150244352 ECHGDDV_Col5 "Energy Consumption History Graph Display Data Values : Column 05";
BA_ "GenSigSendOnInit" SG_ 2150244352 ECHGDDV_Col4 1;
BA_ "GenSigSendType" SG_ 2150244352 ECHGDDV_Col4 12;
BA_ "GenSigDeltaValue" SG_ 2150244352 ECHGDDV_Col4 1;
BA_ "VNSigAllNodes" SG_ 2150244352 ECHGDDV_Col4 1;
BA_ "SignalType" SG_ 2150244352 ECHGDDV_Col4 "UNM";
BA_ "PacketOrder" SG_ 2150244352 ECHGDDV_Col4 5;
BA_ "SignalLongName" SG_ 2150244352 ECHGDDV_Col4 "Energy Consumption History Graph Display Data Values : Column 04";
BA_ "GenSigSendOnInit" SG_ 2150244352 ECHGDDV_Col3 1;
BA_ "GenSigSendType" SG_ 2150244352 ECHGDDV_Col3 12;
BA_ "GenSigDeltaValue" SG_ 2150244352 ECHGDDV_Col3 1;
BA_ "VNSigAllNodes" SG_ 2150244352 ECHGDDV_Col3 1;
BA_ "SignalType" SG_ 2150244352 ECHGDDV_Col3 "UNM";
BA_ "PacketOrder" SG_ 2150244352 ECHGDDV_Col3 4;
BA_ "SignalLongName" SG_ 2150244352 ECHGDDV_Col3 "Energy Consumption History Graph Display Data Values : Column 03";
BA_ "GenSigSendOnInit" SG_ 2150244352 ECHGDDV_Col2 1;
BA_ "GenSigSendType" SG_ 2150244352 ECHGDDV_Col2 12;
BA_ "GenSigDeltaValue" SG_ 2150244352 ECHGDDV_Col2 1;
BA_ "VNSigAllNodes" SG_ 2150244352 ECHGDDV_Col2 1;
BA_ "SignalType" SG_ 2150244352 ECHGDDV_Col2 "UNM";
BA_ "PacketOrder" SG_ 2150244352 ECHGDDV_Col2 3;
BA_ "SignalLongName" SG_ 2150244352 ECHGDDV_Col2 "Energy Consumption History Graph Display Data Values : Column 02";
BA_ "GenSigSendOnInit" SG_ 2150244352 ECHGDDV_Col1 1;
BA_ "GenSigSendType" SG_ 2150244352 ECHGDDV_Col1 12;
BA_ "GenSigDeltaValue" SG_ 2150244352 ECHGDDV_Col1 1;
BA_ "VNSigAllNodes" SG_ 2150244352 ECHGDDV_Col1 1;
BA_ "SignalType" SG_ 2150244352 ECHGDDV_Col1 "UNM";
BA_ "PacketOrder" SG_ 2150244352 ECHGDDV_Col1 2;
BA_ "SignalLongName" SG_ 2150244352 ECHGDDV_Col1 "Energy Consumption History Graph Display Data Values : Column 01";
BA_ "GenSigSendOnInit" SG_ 2150244352 ECHGDDV_EngyConsAvg 1;
BA_ "GenSigSendType" SG_ 2150244352 ECHGDDV_EngyConsAvg 12;
BA_ "GenSigDeltaValue" SG_ 2150244352 ECHGDDV_EngyConsAvg 1;
BA_ "VNSigAllNodes" SG_ 2150244352 ECHGDDV_EngyConsAvg 1;
BA_ "SignalType" SG_ 2150244352 ECHGDDV_EngyConsAvg "UNM";
BA_ "PacketOrder" SG_ 2150244352 ECHGDDV_EngyConsAvg 1;
BA_ "SignalLongName" SG_ 2150244352 ECHGDDV_EngyConsAvg "Energy Consumption History Graph Display Data Values : Energy Consumed Average";
BA_ "GenSigSendOnInit" SG_ 2150252544 ECHG_YAxisMaxVal 1;
BA_ "GenSigSendType" SG_ 2150252544 ECHG_YAxisMaxVal 10;
BA_ "GenSigDeltaValue" SG_ 2150252544 ECHG_YAxisMaxVal 1;
BA_ "VNSigAllNodes" SG_ 2150252544 ECHG_YAxisMaxVal 1;
BA_ "SignalType" SG_ 2150252544 ECHG_YAxisMaxVal "ENM";
BA_ "PacketOrder" SG_ 2150252544 ECHG_YAxisMaxVal 14;
BA_ "SignalLongName" SG_ 2150252544 ECHG_YAxisMaxVal "Energy Consumption History Graph : Y Axis Maximum Value";
BA_ "GenSigSendOnInit" SG_ 2150252544 ECHG_XAxisTkMrkIntvl 1;
BA_ "GenSigSendType" SG_ 2150252544 ECHG_XAxisTkMrkIntvl 10;
BA_ "GenSigDeltaValue" SG_ 2150252544 ECHG_XAxisTkMrkIntvl 1;
BA_ "VNSigAllNodes" SG_ 2150252544 ECHG_XAxisTkMrkIntvl 1;
BA_ "SignalType" SG_ 2150252544 ECHG_XAxisTkMrkIntvl "ENM";
BA_ "PacketOrder" SG_ 2150252544 ECHG_XAxisTkMrkIntvl 13;
BA_ "SignalLongName" SG_ 2150252544 ECHG_XAxisTkMrkIntvl "Energy Consumption History Graph : X Axis Tick Mark Interval";
BA_ "GenSigSendOnInit" SG_ 2150252544 ECHG_Column10 1;
BA_ "GenSigSendType" SG_ 2150252544 ECHG_Column10 12;
BA_ "GenSigDeltaValue" SG_ 2150252544 ECHG_Column10 1;
BA_ "VNSigAllNodes" SG_ 2150252544 ECHG_Column10 1;
BA_ "SignalType" SG_ 2150252544 ECHG_Column10 "UNM";
BA_ "PacketOrder" SG_ 2150252544 ECHG_Column10 12;
BA_ "SignalLongName" SG_ 2150252544 ECHG_Column10 "Energy Consumption History Graph : Column 10";
BA_ "GenSigSendOnInit" SG_ 2150252544 ECHG_Column09 1;
BA_ "GenSigSendType" SG_ 2150252544 ECHG_Column09 12;
BA_ "GenSigDeltaValue" SG_ 2150252544 ECHG_Column09 1;
BA_ "VNSigAllNodes" SG_ 2150252544 ECHG_Column09 1;
BA_ "SignalType" SG_ 2150252544 ECHG_Column09 "UNM";
BA_ "PacketOrder" SG_ 2150252544 ECHG_Column09 11;
BA_ "SignalLongName" SG_ 2150252544 ECHG_Column09 "Energy Consumption History Graph : Column 09";
BA_ "GenSigSendOnInit" SG_ 2150252544 ECHG_Column08 1;
BA_ "GenSigSendType" SG_ 2150252544 ECHG_Column08 12;
BA_ "GenSigDeltaValue" SG_ 2150252544 ECHG_Column08 1;
BA_ "VNSigAllNodes" SG_ 2150252544 ECHG_Column08 1;
BA_ "SignalType" SG_ 2150252544 ECHG_Column08 "UNM";
BA_ "PacketOrder" SG_ 2150252544 ECHG_Column08 10;
BA_ "SignalLongName" SG_ 2150252544 ECHG_Column08 "Energy Consumption History Graph : Column 08";
BA_ "GenSigSendOnInit" SG_ 2150252544 ECHG_Column07 1;
BA_ "GenSigSendType" SG_ 2150252544 ECHG_Column07 12;
BA_ "GenSigDeltaValue" SG_ 2150252544 ECHG_Column07 1;
BA_ "VNSigAllNodes" SG_ 2150252544 ECHG_Column07 1;
BA_ "SignalType" SG_ 2150252544 ECHG_Column07 "UNM";
BA_ "PacketOrder" SG_ 2150252544 ECHG_Column07 9;
BA_ "SignalLongName" SG_ 2150252544 ECHG_Column07 "Energy Consumption History Graph : Column 07";
BA_ "GenSigSendOnInit" SG_ 2150252544 ECHG_Column06 1;
BA_ "GenSigSendType" SG_ 2150252544 ECHG_Column06 12;
BA_ "GenSigDeltaValue" SG_ 2150252544 ECHG_Column06 1;
BA_ "VNSigAllNodes" SG_ 2150252544 ECHG_Column06 1;
BA_ "SignalType" SG_ 2150252544 ECHG_Column06 "UNM";
BA_ "PacketOrder" SG_ 2150252544 ECHG_Column06 8;
BA_ "SignalLongName" SG_ 2150252544 ECHG_Column06 "Energy Consumption History Graph : Column 06";
BA_ "GenSigSendOnInit" SG_ 2150252544 ECHG_Column05 1;
BA_ "GenSigSendType" SG_ 2150252544 ECHG_Column05 12;
BA_ "GenSigDeltaValue" SG_ 2150252544 ECHG_Column05 1;
BA_ "VNSigAllNodes" SG_ 2150252544 ECHG_Column05 1;
BA_ "SignalType" SG_ 2150252544 ECHG_Column05 "UNM";
BA_ "PacketOrder" SG_ 2150252544 ECHG_Column05 7;
BA_ "SignalLongName" SG_ 2150252544 ECHG_Column05 "Energy Consumption History Graph : Column 05";
BA_ "GenSigSendOnInit" SG_ 2150252544 ECHG_Column04 1;
BA_ "GenSigSendType" SG_ 2150252544 ECHG_Column04 12;
BA_ "GenSigDeltaValue" SG_ 2150252544 ECHG_Column04 1;
BA_ "VNSigAllNodes" SG_ 2150252544 ECHG_Column04 1;
BA_ "SignalType" SG_ 2150252544 ECHG_Column04 "UNM";
BA_ "PacketOrder" SG_ 2150252544 ECHG_Column04 6;
BA_ "SignalLongName" SG_ 2150252544 ECHG_Column04 "Energy Consumption History Graph : Column 04";
BA_ "GenSigSendOnInit" SG_ 2150252544 ECHG_Column03 1;
BA_ "GenSigSendType" SG_ 2150252544 ECHG_Column03 12;
BA_ "GenSigDeltaValue" SG_ 2150252544 ECHG_Column03 1;
BA_ "VNSigAllNodes" SG_ 2150252544 ECHG_Column03 1;
BA_ "SignalType" SG_ 2150252544 ECHG_Column03 "UNM";
BA_ "PacketOrder" SG_ 2150252544 ECHG_Column03 5;
BA_ "SignalLongName" SG_ 2150252544 ECHG_Column03 "Energy Consumption History Graph : Column 03";
BA_ "GenSigSendOnInit" SG_ 2150252544 ECHG_Column02 1;
BA_ "GenSigSendType" SG_ 2150252544 ECHG_Column02 12;
BA_ "GenSigDeltaValue" SG_ 2150252544 ECHG_Column02 1;
BA_ "VNSigAllNodes" SG_ 2150252544 ECHG_Column02 1;
BA_ "SignalType" SG_ 2150252544 ECHG_Column02 "UNM";
BA_ "PacketOrder" SG_ 2150252544 ECHG_Column02 4;
BA_ "SignalLongName" SG_ 2150252544 ECHG_Column02 "Energy Consumption History Graph : Column 02";
BA_ "GenSigSendOnInit" SG_ 2150252544 ECHG_Column01 1;
BA_ "GenSigSendType" SG_ 2150252544 ECHG_Column01 12;
BA_ "GenSigDeltaValue" SG_ 2150252544 ECHG_Column01 1;
BA_ "VNSigAllNodes" SG_ 2150252544 ECHG_Column01 1;
BA_ "SignalType" SG_ 2150252544 ECHG_Column01 "UNM";
BA_ "PacketOrder" SG_ 2150252544 ECHG_Column01 3;
BA_ "SignalLongName" SG_ 2150252544 ECHG_Column01 "Energy Consumption History Graph : Column 01";
BA_ "GenSigSendOnInit" SG_ 2150252544 ECHG_EngyCnsmdAvg 1;
BA_ "GenSigSendType" SG_ 2150252544 ECHG_EngyCnsmdAvg 12;
BA_ "GenSigDeltaValue" SG_ 2150252544 ECHG_EngyCnsmdAvg 1;
BA_ "VNSigAllNodes" SG_ 2150252544 ECHG_EngyCnsmdAvg 1;
BA_ "SignalType" SG_ 2150252544 ECHG_EngyCnsmdAvg "UNM";
BA_ "PacketOrder" SG_ 2150252544 ECHG_EngyCnsmdAvg 2;
BA_ "SignalLongName" SG_ 2150252544 ECHG_EngyCnsmdAvg "Energy Consumption History Graph : Energy Consumed Average";
BA_ "GenSigSendOnInit" SG_ 2150252544 ECHG_MeasUnit 1;
BA_ "GenSigSendType" SG_ 2150252544 ECHG_MeasUnit 10;
BA_ "GenSigDeltaValue" SG_ 2150252544 ECHG_MeasUnit 1;
BA_ "VNSigAllNodes" SG_ 2150252544 ECHG_MeasUnit 1;
BA_ "SignalType" SG_ 2150252544 ECHG_MeasUnit "ENM";
BA_ "PacketOrder" SG_ 2150252544 ECHG_MeasUnit 1;
BA_ "SignalLongName" SG_ 2150252544 ECHG_MeasUnit "Energy Consumption History Graph : Measurement Unit";
BA_ "VNSigAllNodes" SG_ 2153308160 RdHVltBatPckVltV 1;
BA_ "SignalType" SG_ 2153308160 RdHVltBatPckVltV "ENM";
BA_ "SignalLongName" SG_ 2153308160 RdHVltBatPckVltV "Redundant High Voltage Battery Pack Voltage Validity";
BA_ "VNSigAllNodes" SG_ 2153308160 RdHVltBatPckVltM 1;
BA_ "SignalType" SG_ 2153308160 RdHVltBatPckVltM "ENM";
BA_ "SignalLongName" SG_ 2153308160 RdHVltBatPckVltM "Redundant High Voltage Battery Pack Voltage Mask";
BA_ "GenSigSendOnInit" SG_ 2153308160 RdHVltBatPckVlt 1;
BA_ "VNSigAllNodes" SG_ 2153308160 RdHVltBatPckVlt 1;
BA_ "SignalType" SG_ 2153308160 RdHVltBatPckVlt "UNM";
BA_ "SignalLongName" SG_ 2153308160 RdHVltBatPckVlt "Redundant High Voltage Battery Pack Voltage";
BA_ "GenSigSendOnInit" SG_ 2153308160 RdHVltBatPckCrntV 1;
BA_ "VNSigAllNodes" SG_ 2153308160 RdHVltBatPckCrntV 1;
BA_ "SignalType" SG_ 2153308160 RdHVltBatPckCrntV "ENM";
BA_ "SignalLongName" SG_ 2153308160 RdHVltBatPckCrntV "Redundant High Voltage Battery Pack Current Validity";
BA_ "GenSigSendOnInit" SG_ 2153308160 RdHVltBatPckCrntM 1;
BA_ "VNSigAllNodes" SG_ 2153308160 RdHVltBatPckCrntM 1;
BA_ "SignalType" SG_ 2153308160 RdHVltBatPckCrntM "ENM";
BA_ "SignalLongName" SG_ 2153308160 RdHVltBatPckCrntM "Redundant High Voltage Battery Pack Current Mask";
BA_ "GenSigSendOnInit" SG_ 2153308160 RdHVltBatPckCrnt 1;
BA_ "VNSigAllNodes" SG_ 2153308160 RdHVltBatPckCrnt 1;
BA_ "SignalType" SG_ 2153308160 RdHVltBatPckCrnt "SNM";
BA_ "SignalLongName" SG_ 2153308160 RdHVltBatPckCrnt "Redundant High Voltage Battery Pack Current";
BA_ "GenSigSendOnInit" SG_ 2153914368 EUSS_TrEgUgScrMxScVal 1;
BA_ "GenSigSendType" SG_ 2153914368 EUSS_TrEgUgScrMxScVal 12;
BA_ "GenSigDeltaValue" SG_ 2153914368 EUSS_TrEgUgScrMxScVal 1;
BA_ "VNSigAllNodes" SG_ 2153914368 EUSS_TrEgUgScrMxScVal 1;
BA_ "SignalType" SG_ 2153914368 EUSS_TrEgUgScrMxScVal "SNM";
BA_ "PacketOrder" SG_ 2153914368 EUSS_TrEgUgScrMxScVal 8;
BA_ "SignalLongName" SG_ 2153914368 EUSS_TrEgUgScrMxScVal "Energy Usage Score Scaling : Terrain Energy Usage Score Maximum Scale Value";
BA_ "GenSigSendOnInit" SG_ 2153914368 EUSS_TrEgUgScrMnScVal 1;
BA_ "GenSigSendType" SG_ 2153914368 EUSS_TrEgUgScrMnScVal 12;
BA_ "GenSigDeltaValue" SG_ 2153914368 EUSS_TrEgUgScrMnScVal 1;
BA_ "VNSigAllNodes" SG_ 2153914368 EUSS_TrEgUgScrMnScVal 1;
BA_ "SignalType" SG_ 2153914368 EUSS_TrEgUgScrMnScVal "SNM";
BA_ "PacketOrder" SG_ 2153914368 EUSS_TrEgUgScrMnScVal 7;
BA_ "SignalLongName" SG_ 2153914368 EUSS_TrEgUgScrMnScVal "Energy Usage Score Scaling : Terrain Energy Usage Score Minimum Scale Value";
BA_ "GenSigSendOnInit" SG_ 2153914368 EUSS_TcEgUgScrMxScVal 1;
BA_ "GenSigSendType" SG_ 2153914368 EUSS_TcEgUgScrMxScVal 12;
BA_ "GenSigDeltaValue" SG_ 2153914368 EUSS_TcEgUgScrMxScVal 1;
BA_ "VNSigAllNodes" SG_ 2153914368 EUSS_TcEgUgScrMxScVal 1;
BA_ "SignalType" SG_ 2153914368 EUSS_TcEgUgScrMxScVal "SNM";
BA_ "PacketOrder" SG_ 2153914368 EUSS_TcEgUgScrMxScVal 6;
BA_ "SignalLongName" SG_ 2153914368 EUSS_TcEgUgScrMxScVal "Energy Usage Score Scaling : Technique Energy Usage Score Maximum Scale Value";
BA_ "GenSigSendOnInit" SG_ 2153914368 EUSS_TcEgUgScrMnScVal 1;
BA_ "GenSigSendType" SG_ 2153914368 EUSS_TcEgUgScrMnScVal 12;
BA_ "GenSigDeltaValue" SG_ 2153914368 EUSS_TcEgUgScrMnScVal 1;
BA_ "VNSigAllNodes" SG_ 2153914368 EUSS_TcEgUgScrMnScVal 1;
BA_ "SignalType" SG_ 2153914368 EUSS_TcEgUgScrMnScVal "SNM";
BA_ "PacketOrder" SG_ 2153914368 EUSS_TcEgUgScrMnScVal 5;
BA_ "SignalLongName" SG_ 2153914368 EUSS_TcEgUgScrMnScVal "Energy Usage Score Scaling : Technique Energy Usage Score Minimum Scale Value";
BA_ "GenSigSendOnInit" SG_ 2153914368 EUSS_ITEgUgScrMxScVal 1;
BA_ "GenSigSendType" SG_ 2153914368 EUSS_ITEgUgScrMxScVal 12;
BA_ "GenSigDeltaValue" SG_ 2153914368 EUSS_ITEgUgScrMxScVal 1;
BA_ "VNSigAllNodes" SG_ 2153914368 EUSS_ITEgUgScrMxScVal 1;
BA_ "SignalType" SG_ 2153914368 EUSS_ITEgUgScrMxScVal "SNM";
BA_ "PacketOrder" SG_ 2153914368 EUSS_ITEgUgScrMxScVal 4;
BA_ "SignalLongName" SG_ 2153914368 EUSS_ITEgUgScrMxScVal "Energy Usage Score Scaling : Inside Temp Energy Usage Score Max Scale Value";
BA_ "GenSigSendOnInit" SG_ 2153914368 EUSS_ITEgUgScrMnScVal 1;
BA_ "GenSigSendType" SG_ 2153914368 EUSS_ITEgUgScrMnScVal 12;
BA_ "GenSigDeltaValue" SG_ 2153914368 EUSS_ITEgUgScrMnScVal 1;
BA_ "VNSigAllNodes" SG_ 2153914368 EUSS_ITEgUgScrMnScVal 1;
BA_ "SignalType" SG_ 2153914368 EUSS_ITEgUgScrMnScVal "SNM";
BA_ "PacketOrder" SG_ 2153914368 EUSS_ITEgUgScrMnScVal 3;
BA_ "SignalLongName" SG_ 2153914368 EUSS_ITEgUgScrMnScVal "Energy Usage Score Scaling : Inside Temp Energy Usage Score Min Scale Value";
BA_ "GenSigSendOnInit" SG_ 2153914368 EUSS_OTEgUgScrMxScVal 1;
BA_ "GenSigSendType" SG_ 2153914368 EUSS_OTEgUgScrMxScVal 12;
BA_ "GenSigDeltaValue" SG_ 2153914368 EUSS_OTEgUgScrMxScVal 1;
BA_ "VNSigAllNodes" SG_ 2153914368 EUSS_OTEgUgScrMxScVal 1;
BA_ "SignalType" SG_ 2153914368 EUSS_OTEgUgScrMxScVal "SNM";
BA_ "PacketOrder" SG_ 2153914368 EUSS_OTEgUgScrMxScVal 2;
BA_ "SignalLongName" SG_ 2153914368 EUSS_OTEgUgScrMxScVal "Energy Usage Score Scaling : Outside Temp Energy Usage Score Max Scale Value";
BA_ "GenSigSendOnInit" SG_ 2153914368 EUSS_OTEgUgScrMnScVal 1;
BA_ "GenSigSendType" SG_ 2153914368 EUSS_OTEgUgScrMnScVal 12;
BA_ "GenSigDeltaValue" SG_ 2153914368 EUSS_OTEgUgScrMnScVal 1;
BA_ "VNSigAllNodes" SG_ 2153914368 EUSS_OTEgUgScrMnScVal 1;
BA_ "SignalType" SG_ 2153914368 EUSS_OTEgUgScrMnScVal "SNM";
BA_ "PacketOrder" SG_ 2153914368 EUSS_OTEgUgScrMnScVal 1;
BA_ "SignalLongName" SG_ 2153914368 EUSS_OTEgUgScrMnScVal "Energy Usage Score Scaling : Outside Temp Energy Usage Score Min Scale Value";
BA_ "GenSigSendOnInit" SG_ 2150580224 CstNonUsbSOCDspLvl 1;
BA_ "GenSigSendType" SG_ 2150580224 CstNonUsbSOCDspLvl 12;
BA_ "GenSigDeltaValue" SG_ 2150580224 CstNonUsbSOCDspLvl 1;
BA_ "VNSigAllNodes" SG_ 2150580224 CstNonUsbSOCDspLvl 1;
BA_ "SignalType" SG_ 2150580224 CstNonUsbSOCDspLvl "UNM";
BA_ "SignalLongName" SG_ 2150580224 CstNonUsbSOCDspLvl "Customer Non Usable State of Charge Display Level";
BA_ "GenSigSendOnInit" SG_ 2150580224 CstmrNonUsblSOCV 1;
BA_ "GenSigSendType" SG_ 2150580224 CstmrNonUsblSOCV 10;
BA_ "VNSigAllNodes" SG_ 2150580224 CstmrNonUsblSOCV 1;
BA_ "SignalType" SG_ 2150580224 CstmrNonUsblSOCV "ENM";
BA_ "SignalLongName" SG_ 2150580224 CstmrNonUsblSOCV "Customer Non Usable State of Charge Validity";
BA_ "GenSigSendOnInit" SG_ 2150580224 CstmrNonUsblSOC 1;
BA_ "GenSigSendType" SG_ 2150580224 CstmrNonUsblSOC 12;
BA_ "GenSigDeltaValue" SG_ 2150580224 CstmrNonUsblSOC 1;
BA_ "VNSigAllNodes" SG_ 2150580224 CstmrNonUsblSOC 1;
BA_ "SignalType" SG_ 2150580224 CstmrNonUsblSOC "UNM";
BA_ "SignalLongName" SG_ 2150580224 CstmrNonUsblSOC "Customer Non Usable State of Charge";
BA_ "GenSigSendOnInit" SG_ 2150580224 PrpDspTtlPwrLvlPct 1;
BA_ "GenSigSendType" SG_ 2150580224 PrpDspTtlPwrLvlPct 12;
BA_ "GenSigDeltaValue" SG_ 2150580224 PrpDspTtlPwrLvlPct 1;
BA_ "VNSigAllNodes" SG_ 2150580224 PrpDspTtlPwrLvlPct 1;
BA_ "SignalType" SG_ 2150580224 PrpDspTtlPwrLvlPct "SNM";
BA_ "SignalLongName" SG_ 2150580224 PrpDspTtlPwrLvlPct "Propulsion Display Total Power Level Percent";
BA_ "GenSigSendOnInit" SG_ 2150080512 LBCVLS_VehGPSLctV 1;
BA_ "GenSigSendType" SG_ 2150080512 LBCVLS_VehGPSLctV 10;
BA_ "VNSigAllNodes" SG_ 2150080512 LBCVLS_VehGPSLctV 1;
BA_ "SignalType" SG_ 2150080512 LBCVLS_VehGPSLctV "ENM";
BA_ "PacketOrder" SG_ 2150080512 LBCVLS_VehGPSLctV 1;
BA_ "SignalLongName" SG_ 2150080512 LBCVLS_VehGPSLctV "Location Based Charging Vehicle Location Status : Vehicle GPS Location Validity";
BA_ "GenSigSendOnInit" SG_ 2150080512 LBCVLS_VehGPSLct 1;
BA_ "GenSigSendType" SG_ 2150080512 LBCVLS_VehGPSLct 10;
BA_ "VNSigAllNodes" SG_ 2150080512 LBCVLS_VehGPSLct 1;
BA_ "SignalType" SG_ 2150080512 LBCVLS_VehGPSLct "ENM";
BA_ "PacketOrder" SG_ 2150080512 LBCVLS_VehGPSLct 2;
BA_ "SignalLongName" SG_ 2150080512 LBCVLS_VehGPSLct "Location Based Charging Vehicle Location Status : Vehicle GPS Location";
BA_ "GenSigSendOnInit" SG_ 2150080512 LBCPSS_PosUpdtStat 1;
BA_ "GenSigSendType" SG_ 2150080512 LBCPSS_PosUpdtStat 10;
BA_ "VNSigAllNodes" SG_ 2150080512 LBCPSS_PosUpdtStat 1;
BA_ "SignalType" SG_ 2150080512 LBCPSS_PosUpdtStat "ENM";
BA_ "PacketOrder" SG_ 2150080512 LBCPSS_PosUpdtStat 1;
BA_ "SignalLongName" SG_ 2150080512 LBCPSS_PosUpdtStat "Location Based Charging Position Storage Status : Position Update Status";
BA_ "GenSigSendOnInit" SG_ 2150080512 LBCPSS_PosUpdtLct 1;
BA_ "GenSigSendType" SG_ 2150080512 LBCPSS_PosUpdtLct 10;
BA_ "VNSigAllNodes" SG_ 2150080512 LBCPSS_PosUpdtLct 1;
BA_ "SignalType" SG_ 2150080512 LBCPSS_PosUpdtLct "ENM";
BA_ "PacketOrder" SG_ 2150080512 LBCPSS_PosUpdtLct 2;
BA_ "SignalLongName" SG_ 2150080512 LBCPSS_PosUpdtLct "Location Based Charging Position Storage Status : Position Update Location";
BA_ "GenSigSendOnInit" SG_ 2150080512 LBCCsStAvl 1;
BA_ "GenSigSendType" SG_ 2150080512 LBCCsStAvl 10;
BA_ "VNSigAllNodes" SG_ 2150080512 LBCCsStAvl 1;
BA_ "SignalType" SG_ 2150080512 LBCCsStAvl "BLN";
BA_ "SignalLongName" SG_ 2150080512 LBCCsStAvl "Location Based Charging Customization Setting Available";
BA_ "GenSigSendOnInit" SG_ 2150080512 LBCCsCrStVal 1;
BA_ "GenSigSendType" SG_ 2150080512 LBCCsCrStVal 10;
BA_ "VNSigAllNodes" SG_ 2150080512 LBCCsCrStVal 1;
BA_ "SignalType" SG_ 2150080512 LBCCsCrStVal "ENM";
BA_ "SignalLongName" SG_ 2150080512 LBCCsCrStVal "Location Based Charging Customization Current Setting Value";
BA_ "GenSigSendOnInit" SG_ 2150080512 LBCCF_Lct4PosStrdIO 1;
BA_ "GenSigSendType" SG_ 2150080512 LBCCF_Lct4PosStrdIO 10;
BA_ "VNSigAllNodes" SG_ 2150080512 LBCCF_Lct4PosStrdIO 1;
BA_ "SignalType" SG_ 2150080512 LBCCF_Lct4PosStrdIO "BLN";
BA_ "PacketOrder" SG_ 2150080512 LBCCF_Lct4PosStrdIO 4;
BA_ "SignalLongName" SG_ 2150080512 LBCCF_Lct4PosStrdIO "Location Based Charging Customer Feedback : Location 4 Position Stored Indication On";
BA_ "GenSigSendOnInit" SG_ 2150080512 LBCCF_Lct3PosStrdIO 1;
BA_ "GenSigSendType" SG_ 2150080512 LBCCF_Lct3PosStrdIO 10;
BA_ "VNSigAllNodes" SG_ 2150080512 LBCCF_Lct3PosStrdIO 1;
BA_ "SignalType" SG_ 2150080512 LBCCF_Lct3PosStrdIO "BLN";
BA_ "PacketOrder" SG_ 2150080512 LBCCF_Lct3PosStrdIO 3;
BA_ "SignalLongName" SG_ 2150080512 LBCCF_Lct3PosStrdIO "Location Based Charging Customer Feedback : Location 3 Position Stored Indication On";
BA_ "GenSigSendOnInit" SG_ 2150080512 LBCCF_Lct2PosStrdIO 1;
BA_ "GenSigSendType" SG_ 2150080512 LBCCF_Lct2PosStrdIO 10;
BA_ "VNSigAllNodes" SG_ 2150080512 LBCCF_Lct2PosStrdIO 1;
BA_ "SignalType" SG_ 2150080512 LBCCF_Lct2PosStrdIO "BLN";
BA_ "PacketOrder" SG_ 2150080512 LBCCF_Lct2PosStrdIO 2;
BA_ "SignalLongName" SG_ 2150080512 LBCCF_Lct2PosStrdIO "Location Based Charging Customer Feedback : Location 2 Position Stored Indication On";
BA_ "GenSigSendOnInit" SG_ 2150080512 LBCCF_Lct1PosStrdIO 1;
BA_ "GenSigSendType" SG_ 2150080512 LBCCF_Lct1PosStrdIO 10;
BA_ "VNSigAllNodes" SG_ 2150080512 LBCCF_Lct1PosStrdIO 1;
BA_ "SignalType" SG_ 2150080512 LBCCF_Lct1PosStrdIO "BLN";
BA_ "PacketOrder" SG_ 2150080512 LBCCF_Lct1PosStrdIO 1;
BA_ "SignalLongName" SG_ 2150080512 LBCCF_Lct1PosStrdIO "Location Based Charging Customer Feedback : Location 1 Position Stored Indication On";
BA_ "GenSigSendType" SG_ 2150080512 LBCCDRR_PosNumbr 10;
BA_ "VNSigAllNodes" SG_ 2150080512 LBCCDRR_PosNumbr 1;
BA_ "SignalType" SG_ 2150080512 LBCCDRR_PosNumbr "ENM";
BA_ "PacketOrder" SG_ 2150080512 LBCCDRR_PosNumbr 2;
BA_ "SignalLongName" SG_ 2150080512 LBCCDRR_PosNumbr "Location Based Charging Customer Data Reset Response : Position Number";
BA_ "GenSigSendType" SG_ 2150080512 LBCCDRR_ClrStrdPosResp 10;
BA_ "VNSigAllNodes" SG_ 2150080512 LBCCDRR_ClrStrdPosResp 1;
BA_ "SignalType" SG_ 2150080512 LBCCDRR_ClrStrdPosResp "ENM";
BA_ "PacketOrder" SG_ 2150080512 LBCCDRR_ClrStrdPosResp 1;
BA_ "SignalLongName" SG_ 2150080512 LBCCDRR_ClrStrdPosResp "Location Based Charging Customer Data Reset Response : Clear Stored Position response";
BA_ "GenSigSendOnInit" SG_ 2150080512 ChrgCyclOvrlEngyEcnEq 1;
BA_ "GenSigSendType" SG_ 2150080512 ChrgCyclOvrlEngyEcnEq 12;
BA_ "GenSigDeltaValue" SG_ 2150080512 ChrgCyclOvrlEngyEcnEq 1;
BA_ "VNSigAllNodes" SG_ 2150080512 ChrgCyclOvrlEngyEcnEq 1;
BA_ "SignalType" SG_ 2150080512 ChrgCyclOvrlEngyEcnEq "UNM";
BA_ "SignalLongName" SG_ 2150080512 ChrgCyclOvrlEngyEcnEq "Charge Cycle Overall Energy Economy Equivalent";
BA_ "GenSigSendOnInit" SG_ 2150080512 ChrgCyclElecEngyEcnEq 1;
BA_ "GenSigSendType" SG_ 2150080512 ChrgCyclElecEngyEcnEq 12;
BA_ "GenSigDeltaValue" SG_ 2150080512 ChrgCyclElecEngyEcnEq 1;
BA_ "VNSigAllNodes" SG_ 2150080512 ChrgCyclElecEngyEcnEq 1;
BA_ "SignalType" SG_ 2150080512 ChrgCyclElecEngyEcnEq "UNM";
BA_ "SignalLongName" SG_ 2150080512 ChrgCyclElecEngyEcnEq "Charge Cycle Electrical Energy Economy Equivalent";
BA_ "GenSigSendOnInit" SG_ 2150080512 LBCChrgLvlPrfExpIO 1;
BA_ "GenSigSendType" SG_ 2150080512 LBCChrgLvlPrfExpIO 10;
BA_ "VNSigAllNodes" SG_ 2150080512 LBCChrgLvlPrfExpIO 1;
BA_ "SignalType" SG_ 2150080512 LBCChrgLvlPrfExpIO "BLN";
BA_ "SignalLongName" SG_ 2150080512 LBCChrgLvlPrfExpIO "Location Based Charging Charge Level Preference Expiration Indication On";
BA_ "GenSigSendType" SG_ 2150080512 EngAstHtDfrdHtMdAct 10;
BA_ "VNSigAllNodes" SG_ 2150080512 EngAstHtDfrdHtMdAct 1;
BA_ "SignalType" SG_ 2150080512 EngAstHtDfrdHtMdAct "BLN";
BA_ "SignalLongName" SG_ 2150080512 EngAstHtDfrdHtMdAct "Engine Assisted Heating Deferred Heat Mode Active";
BA_ "GenSigSendOnInit" SG_ 2150080512 AuxClntHtrVlvStat 1;
BA_ "GenSigSendType" SG_ 2150080512 AuxClntHtrVlvStat 10;
BA_ "VNSigAllNodes" SG_ 2150080512 AuxClntHtrVlvStat 1;
BA_ "SignalType" SG_ 2150080512 AuxClntHtrVlvStat "ENM";
BA_ "SignalLongName" SG_ 2150080512 AuxClntHtrVlvStat "Auxiliary Coolant Heater Valve Status";
BA_ "GenSigSendType" SG_ 2150383616 LssOfPrplsnIO 10;
BA_ "VNSigAllNodes" SG_ 2150383616 LssOfPrplsnIO 1;
BA_ "SignalType" SG_ 2150383616 LssOfPrplsnIO "BLN";
BA_ "SignalLongName" SG_ 2150383616 LssOfPrplsnIO "Loss of Propulsion Indication On";
BA_ "GenSigSendType" SG_ 2150383616 EngMntncePrcntCpl 12;
BA_ "GenSigDeltaValue" SG_ 2150383616 EngMntncePrcntCpl 1;
BA_ "VNSigAllNodes" SG_ 2150383616 EngMntncePrcntCpl 1;
BA_ "SignalType" SG_ 2150383616 EngMntncePrcntCpl "UNM";
BA_ "SignalLongName" SG_ 2150383616 EngMntncePrcntCpl "Engine Maintenance Percent Complete";
BA_ "GenSigSendType" SG_ 2150383616 EngMntnceMdAct 10;
BA_ "VNSigAllNodes" SG_ 2150383616 EngMntnceMdAct 1;
BA_ "SignalType" SG_ 2150383616 EngMntnceMdAct "BLN";
BA_ "SignalLongName" SG_ 2150383616 EngMntnceMdAct "Engine Maintenance Mode Active";
BA_ "GenSigSendType" SG_ 2150383616 BatPrpDspPwrLvlPct 12;
BA_ "GenSigDeltaValue" SG_ 2150383616 BatPrpDspPwrLvlPct 1;
BA_ "VNSigAllNodes" SG_ 2150383616 BatPrpDspPwrLvlPct 1;
BA_ "SignalType" SG_ 2150383616 BatPrpDspPwrLvlPct "SNM";
BA_ "SignalLongName" SG_ 2150383616 BatPrpDspPwrLvlPct "Battery Propulsion Display Power Level Percent";
BA_ "GenSigSendType" SG_ 2150383616 PrpDspTtlPwr 12;
BA_ "GenSigDeltaValue" SG_ 2150383616 PrpDspTtlPwr 1;
BA_ "VNSigAllNodes" SG_ 2150383616 PrpDspTtlPwr 1;
BA_ "SignalType" SG_ 2150383616 PrpDspTtlPwr "UNM";
BA_ "SignalLongName" SG_ 2150383616 PrpDspTtlPwr "Propulsion Display Total Power";
BA_ "GenSigSendType" SG_ 2150383616 PrpCapDspOpPs 12;
BA_ "GenSigDeltaValue" SG_ 2150383616 PrpCapDspOpPs 1;
BA_ "VNSigAllNodes" SG_ 2150383616 PrpCapDspOpPs 1;
BA_ "SignalType" SG_ 2150383616 PrpCapDspOpPs "UNM";
BA_ "SignalLongName" SG_ 2150383616 PrpCapDspOpPs "Propulsion Capability Display Operating Position";
BA_ "GenSigSendType" SG_ 2150383616 EstElecPrpCap 12;
BA_ "GenSigDeltaValue" SG_ 2150383616 EstElecPrpCap 1;
BA_ "VNSigAllNodes" SG_ 2150383616 EstElecPrpCap 1;
BA_ "SignalType" SG_ 2150383616 EstElecPrpCap "UNM";
BA_ "SignalLongName" SG_ 2150383616 EstElecPrpCap "Estimated Electrical Propulsion Capability";
BA_ "GenSigSendType" SG_ 2150383616 EngPrpDspPwrLvlPct 12;
BA_ "GenSigDeltaValue" SG_ 2150383616 EngPrpDspPwrLvlPct 1;
BA_ "VNSigAllNodes" SG_ 2150383616 EngPrpDspPwrLvlPct 1;
BA_ "SignalType" SG_ 2150383616 EngPrpDspPwrLvlPct "UNM";
BA_ "SignalLongName" SG_ 2150383616 EngPrpDspPwrLvlPct "Engine Propulsion Display Power Level Percent";
BA_ "GenSigSendOnInit" SG_ 2150383616 MntnceMdDsplyRq 1;
BA_ "GenSigSendType" SG_ 2150383616 MntnceMdDsplyRq 10;
BA_ "VNSigAllNodes" SG_ 2150383616 MntnceMdDsplyRq 1;
BA_ "SignalType" SG_ 2150383616 MntnceMdDsplyRq "ENM";
BA_ "SignalLongName" SG_ 2150383616 MntnceMdDsplyRq "Maintenance Mode Display Request";
BA_ "GenSigSendOnInit" SG_ 2151981056 DrvCyclBatPropRat 1;
BA_ "GenSigSendType" SG_ 2151981056 DrvCyclBatPropRat 12;
BA_ "GenSigDeltaValue" SG_ 2151981056 DrvCyclBatPropRat 1;
BA_ "VNSigAllNodes" SG_ 2151981056 DrvCyclBatPropRat 1;
BA_ "SignalType" SG_ 2151981056 DrvCyclBatPropRat "UNM";
BA_ "SignalLongName" SG_ 2151981056 DrvCyclBatPropRat "Drive Cycle Battery Propulsion Ratio";
BA_ "GenSigSendOnInit" SG_ 2151981056 DTD_FuelPrpDstTrvld 1;
BA_ "GenSigSendType" SG_ 2151981056 DTD_FuelPrpDstTrvld 12;
BA_ "GenSigDeltaValue" SG_ 2151981056 DTD_FuelPrpDstTrvld 1;
BA_ "VNSigAllNodes" SG_ 2151981056 DTD_FuelPrpDstTrvld 1;
BA_ "SignalType" SG_ 2151981056 DTD_FuelPrpDstTrvld "UNM";
BA_ "PacketOrder" SG_ 2151981056 DTD_FuelPrpDstTrvld 2;
BA_ "SignalLongName" SG_ 2151981056 DTD_FuelPrpDstTrvld "Distance Traveled Data : Fuel Propulsion Distance Traveled";
BA_ "GenSigSendOnInit" SG_ 2151981056 DTD_DrvCyclDstTrvld 1;
BA_ "GenSigSendType" SG_ 2151981056 DTD_DrvCyclDstTrvld 12;
BA_ "GenSigDeltaValue" SG_ 2151981056 DTD_DrvCyclDstTrvld 1;
BA_ "VNSigAllNodes" SG_ 2151981056 DTD_DrvCyclDstTrvld 1;
BA_ "SignalType" SG_ 2151981056 DTD_DrvCyclDstTrvld "UNM";
BA_ "PacketOrder" SG_ 2151981056 DTD_DrvCyclDstTrvld 3;
BA_ "SignalLongName" SG_ 2151981056 DTD_DrvCyclDstTrvld "Distance Traveled Data : Drive Cycle Distance Traveled";
BA_ "GenSigSendOnInit" SG_ 2151981056 DTD_BattPrpDstTrvld 1;
BA_ "GenSigSendType" SG_ 2151981056 DTD_BattPrpDstTrvld 12;
BA_ "GenSigDeltaValue" SG_ 2151981056 DTD_BattPrpDstTrvld 1;
BA_ "VNSigAllNodes" SG_ 2151981056 DTD_BattPrpDstTrvld 1;
BA_ "SignalType" SG_ 2151981056 DTD_BattPrpDstTrvld "UNM";
BA_ "PacketOrder" SG_ 2151981056 DTD_BattPrpDstTrvld 1;
BA_ "SignalLongName" SG_ 2151981056 DTD_BattPrpDstTrvld "Distance Traveled Data : Battery Propulsion Distance Traveled";
BA_ "GenSigSendOnInit" SG_ 2151964672 DrvCyclTtlEnrgEfncy 1;
BA_ "GenSigSendType" SG_ 2151964672 DrvCyclTtlEnrgEfncy 12;
BA_ "GenSigDeltaValue" SG_ 2151964672 DrvCyclTtlEnrgEfncy 1;
BA_ "VNSigAllNodes" SG_ 2151964672 DrvCyclTtlEnrgEfncy 1;
BA_ "SignalType" SG_ 2151964672 DrvCyclTtlEnrgEfncy "UNM";
BA_ "SignalLongName" SG_ 2151964672 DrvCyclTtlEnrgEfncy "Drive Cycle Total Energy Efficiency";
BA_ "GenSigSendOnInit" SG_ 2151964672 DrvCyclFuelUsd 1;
BA_ "GenSigSendType" SG_ 2151964672 DrvCyclFuelUsd 12;
BA_ "GenSigDeltaValue" SG_ 2151964672 DrvCyclFuelUsd 1;
BA_ "VNSigAllNodes" SG_ 2151964672 DrvCyclFuelUsd 1;
BA_ "SignalType" SG_ 2151964672 DrvCyclFuelUsd "UNM";
BA_ "SignalLongName" SG_ 2151964672 DrvCyclFuelUsd "Drive Cycle Fuel Used";
BA_ "GenSigSendOnInit" SG_ 2151964672 DrvCyclFuelEnmy 1;
BA_ "GenSigSendType" SG_ 2151964672 DrvCyclFuelEnmy 12;
BA_ "GenSigDeltaValue" SG_ 2151964672 DrvCyclFuelEnmy 1;
BA_ "VNSigAllNodes" SG_ 2151964672 DrvCyclFuelEnmy 1;
BA_ "SignalType" SG_ 2151964672 DrvCyclFuelEnmy "UNM";
BA_ "SignalLongName" SG_ 2151964672 DrvCyclFuelEnmy "Drive Cycle Fuel Economy";
BA_ "GenSigSendOnInit" SG_ 2151964672 DrvCyclDrvStEnrgEfncy 1;
BA_ "GenSigSendType" SG_ 2151964672 DrvCyclDrvStEnrgEfncy 12;
BA_ "GenSigDeltaValue" SG_ 2151964672 DrvCyclDrvStEnrgEfncy 1;
BA_ "VNSigAllNodes" SG_ 2151964672 DrvCyclDrvStEnrgEfncy 1;
BA_ "SignalType" SG_ 2151964672 DrvCyclDrvStEnrgEfncy "UNM";
BA_ "SignalLongName" SG_ 2151964672 DrvCyclDrvStEnrgEfncy "Drive Cycle Driving Style Energy Efficiency";
BA_ "GenSigSendOnInit" SG_ 2151964672 DrvCyclCbnCondEnrgEfncy 1;
BA_ "GenSigSendType" SG_ 2151964672 DrvCyclCbnCondEnrgEfncy 12;
BA_ "GenSigDeltaValue" SG_ 2151964672 DrvCyclCbnCondEnrgEfncy 1;
BA_ "VNSigAllNodes" SG_ 2151964672 DrvCyclCbnCondEnrgEfncy 1;
BA_ "SignalType" SG_ 2151964672 DrvCyclCbnCondEnrgEfncy "UNM";
BA_ "SignalLongName" SG_ 2151964672 DrvCyclCbnCondEnrgEfncy "Drive Cycle Cabin Conditioning Energy Efficiency";
BA_ "GenSigSendOnInit" SG_ 2151964672 DrvCyclBatCondEnrgEfncy 1;
BA_ "GenSigSendType" SG_ 2151964672 DrvCyclBatCondEnrgEfncy 12;
BA_ "GenSigDeltaValue" SG_ 2151964672 DrvCyclBatCondEnrgEfncy 1;
BA_ "VNSigAllNodes" SG_ 2151964672 DrvCyclBatCondEnrgEfncy 1;
BA_ "SignalType" SG_ 2151964672 DrvCyclBatCondEnrgEfncy "UNM";
BA_ "SignalLongName" SG_ 2151964672 DrvCyclBatCondEnrgEfncy "Drive Cycle Battery Conditioning Energy Efficiency";
BA_ "GenSigSendType" SG_ 2150055936 ClmCntCmpPwrUsdClc 12;
BA_ "GenSigDeltaValue" SG_ 2150055936 ClmCntCmpPwrUsdClc 1;
BA_ "VNSigAllNodes" SG_ 2150055936 ClmCntCmpPwrUsdClc 1;
BA_ "SignalType" SG_ 2150055936 ClmCntCmpPwrUsdClc "UNM";
BA_ "SignalLongName" SG_ 2150055936 ClmCntCmpPwrUsdClc "Climate Control Compressor Power Used Calculated";
BA_ "GenSigSendOnInit" SG_ 2150055936 ClimCtrlHVDvcShtdwnCmd 1;
BA_ "GenSigSendType" SG_ 2150055936 ClimCtrlHVDvcShtdwnCmd 10;
BA_ "GenSigDeltaValue" SG_ 2150055936 ClimCtrlHVDvcShtdwnCmd 1;
BA_ "VNSigAllNodes" SG_ 2150055936 ClimCtrlHVDvcShtdwnCmd 1;
BA_ "SignalType" SG_ 2150055936 ClimCtrlHVDvcShtdwnCmd "BLN";
BA_ "SignalLongName" SG_ 2150055936 ClimCtrlHVDvcShtdwnCmd "Climate Control High Voltage Device Shutdown Commanded";
BA_ "GenSigSendOnInit" SG_ 2150055936 ClmtCtrlLwrPwrLmt 1;
BA_ "GenSigSendType" SG_ 2150055936 ClmtCtrlLwrPwrLmt 12;
BA_ "GenSigDeltaValue" SG_ 2150055936 ClmtCtrlLwrPwrLmt 1;
BA_ "VNSigAllNodes" SG_ 2150055936 ClmtCtrlLwrPwrLmt 1;
BA_ "SignalType" SG_ 2150055936 ClmtCtrlLwrPwrLmt "UNM";
BA_ "SignalLongName" SG_ 2150055936 ClmtCtrlLwrPwrLmt "Climate Control Lower Power Limit";
BA_ "GenSigSendOnInit" SG_ 2150055936 ClmtCtrlUpprPwrLmt 1;
BA_ "GenSigSendType" SG_ 2150055936 ClmtCtrlUpprPwrLmt 12;
BA_ "GenSigDeltaValue" SG_ 2150055936 ClmtCtrlUpprPwrLmt 1;
BA_ "VNSigAllNodes" SG_ 2150055936 ClmtCtrlUpprPwrLmt 1;
BA_ "SignalType" SG_ 2150055936 ClmtCtrlUpprPwrLmt "UNM";
BA_ "SignalLongName" SG_ 2150055936 ClmtCtrlUpprPwrLmt "Climate Control Upper Power Limit";
BA_ "GenSigSendType" SG_ 2150039552 EvpCorOtltAirTmpCalcdV 10;
BA_ "VNSigAllNodes" SG_ 2150039552 EvpCorOtltAirTmpCalcdV 1;
BA_ "SignalType" SG_ 2150039552 EvpCorOtltAirTmpCalcdV "ENM";
BA_ "SignalLongName" SG_ 2150039552 EvpCorOtltAirTmpCalcdV "Evaporator Core Outlet Air Temperature Calculated Validity";
BA_ "GenSigSendOnInit" SG_ 2150039552 ThrmlRefCompStat 1;
BA_ "GenSigSendType" SG_ 2150039552 ThrmlRefCompStat 10;
BA_ "VNSigAllNodes" SG_ 2150039552 ThrmlRefCompStat 1;
BA_ "SignalType" SG_ 2150039552 ThrmlRefCompStat "ENM";
BA_ "SignalLongName" SG_ 2150039552 ThrmlRefCompStat "Thermal Refrigerant Compressor Status";
BA_ "GenSigSendOnInit" SG_ 2150039552 ThrmlRefCompSpdV 1;
BA_ "GenSigSendType" SG_ 2150039552 ThrmlRefCompSpdV 10;
BA_ "VNSigAllNodes" SG_ 2150039552 ThrmlRefCompSpdV 1;
BA_ "SignalType" SG_ 2150039552 ThrmlRefCompSpdV "ENM";
BA_ "SignalLongName" SG_ 2150039552 ThrmlRefCompSpdV "Thermal Refrigerant Compressor Speed Validity";
BA_ "GenSigSendOnInit" SG_ 2150039552 ThrmlRefCompSpd 1;
BA_ "GenSigSendType" SG_ 2150039552 ThrmlRefCompSpd 12;
BA_ "GenSigDeltaValue" SG_ 2150039552 ThrmlRefCompSpd 1;
BA_ "VNSigAllNodes" SG_ 2150039552 ThrmlRefCompSpd 1;
BA_ "SignalType" SG_ 2150039552 ThrmlRefCompSpd "UNM";
BA_ "SignalLongName" SG_ 2150039552 ThrmlRefCompSpd "Thermal Refrigerant Compressor Speed";
BA_ "GenSigSendOnInit" SG_ 2150039552 ThrmlRfCmpOvTmpFltPr 1;
BA_ "GenSigSendType" SG_ 2150039552 ThrmlRfCmpOvTmpFltPr 10;
BA_ "VNSigAllNodes" SG_ 2150039552 ThrmlRfCmpOvTmpFltPr 1;
BA_ "SignalType" SG_ 2150039552 ThrmlRfCmpOvTmpFltPr "BLN";
BA_ "SignalLongName" SG_ 2150039552 ThrmlRfCmpOvTmpFltPr "Thermal Refrigerant Compressor Over Temperature Fault Present";
BA_ "GenSigSendType" SG_ 2150039552 EvpCorOtltAirTmpCalcd 12;
BA_ "GenSigDeltaValue" SG_ 2150039552 EvpCorOtltAirTmpCalcd 1;
BA_ "VNSigAllNodes" SG_ 2150039552 EvpCorOtltAirTmpCalcd 1;
BA_ "SignalType" SG_ 2150039552 EvpCorOtltAirTmpCalcd "UNM";
BA_ "SignalLongName" SG_ 2150039552 EvpCorOtltAirTmpCalcd "Evaporator Core Outlet Air Temperature Calculated";
BA_ "GenSigSendType" SG_ 2151809024 ElecEngyEconAvg 12;
BA_ "GenSigDeltaValue" SG_ 2151809024 ElecEngyEconAvg 1;
BA_ "VNSigAllNodes" SG_ 2151809024 ElecEngyEconAvg 1;
BA_ "SignalType" SG_ 2151809024 ElecEngyEconAvg "UNM";
BA_ "SignalLongName" SG_ 2151809024 ElecEngyEconAvg "Electrical Energy Economy Average";
BA_ "GenSigSendOnInit" SG_ 2151809024 DrvCycElecEngySt5 1;
BA_ "GenSigSendType" SG_ 2151809024 DrvCycElecEngySt5 12;
BA_ "GenSigDeltaValue" SG_ 2151809024 DrvCycElecEngySt5 1;
BA_ "VNSigAllNodes" SG_ 2151809024 DrvCycElecEngySt5 1;
BA_ "SignalType" SG_ 2151809024 DrvCycElecEngySt5 "UNM";
BA_ "SignalLongName" SG_ 2151809024 DrvCycElecEngySt5 "Drive Cycle Electrical Energy State 5";
BA_ "GenSigSendOnInit" SG_ 2151809024 DCEEC_EngyPct4 1;
BA_ "GenSigSendType" SG_ 2151809024 DCEEC_EngyPct4 12;
BA_ "GenSigDeltaValue" SG_ 2151809024 DCEEC_EngyPct4 1;
BA_ "VNSigAllNodes" SG_ 2151809024 DCEEC_EngyPct4 1;
BA_ "SignalType" SG_ 2151809024 DCEEC_EngyPct4 "UNM";
BA_ "PacketOrder" SG_ 2151809024 DCEEC_EngyPct4 4;
BA_ "SignalLongName" SG_ 2151809024 DCEEC_EngyPct4 "Drive Cycle Electrical Energy Consumed : Energy Percent 4";
BA_ "GenSigSendOnInit" SG_ 2151809024 DCEEC_EngyPct3 1;
BA_ "GenSigSendType" SG_ 2151809024 DCEEC_EngyPct3 12;
BA_ "GenSigDeltaValue" SG_ 2151809024 DCEEC_EngyPct3 1;
BA_ "VNSigAllNodes" SG_ 2151809024 DCEEC_EngyPct3 1;
BA_ "SignalType" SG_ 2151809024 DCEEC_EngyPct3 "UNM";
BA_ "PacketOrder" SG_ 2151809024 DCEEC_EngyPct3 3;
BA_ "SignalLongName" SG_ 2151809024 DCEEC_EngyPct3 "Drive Cycle Electrical Energy Consumed : Energy Percent 3";
BA_ "GenSigSendOnInit" SG_ 2151809024 DCEEC_EngyPct2 1;
BA_ "GenSigSendType" SG_ 2151809024 DCEEC_EngyPct2 12;
BA_ "GenSigDeltaValue" SG_ 2151809024 DCEEC_EngyPct2 1;
BA_ "VNSigAllNodes" SG_ 2151809024 DCEEC_EngyPct2 1;
BA_ "SignalType" SG_ 2151809024 DCEEC_EngyPct2 "UNM";
BA_ "PacketOrder" SG_ 2151809024 DCEEC_EngyPct2 2;
BA_ "SignalLongName" SG_ 2151809024 DCEEC_EngyPct2 "Drive Cycle Electrical Energy Consumed : Energy Percent 2";
BA_ "GenSigSendOnInit" SG_ 2151809024 DCEEC_EngyPct1 1;
BA_ "GenSigSendType" SG_ 2151809024 DCEEC_EngyPct1 12;
BA_ "GenSigDeltaValue" SG_ 2151809024 DCEEC_EngyPct1 1;
BA_ "VNSigAllNodes" SG_ 2151809024 DCEEC_EngyPct1 1;
BA_ "SignalType" SG_ 2151809024 DCEEC_EngyPct1 "UNM";
BA_ "PacketOrder" SG_ 2151809024 DCEEC_EngyPct1 1;
BA_ "SignalLongName" SG_ 2151809024 DCEEC_EngyPct1 "Drive Cycle Electrical Energy Consumed : Energy Percent 1";
BA_ "GenSigSendOnInit" SG_ 2151858176 DrvCycElecEngySt4 1;
BA_ "GenSigSendType" SG_ 2151858176 DrvCycElecEngySt4 12;
BA_ "GenSigDeltaValue" SG_ 2151858176 DrvCycElecEngySt4 1;
BA_ "VNSigAllNodes" SG_ 2151858176 DrvCycElecEngySt4 1;
BA_ "SignalType" SG_ 2151858176 DrvCycElecEngySt4 "UNM";
BA_ "SignalLongName" SG_ 2151858176 DrvCycElecEngySt4 "Drive Cycle Electrical Energy State 4";
BA_ "GenSigSendOnInit" SG_ 2151858176 DrvCycElecEngySt3 1;
BA_ "GenSigSendType" SG_ 2151858176 DrvCycElecEngySt3 12;
BA_ "GenSigDeltaValue" SG_ 2151858176 DrvCycElecEngySt3 1;
BA_ "VNSigAllNodes" SG_ 2151858176 DrvCycElecEngySt3 1;
BA_ "SignalType" SG_ 2151858176 DrvCycElecEngySt3 "UNM";
BA_ "SignalLongName" SG_ 2151858176 DrvCycElecEngySt3 "Drive Cycle Electrical Energy State 3";
BA_ "GenSigSendOnInit" SG_ 2151858176 DrvCycElecEngySt2 1;
BA_ "GenSigSendType" SG_ 2151858176 DrvCycElecEngySt2 12;
BA_ "GenSigDeltaValue" SG_ 2151858176 DrvCycElecEngySt2 1;
BA_ "VNSigAllNodes" SG_ 2151858176 DrvCycElecEngySt2 1;
BA_ "SignalType" SG_ 2151858176 DrvCycElecEngySt2 "UNM";
BA_ "SignalLongName" SG_ 2151858176 DrvCycElecEngySt2 "Drive Cycle Electrical Energy State 2";
BA_ "GenSigSendOnInit" SG_ 2151858176 DrvCycElecEngySt1 1;
BA_ "GenSigSendType" SG_ 2151858176 DrvCycElecEngySt1 12;
BA_ "GenSigDeltaValue" SG_ 2151858176 DrvCycElecEngySt1 1;
BA_ "VNSigAllNodes" SG_ 2151858176 DrvCycElecEngySt1 1;
BA_ "SignalType" SG_ 2151858176 DrvCycElecEngySt1 "UNM";
BA_ "SignalLongName" SG_ 2151858176 DrvCycElecEngySt1 "Drive Cycle Electrical Energy State 1";
BA_ "VNSigAllNodes" SG_ 2150023168 OffBrdVehImmbNot 1;
BA_ "SignalType" SG_ 2150023168 OffBrdVehImmbNot "ENM";
BA_ "SignalLongName" SG_ 2150023168 OffBrdVehImmbNot "Off Board Vehicle Immobilization Notification";
BA_ "VNSigAllNodes" SG_ 2150023168 ElecPrplsnMtrTach 1;
BA_ "SignalType" SG_ 2150023168 ElecPrplsnMtrTach "UNM";
BA_ "SignalLongName" SG_ 2150023168 ElecPrplsnMtrTach "Electric Propulsion Motor Tachometer";
BA_ "GenSigSendOnInit" SG_ 2150023168 HVInvRatVltV 1;
BA_ "VNSigAllNodes" SG_ 2150023168 HVInvRatVltV 1;
BA_ "SignalType" SG_ 2150023168 HVInvRatVltV "ENM";
BA_ "SignalLongName" SG_ 2150023168 HVInvRatVltV "High Voltage Inverter Rationalized Voltage  Validity";
BA_ "GenSigSendOnInit" SG_ 2150023168 HVInvRatVlt 1;
BA_ "VNSigAllNodes" SG_ 2150023168 HVInvRatVlt 1;
BA_ "SignalType" SG_ 2150023168 HVInvRatVlt "UNM";
BA_ "SignalLongName" SG_ 2150023168 HVInvRatVlt "High Voltage Inverter Rationalized Voltage";
BA_ "GenSigSendOnInit" SG_ 2150023168 HybChrgMdStat 1;
BA_ "VNSigAllNodes" SG_ 2150023168 HybChrgMdStat 1;
BA_ "SignalType" SG_ 2150023168 HybChrgMdStat "ENM";
BA_ "SignalLongName" SG_ 2150023168 HybChrgMdStat "Hybrid Charge Mode State";
BA_ "GenSigSendOnInit" SG_ 2153988096 EUS_TtEngyUsgScrAvVal 1;
BA_ "GenSigSendType" SG_ 2153988096 EUS_TtEngyUsgScrAvVal 12;
BA_ "GenSigDeltaValue" SG_ 2153988096 EUS_TtEngyUsgScrAvVal 1;
BA_ "VNSigAllNodes" SG_ 2153988096 EUS_TtEngyUsgScrAvVal 1;
BA_ "SignalType" SG_ 2153988096 EUS_TtEngyUsgScrAvVal "SNM";
BA_ "PacketOrder" SG_ 2153988096 EUS_TtEngyUsgScrAvVal 5;
BA_ "SignalLongName" SG_ 2153988096 EUS_TtEngyUsgScrAvVal "Energy Usage Score : Total Energy Usage Score Value";
BA_ "GenSigSendOnInit" SG_ 2153988096 EUS_ITEngyUsgScrAvVal 1;
BA_ "GenSigSendType" SG_ 2153988096 EUS_ITEngyUsgScrAvVal 12;
BA_ "GenSigDeltaValue" SG_ 2153988096 EUS_ITEngyUsgScrAvVal 1;
BA_ "VNSigAllNodes" SG_ 2153988096 EUS_ITEngyUsgScrAvVal 1;
BA_ "SignalType" SG_ 2153988096 EUS_ITEngyUsgScrAvVal "SNM";
BA_ "PacketOrder" SG_ 2153988096 EUS_ITEngyUsgScrAvVal 4;
BA_ "SignalLongName" SG_ 2153988096 EUS_ITEngyUsgScrAvVal "Energy Usage Score : Inside Temperature Energy Usage Score Average Value";
BA_ "GenSigSendOnInit" SG_ 2153988096 EUS_OTEngyUsgScrAvVal 1;
BA_ "GenSigSendType" SG_ 2153988096 EUS_OTEngyUsgScrAvVal 12;
BA_ "GenSigDeltaValue" SG_ 2153988096 EUS_OTEngyUsgScrAvVal 1;
BA_ "VNSigAllNodes" SG_ 2153988096 EUS_OTEngyUsgScrAvVal 1;
BA_ "SignalType" SG_ 2153988096 EUS_OTEngyUsgScrAvVal "SNM";
BA_ "PacketOrder" SG_ 2153988096 EUS_OTEngyUsgScrAvVal 3;
BA_ "SignalLongName" SG_ 2153988096 EUS_OTEngyUsgScrAvVal "Energy Usage Score : Outside Temperature Energy Usage Score Average Value";
BA_ "GenSigSendOnInit" SG_ 2153988096 EUS_TrEngyUsgScrAvVal 1;
BA_ "GenSigSendType" SG_ 2153988096 EUS_TrEngyUsgScrAvVal 12;
BA_ "GenSigDeltaValue" SG_ 2153988096 EUS_TrEngyUsgScrAvVal 1;
BA_ "VNSigAllNodes" SG_ 2153988096 EUS_TrEngyUsgScrAvVal 1;
BA_ "SignalType" SG_ 2153988096 EUS_TrEngyUsgScrAvVal "SNM";
BA_ "PacketOrder" SG_ 2153988096 EUS_TrEngyUsgScrAvVal 2;
BA_ "SignalLongName" SG_ 2153988096 EUS_TrEngyUsgScrAvVal "Energy Usage Score : Terrain Energy Usage Score Average Value";
BA_ "GenSigSendOnInit" SG_ 2153988096 EUS_TcEngyUsgScrAvVal 1;
BA_ "GenSigSendType" SG_ 2153988096 EUS_TcEngyUsgScrAvVal 12;
BA_ "GenSigDeltaValue" SG_ 2153988096 EUS_TcEngyUsgScrAvVal 1;
BA_ "VNSigAllNodes" SG_ 2153988096 EUS_TcEngyUsgScrAvVal 1;
BA_ "SignalType" SG_ 2153988096 EUS_TcEngyUsgScrAvVal "SNM";
BA_ "PacketOrder" SG_ 2153988096 EUS_TcEngyUsgScrAvVal 1;
BA_ "SignalLongName" SG_ 2153988096 EUS_TcEngyUsgScrAvVal "Energy Usage Score : Technique Energy Usage Score Average Value";
BA_ "GenSigSendOnInit" SG_ 2153988096 PwrElecCoolLpTempM 1;
BA_ "GenSigSendType" SG_ 2153988096 PwrElecCoolLpTempM 10;
BA_ "VNSigAllNodes" SG_ 2153988096 PwrElecCoolLpTempM 1;
BA_ "SignalType" SG_ 2153988096 PwrElecCoolLpTempM "ENM";
BA_ "SignalLongName" SG_ 2153988096 PwrElecCoolLpTempM "Power Electronics Cooling Loop Temperature Mask";
BA_ "GenSigSendOnInit" SG_ 2153988096 PwrElecCoolLpTempV 1;
BA_ "GenSigSendType" SG_ 2153988096 PwrElecCoolLpTempV 10;
BA_ "VNSigAllNodes" SG_ 2153988096 PwrElecCoolLpTempV 1;
BA_ "SignalType" SG_ 2153988096 PwrElecCoolLpTempV "ENM";
BA_ "SignalLongName" SG_ 2153988096 PwrElecCoolLpTempV "Power Electronics Cooling Loop Temperature Validity";
BA_ "GenSigSendOnInit" SG_ 2153988096 PwrElecCoolLpTemp 1;
BA_ "GenSigSendType" SG_ 2153988096 PwrElecCoolLpTemp 12;
BA_ "GenSigDeltaValue" SG_ 2153988096 PwrElecCoolLpTemp 1;
BA_ "VNSigAllNodes" SG_ 2153988096 PwrElecCoolLpTemp 1;
BA_ "SignalType" SG_ 2153988096 PwrElecCoolLpTemp "UNM";
BA_ "SignalLongName" SG_ 2153988096 PwrElecCoolLpTemp "Power Electronics Cooling Loop Temperature";
BA_ "VNSigDiagnostic" SG_ 1516 DgnInf_LS5EC 1;
BA_ "VNSigAllNodes" SG_ 1516 DgnInf_LS5EC 1;
BA_ "SignalType" SG_ 1516 DgnInf_LS5EC "UNM";
BA_ "SignalLongName" SG_ 1516 DgnInf_LS5EC "Diagnostic Information LS5EC";
BA_ "GenSigSendOnInit" SG_ 2155233280 RtBsChrgCmplnTmPrfRsp 1;
BA_ "GenSigSendType" SG_ 2155233280 RtBsChrgCmplnTmPrfRsp 10;
BA_ "VNSigAllNodes" SG_ 2155233280 RtBsChrgCmplnTmPrfRsp 1;
BA_ "SignalType" SG_ 2155233280 RtBsChrgCmplnTmPrfRsp "ENM";
BA_ "SignalLongName" SG_ 2155233280 RtBsChrgCmplnTmPrfRsp "Rate Based Charge Completion Time Preference Response";
BA_ "GenSigSendType" SG_ 2155233280 EngRnngDutoVehSpdIO 10;
BA_ "VNSigAllNodes" SG_ 2155233280 EngRnngDutoVehSpdIO 1;
BA_ "SignalType" SG_ 2155233280 EngRnngDutoVehSpdIO "BLN";
BA_ "SignalLongName" SG_ 2155233280 EngRnngDutoVehSpdIO "Engine Running Due to Vehicle Speed Indication On";
BA_ "GenSigSendOnInit" SG_ 2155233280 ChrgCyclFuelEcn 1;
BA_ "GenSigSendType" SG_ 2155233280 ChrgCyclFuelEcn 12;
BA_ "GenSigDeltaValue" SG_ 2155233280 ChrgCyclFuelEcn 1;
BA_ "VNSigAllNodes" SG_ 2155233280 ChrgCyclFuelEcn 1;
BA_ "SignalType" SG_ 2155233280 ChrgCyclFuelEcn "UNM";
BA_ "SignalLongName" SG_ 2155233280 ChrgCyclFuelEcn "Charge Cycle Fuel Economy";
BA_ "GenSigSendOnInit" SG_ 2155233280 LiftimeFuelEcnEquiv 1;
BA_ "GenSigSendType" SG_ 2155233280 LiftimeFuelEcnEquiv 12;
BA_ "GenSigDeltaValue" SG_ 2155233280 LiftimeFuelEcnEquiv 1;
BA_ "VNSigAllNodes" SG_ 2155233280 LiftimeFuelEcnEquiv 1;
BA_ "SignalType" SG_ 2155233280 LiftimeFuelEcnEquiv "UNM";
BA_ "SignalLongName" SG_ 2155233280 LiftimeFuelEcnEquiv "Lifetime Fuel Economy Equivalent";
BA_ "GenSigSendType" SG_ 2155233280 ShftPrkIO_3B2 10;
BA_ "VNSigAllNodes" SG_ 2155233280 ShftPrkIO_3B2 1;
BA_ "SignalType" SG_ 2155233280 ShftPrkIO_3B2 "BLN";
BA_ "SignalLongName" SG_ 2155233280 ShftPrkIO_3B2 "Shift to Park Indication On";
BA_ "GenSigSendOnInit" SG_ 2155233280 LftmFuelEcon 1;
BA_ "GenSigSendType" SG_ 2155233280 LftmFuelEcon 12;
BA_ "GenSigDeltaValue" SG_ 2155233280 LftmFuelEcon 1;
BA_ "VNSigAllNodes" SG_ 2155233280 LftmFuelEcon 1;
BA_ "SignalType" SG_ 2155233280 LftmFuelEcon "UNM";
BA_ "SignalLongName" SG_ 2155233280 LftmFuelEcon "Lifetime Fuel Economy";
BA_ "GenSigSendType" SG_ 2155233280 FlDrOpenIndOn 10;
BA_ "VNSigAllNodes" SG_ 2155233280 FlDrOpenIndOn 1;
BA_ "SignalType" SG_ 2155233280 FlDrOpenIndOn "BLN";
BA_ "SignalLongName" SG_ 2155233280 FlDrOpenIndOn "Fuel Door Open Indication On";
BA_ "GenSigSendType" SG_ 2155233280 VehRefuelSt 10;
BA_ "VNSigAllNodes" SG_ 2155233280 VehRefuelSt 1;
BA_ "SignalType" SG_ 2155233280 VehRefuelSt "ENM";
BA_ "SignalLongName" SG_ 2155233280 VehRefuelSt "Vehicle Refueling State";
BA_ "GenSigSendType" SG_ 2155233280 NtrlCstdwnCrtMdActvIO 10;
BA_ "VNSigAllNodes" SG_ 2155233280 NtrlCstdwnCrtMdActvIO 1;
BA_ "SignalType" SG_ 2155233280 NtrlCstdwnCrtMdActvIO "BLN";
BA_ "SignalLongName" SG_ 2155233280 NtrlCstdwnCrtMdActvIO "Neutral Coastdown Certification Mode Active Indication On";
BA_ "GenSigSendOnInit" SG_ 2155233280 UtlChrgPopUpAct 1;
BA_ "GenSigSendType" SG_ 2155233280 UtlChrgPopUpAct 10;
BA_ "VNSigAllNodes" SG_ 2155233280 UtlChrgPopUpAct 1;
BA_ "SignalType" SG_ 2155233280 UtlChrgPopUpAct "BLN";
BA_ "SignalLongName" SG_ 2155233280 UtlChrgPopUpAct "Utility Charging Interference Pop Up Active";
BA_ "GenSigSendOnInit" SG_ 2155233280 UtlChrgIntrfrIO 1;
BA_ "GenSigSendType" SG_ 2155233280 UtlChrgIntrfrIO 10;
BA_ "VNSigAllNodes" SG_ 2155233280 UtlChrgIntrfrIO 1;
BA_ "SignalType" SG_ 2155233280 UtlChrgIntrfrIO "BLN";
BA_ "SignalLongName" SG_ 2155233280 UtlChrgIntrfrIO "Utility Charging Interference Indication On";
BA_ "GenSigSendType" SG_ 2155233280 InstnsFlEcnHybOvrdReq 10;
BA_ "VNSigAllNodes" SG_ 2155233280 InstnsFlEcnHybOvrdReq 1;
BA_ "SignalType" SG_ 2155233280 InstnsFlEcnHybOvrdReq "ENM";
BA_ "SignalLongName" SG_ 2155233280 InstnsFlEcnHybOvrdReq "Instantaneous Fuel Economy Hybrid Override Request";
BA_ "GenSigSendType" SG_ 2155233280 NtrlGrWrngIO 10;
BA_ "VNSigAllNodes" SG_ 2155233280 NtrlGrWrngIO 1;
BA_ "SignalType" SG_ 2155233280 NtrlGrWrngIO "BLN";
BA_ "SignalLongName" SG_ 2155233280 NtrlGrWrngIO "Neutral Gear Warning Indication On";
BA_ "VNSigDiagnostic" SG_ 2028 DgnInf 1;
BA_ "GenSigSendType" SG_ 2028 DgnInf 12;
BA_ "GenSigDeltaValue" SG_ 2028 DgnInf 1;
BA_ "VNSigAllNodes" SG_ 2028 DgnInf 1;
BA_ "SignalType" SG_ 2028 DgnInf "UNM";
BA_ "SignalLongName" SG_ 2028 DgnInf "Diagnostic Information";
BA_ "VNSigIntermediate" SG_ 2150121472 RmtTrlrLtngSeqReq 1;
BA_ "GenSigSendOnInit" SG_ 2150121472 RmtTrlrLtngSeqReq 2;
BA_ "GenSigSendType" SG_ 2150121472 RmtTrlrLtngSeqReq 10;
BA_ "VNSigAllNodes" SG_ 2150121472 RmtTrlrLtngSeqReq 1;
BA_ "SignalType" SG_ 2150121472 RmtTrlrLtngSeqReq "ENM";
BA_ "SignalLongName" SG_ 2150121472 RmtTrlrLtngSeqReq "Remote Trailer Lighting Sequence Request";
BA_ "GenSigSendType" SG_ 2150105088 TrlrLghtAlrtEnbld 10;
BA_ "VNSigAllNodes" SG_ 2150105088 TrlrLghtAlrtEnbld 1;
BA_ "SignalType" SG_ 2150105088 TrlrLghtAlrtEnbld "BLN";
BA_ "SignalLongName" SG_ 2150105088 TrlrLghtAlrtEnbld "Trailer Light Alerts Enabled";
BA_ "GenSigSendType" SG_ 2150105088 TrlRvsLghtFldEnbld 10;
BA_ "VNSigAllNodes" SG_ 2150105088 TrlRvsLghtFldEnbld 1;
BA_ "SignalType" SG_ 2150105088 TrlRvsLghtFldEnbld "BLN";
BA_ "SignalLongName" SG_ 2150105088 TrlRvsLghtFldEnbld "Trailer Reverse Light Failed Enabled";
BA_ "GenSigSendType" SG_ 2150105088 TrlrThftAlrtEnbld 10;
BA_ "VNSigAllNodes" SG_ 2150105088 TrlrThftAlrtEnbld 1;
BA_ "SignalType" SG_ 2150105088 TrlrThftAlrtEnbld "BLN";
BA_ "SignalLongName" SG_ 2150105088 TrlrThftAlrtEnbld "Trailer Theft Alert Enabled";
BA_ "GenSigSendOnInit" SG_ 2150105088 TrlrLtngSeqReq 2;
BA_ "GenSigSendType" SG_ 2150105088 TrlrLtngSeqReq 10;
BA_ "VNSigAllNodes" SG_ 2150105088 TrlrLtngSeqReq 1;
BA_ "SignalType" SG_ 2150105088 TrlrLtngSeqReq "ENM";
BA_ "SignalLongName" SG_ 2150105088 TrlrLtngSeqReq "Trailer Lighting Sequence Request";
BA_ "GenSigSendOnInit" SG_ 2152013824 SmrtHgBmAstCstSetAvail 2;
BA_ "GenSigSendType" SG_ 2152013824 SmrtHgBmAstCstSetAvail 10;
BA_ "VNSigAllNodes" SG_ 2152013824 SmrtHgBmAstCstSetAvail 1;
BA_ "SignalType" SG_ 2152013824 SmrtHgBmAstCstSetAvail "BLN";
BA_ "SignalLongName" SG_ 2152013824 SmrtHgBmAstCstSetAvail "Smart High Beam Assist Customization Setting Available";
BA_ "GenSigSendOnInit" SG_ 2152013824 SmrtHgBmAstCstCurrSetVal 2;
BA_ "GenSigSendType" SG_ 2152013824 SmrtHgBmAstCstCurrSetVal 10;
BA_ "VNSigAllNodes" SG_ 2152013824 SmrtHgBmAstCstCurrSetVal 1;
BA_ "SignalType" SG_ 2152013824 SmrtHgBmAstCstCurrSetVal "ENM";
BA_ "SignalLongName" SG_ 2152013824 SmrtHgBmAstCstCurrSetVal "Smart High Beam Assist Customization Current Setting Value";
BA_ "GenSigSendType" SG_ 2159255552 ODI_CntrStck2BCM 12;
BA_ "GenSigDeltaValue" SG_ 2159255552 ODI_CntrStck2BCM 1;
BA_ "VNSigAllNodes" SG_ 2159255552 ODI_CntrStck2BCM 1;
BA_ "SignalType" SG_ 2159255552 ODI_CntrStck2BCM "UNM";
BA_ "SignalLongName" SG_ 2159255552 ODI_CntrStck2BCM "Open Display Interface CenterStack 2 BCM";
BA_ "GenSigSendType" SG_ 2151817216 HtdFrntWSCustRq 10;
BA_ "VNSigAllNodes" SG_ 2151817216 HtdFrntWSCustRq 1;
BA_ "SignalType" SG_ 2151817216 HtdFrntWSCustRq "BLN";
BA_ "SignalLongName" SG_ 2151817216 HtdFrntWSCustRq "Heated Front Windshield Customer Request";
BA_ "GenSigSendType" SG_ 2151849984 AutoThrmlStPassMdStRq 10;
BA_ "VNSigAllNodes" SG_ 2151849984 AutoThrmlStPassMdStRq 1;
BA_ "SignalType" SG_ 2151849984 AutoThrmlStPassMdStRq "ENM";
BA_ "SignalLongName" SG_ 2151849984 AutoThrmlStPassMdStRq "Auto Thermal Seat Passenger Mode Setting Request";
BA_ "GenSigSendType" SG_ 2151849984 AutoThrmlStDrvMdStRq 10;
BA_ "VNSigAllNodes" SG_ 2151849984 AutoThrmlStDrvMdStRq 1;
BA_ "SignalType" SG_ 2151849984 AutoThrmlStDrvMdStRq "ENM";
BA_ "SignalLongName" SG_ 2151849984 AutoThrmlStDrvMdStRq "Auto Thermal Seat Driver Mode Setting Request";
BA_ "GenSigSendType" SG_ 2151849984 AutoThrmlStPasLvlStRq 10;
BA_ "VNSigAllNodes" SG_ 2151849984 AutoThrmlStPasLvlStRq 1;
BA_ "SignalType" SG_ 2151849984 AutoThrmlStPasLvlStRq "ENM";
BA_ "SignalLongName" SG_ 2151849984 AutoThrmlStPasLvlStRq "Auto Thermal Seat Passenger Level Setting Request";
BA_ "GenSigSendType" SG_ 2151849984 AutoThrmlStDrvLvStRq 10;
BA_ "VNSigAllNodes" SG_ 2151849984 AutoThrmlStDrvLvStRq 1;
BA_ "SignalType" SG_ 2151849984 AutoThrmlStDrvLvStRq "ENM";
BA_ "SignalLongName" SG_ 2151849984 AutoThrmlStDrvLvStRq "Auto Thermal Seat Driver Level Setting Request";
BA_ "VNSigAllNodes" SG_ 2154618880 ClmCntPrtyHtRqV 1;
BA_ "SignalType" SG_ 2154618880 ClmCntPrtyHtRqV "ENM";
BA_ "SignalLongName" SG_ 2154618880 ClmCntPrtyHtRqV "Climate Control Priority Heating Request Validity";
BA_ "VNSigAllNodes" SG_ 2154618880 ClmCntPrtyHtRq 1;
BA_ "SignalType" SG_ 2154618880 ClmCntPrtyHtRq "ENM";
BA_ "SignalLongName" SG_ 2154618880 ClmCntPrtyHtRq "Climate Control Priority Heating Request";
BA_ "GenSigStartValue" SG_ 2154618880 ClmCntPrtyHtRq 2;
BA_ "VNSigAllNodes" SG_ 2154618880 ClmCntCalcTrgtCbnHtLdV 1;
BA_ "SignalType" SG_ 2154618880 ClmCntCalcTrgtCbnHtLdV "ENM";
BA_ "SignalLongName" SG_ 2154618880 ClmCntCalcTrgtCbnHtLdV "Climate Control Calculated Target Cabin Heat Load Validity";
BA_ "VNSigAllNodes" SG_ 2154618880 ClmCntCalcTrgtCbnHtLd 1;
BA_ "SignalType" SG_ 2154618880 ClmCntCalcTrgtCbnHtLd "UNM";
BA_ "SignalLongName" SG_ 2154618880 ClmCntCalcTrgtCbnHtLd "Climate Control Calculated Target Cabin Heat Load";
BA_ "GenSigStartValue" SG_ 2154618880 ClmCntCalcTrgtCbnHtLd 95.625149414296;
BA_ "VNSigAllNodes" SG_ 2154618880 ClmCntMinTrgtClntTmpV 1;
BA_ "SignalType" SG_ 2154618880 ClmCntMinTrgtClntTmpV "ENM";
BA_ "SignalLongName" SG_ 2154618880 ClmCntMinTrgtClntTmpV "Climate Control Minimum Target Coolant Temperature Validity";
BA_ "VNSigAllNodes" SG_ 2154618880 ClmCntMinTrgtClntTmp 1;
BA_ "SignalType" SG_ 2154618880 ClmCntMinTrgtClntTmp "UNM";
BA_ "SignalLongName" SG_ 2154618880 ClmCntMinTrgtClntTmp "Climate Control Minimum Target Coolant Temperature";
BA_ "GenSigStartValue" SG_ 2154618880 ClmCntMinTrgtClntTmp 165.748674010608;
BA_ "VNSigAllNodes" SG_ 2154618880 ClmCntHtrMinFlwRtRqV 1;
BA_ "SignalType" SG_ 2154618880 ClmCntHtrMinFlwRtRqV "ENM";
BA_ "SignalLongName" SG_ 2154618880 ClmCntHtrMinFlwRtRqV "Climate Control Heater Minimum Flow Rate Request Validity";
BA_ "VNSigAllNodes" SG_ 2154618880 ClmCntHtrMinFlwRtRq 1;
BA_ "SignalType" SG_ 2154618880 ClmCntHtrMinFlwRtRq "UNM";
BA_ "SignalLongName" SG_ 2154618880 ClmCntHtrMinFlwRtRq "Climate Control Heater Minimum Flow Rate Request";
BA_ "GenSigStartValue" SG_ 2154618880 ClmCntHtrMinFlwRtRq 47.812574707148;
BA_ "GenSigSendType" SG_ 2150129664 HtVwAutnmsEPBAplyReqd 10;
BA_ "VNSigAllNodes" SG_ 2150129664 HtVwAutnmsEPBAplyReqd 1;
BA_ "SignalType" SG_ 2150129664 HtVwAutnmsEPBAplyReqd "BLN";
BA_ "SignalLongName" SG_ 2150129664 HtVwAutnmsEPBAplyReqd "Hitch View Autonomous Electric Park Brake Apply Requested";
BA_ "GenSigSendOnInit" SG_ 2155216896 DgtlMapPstdSpdLimAsrd 1;
BA_ "GenSigSendType" SG_ 2155216896 DgtlMapPstdSpdLimAsrd 10;
BA_ "VNSigAllNodes" SG_ 2155216896 DgtlMapPstdSpdLimAsrd 1;
BA_ "SignalType" SG_ 2155216896 DgtlMapPstdSpdLimAsrd "BLN";
BA_ "SignalLongName" SG_ 2155216896 DgtlMapPstdSpdLimAsrd "Digital Map Posted Speed Limit Assured";
BA_ "GenSigSendType" SG_ 2155216896 SpdLmtPstdSpdM 10;
BA_ "VNSigAllNodes" SG_ 2155216896 SpdLmtPstdSpdM 1;
BA_ "SignalType" SG_ 2155216896 SpdLmtPstdSpdM "ENM";
BA_ "SignalLongName" SG_ 2155216896 SpdLmtPstdSpdM "Speed Limit Posted Speed Mask";
BA_ "GenSigSendType" SG_ 2155216896 CurvAdvInd 10;
BA_ "VNSigAllNodes" SG_ 2155216896 CurvAdvInd 1;
BA_ "SignalType" SG_ 2155216896 CurvAdvInd "ENM";
BA_ "SignalLongName" SG_ 2155216896 CurvAdvInd "Curve Advisory Indication";
BA_ "GenSigSendType" SG_ 2155216896 SpdLmtRecmndSpd 12;
BA_ "GenSigDeltaValue" SG_ 2155216896 SpdLmtRecmndSpd 1;
BA_ "VNSigAllNodes" SG_ 2155216896 SpdLmtRecmndSpd 1;
BA_ "SignalType" SG_ 2155216896 SpdLmtRecmndSpd "UNM";
BA_ "SignalLongName" SG_ 2155216896 SpdLmtRecmndSpd "Speed Limit Recommended Speed";
BA_ "GenSigSendType" SG_ 2155216896 SpdLmtPstdSpd 12;
BA_ "GenSigDeltaValue" SG_ 2155216896 SpdLmtPstdSpd 1;
BA_ "VNSigAllNodes" SG_ 2155216896 SpdLmtPstdSpd 1;
BA_ "SignalType" SG_ 2155216896 SpdLmtPstdSpd "UNM";
BA_ "SignalLongName" SG_ 2155216896 SpdLmtPstdSpd "Speed Limit Posted Speed";
BA_ "GenSigSendType" SG_ 2155216896 ISA2CCC_ScndCdChr 10;
BA_ "VNSigAllNodes" SG_ 2155216896 ISA2CCC_ScndCdChr 1;
BA_ "SignalType" SG_ 2155216896 ISA2CCC_ScndCdChr "ENM";
BA_ "PacketOrder" SG_ 2155216896 ISA2CCC_ScndCdChr 2;
BA_ "SignalLongName" SG_ 2155216896 ISA2CCC_ScndCdChr "International Standard Alpha 2 Coded Country Code : Second Code Character";
BA_ "GenSigSendType" SG_ 2155216896 ISA2CCC_FrstCdChr 10;
BA_ "VNSigAllNodes" SG_ 2155216896 ISA2CCC_FrstCdChr 1;
BA_ "SignalType" SG_ 2155216896 ISA2CCC_FrstCdChr "ENM";
BA_ "PacketOrder" SG_ 2155216896 ISA2CCC_FrstCdChr 1;
BA_ "SignalLongName" SG_ 2155216896 ISA2CCC_FrstCdChr "International Standard Alpha 2 Coded Country Code : First Code Character";
BA_ "GenSigSendType" SG_ 2155216896 SpdLmtUnits 10;
BA_ "VNSigAllNodes" SG_ 2155216896 SpdLmtUnits 1;
BA_ "SignalType" SG_ 2155216896 SpdLmtUnits "ENM";
BA_ "SignalLongName" SG_ 2155216896 SpdLmtUnits "Speed Limit Units";
BA_ "GenSigSendOnInit" SG_ 2155216896 LnCat 1;
BA_ "GenSigSendType" SG_ 2155216896 LnCat 10;
BA_ "VNSigAllNodes" SG_ 2155216896 LnCat 1;
BA_ "SignalType" SG_ 2155216896 LnCat "ENM";
BA_ "SignalLongName" SG_ 2155216896 LnCat "Lane Category";
BA_ "GenSigSendOnInit" SG_ 2155216896 RdSpdCatType 1;
BA_ "GenSigSendType" SG_ 2155216896 RdSpdCatType 10;
BA_ "VNSigAllNodes" SG_ 2155216896 RdSpdCatType 1;
BA_ "SignalType" SG_ 2155216896 RdSpdCatType "ENM";
BA_ "SignalLongName" SG_ 2155216896 RdSpdCatType "Road Speed Category Type";
BA_ "GenSigSendOnInit" SG_ 2155216896 FncRdClass 1;
BA_ "GenSigSendType" SG_ 2155216896 FncRdClass 10;
BA_ "VNSigAllNodes" SG_ 2155216896 FncRdClass 1;
BA_ "SignalType" SG_ 2155216896 FncRdClass "ENM";
BA_ "SignalLongName" SG_ 2155216896 FncRdClass "Functional Road Class";
BA_ "GenSigSendOnInit" SG_ 2155216896 SprtLnRd 1;
BA_ "GenSigSendType" SG_ 2155216896 SprtLnRd 10;
BA_ "VNSigAllNodes" SG_ 2155216896 SprtLnRd 1;
BA_ "SignalType" SG_ 2155216896 SprtLnRd "BLN";
BA_ "SignalLongName" SG_ 2155216896 SprtLnRd "Separate Lane Road";
BA_ "GenSigSendOnInit" SG_ 2155216896 CntrldAccRd 1;
BA_ "GenSigSendType" SG_ 2155216896 CntrldAccRd 10;
BA_ "VNSigAllNodes" SG_ 2155216896 CntrldAccRd 1;
BA_ "SignalType" SG_ 2155216896 CntrldAccRd "BLN";
BA_ "SignalLongName" SG_ 2155216896 CntrldAccRd "Controlled Access Road";
BA_ "GenSigSendOnInit" SG_ 2155216896 BldUpArDet 1;
BA_ "GenSigSendType" SG_ 2155216896 BldUpArDet 10;
BA_ "VNSigAllNodes" SG_ 2155216896 BldUpArDet 1;
BA_ "SignalType" SG_ 2155216896 BldUpArDet "BLN";
BA_ "SignalLongName" SG_ 2155216896 BldUpArDet "Build Up Area Detected";
BA_ "GenSigSendOnInit" SG_ 2155216896 MpDataAvlbl 1;
BA_ "GenSigSendType" SG_ 2155216896 MpDataAvlbl 10;
BA_ "VNSigAllNodes" SG_ 2155216896 MpDataAvlbl 1;
BA_ "SignalType" SG_ 2155216896 MpDataAvlbl "BLN";
BA_ "SignalLongName" SG_ 2155216896 MpDataAvlbl "Map Data Available";
BA_ "GenSigSendType" SG_ 2150277120 PsngSysLongV 10;
BA_ "VNSigAllNodes" SG_ 2150277120 PsngSysLongV 1;
BA_ "SignalType" SG_ 2150277120 PsngSysLongV "ENM";
BA_ "SignalLongName" SG_ 2150277120 PsngSysLongV "Positioning System Longitude Validity";
BA_ "GenSigSendType" SG_ 2150277120 PsngSysLong 12;
BA_ "GenSigDeltaValue" SG_ 2150277120 PsngSysLong 10;
BA_ "VNSigAllNodes" SG_ 2150277120 PsngSysLong 1;
BA_ "SignalType" SG_ 2150277120 PsngSysLong "SNM";
BA_ "SignalLongName" SG_ 2150277120 PsngSysLong "Positioning System Longitude";
BA_ "GenSigSendType" SG_ 2150277120 PsngSysLatV 10;
BA_ "VNSigAllNodes" SG_ 2150277120 PsngSysLatV 1;
BA_ "SignalType" SG_ 2150277120 PsngSysLatV "ENM";
BA_ "SignalLongName" SG_ 2150277120 PsngSysLatV "Positioning System Latitude Validity";
BA_ "GenSigSendOnInit" SG_ 2150277120 PsngSysLat 2;
BA_ "GenSigSendType" SG_ 2150277120 PsngSysLat 12;
BA_ "GenSigDeltaValue" SG_ 2150277120 PsngSysLat 10;
BA_ "VNSigAllNodes" SG_ 2150277120 PsngSysLat 1;
BA_ "SignalType" SG_ 2150277120 PsngSysLat "SNM";
BA_ "SignalLongName" SG_ 2150277120 PsngSysLat "Positioning System Latitude";
BA_ "GenSigSendType" SG_ 2150285312 PsngSysCalcSpdV 10;
BA_ "VNSigAllNodes" SG_ 2150285312 PsngSysCalcSpdV 1;
BA_ "SignalType" SG_ 2150285312 PsngSysCalcSpdV "ENM";
BA_ "SignalLongName" SG_ 2150285312 PsngSysCalcSpdV "Positioning System Calculated Speed Validity";
BA_ "GenSigSendType" SG_ 2150285312 PsngSysCalcSpd 12;
BA_ "GenSigDeltaValue" SG_ 2150285312 PsngSysCalcSpd 5;
BA_ "VNSigAllNodes" SG_ 2150285312 PsngSysCalcSpd 1;
BA_ "SignalType" SG_ 2150285312 PsngSysCalcSpd "UNM";
BA_ "SignalLongName" SG_ 2150285312 PsngSysCalcSpd "Positioning System Calculated Speed";
BA_ "GenSigSendType" SG_ 2150285312 PsngSysHdingV 10;
BA_ "VNSigAllNodes" SG_ 2150285312 PsngSysHdingV 1;
BA_ "SignalType" SG_ 2150285312 PsngSysHdingV "ENM";
BA_ "SignalLongName" SG_ 2150285312 PsngSysHdingV "Positioning System Heading Validity";
BA_ "GenSigSendType" SG_ 2150285312 PsngSysHding 12;
BA_ "GenSigDeltaValue" SG_ 2150285312 PsngSysHding 50;
BA_ "VNSigAllNodes" SG_ 2150285312 PsngSysHding 1;
BA_ "SignalType" SG_ 2150285312 PsngSysHding "UNM";
BA_ "SignalLongName" SG_ 2150285312 PsngSysHding "Positioning System Heading";
BA_ "GenSigSendType" SG_ 2150285312 PsngSysElvtnV 10;
BA_ "VNSigAllNodes" SG_ 2150285312 PsngSysElvtnV 1;
BA_ "SignalType" SG_ 2150285312 PsngSysElvtnV "ENM";
BA_ "SignalLongName" SG_ 2150285312 PsngSysElvtnV "Positioning System Elevation Validity";
BA_ "GenSigSendType" SG_ 2150285312 PsngSysElvtn 12;
BA_ "GenSigDeltaValue" SG_ 2150285312 PsngSysElvtn 100;
BA_ "VNSigAllNodes" SG_ 2150285312 PsngSysElvtn 1;
BA_ "SignalType" SG_ 2150285312 PsngSysElvtn "UNM";
BA_ "SignalLongName" SG_ 2150285312 PsngSysElvtn "Positioning System Elevation";
BA_ "GenSigSendType" SG_ 2150285312 PsngSysDilPrcs 12;
BA_ "GenSigDeltaValue" SG_ 2150285312 PsngSysDilPrcs 10;
BA_ "VNSigAllNodes" SG_ 2150285312 PsngSysDilPrcs 1;
BA_ "SignalType" SG_ 2150285312 PsngSysDilPrcs "UNM";
BA_ "SignalLongName" SG_ 2150285312 PsngSysDilPrcs "Positioning System Dilution of Precision";
BA_ "GenSigSendType" SG_ 2150285312 PsngSysDilPrcsV 10;
BA_ "VNSigAllNodes" SG_ 2150285312 PsngSysDilPrcsV 1;
BA_ "SignalType" SG_ 2150285312 PsngSysDilPrcsV "ENM";
BA_ "SignalLongName" SG_ 2150285312 PsngSysDilPrcsV "Positioning System Dilution of Precision Validity";
BA_ "GenSigSendType" SG_ 2151047168 HdUpDspAnmtStat 10;
BA_ "VNSigAllNodes" SG_ 2151047168 HdUpDspAnmtStat 1;
BA_ "SignalType" SG_ 2151047168 HdUpDspAnmtStat "ENM";
BA_ "SignalLongName" SG_ 2151047168 HdUpDspAnmtStat "Head Up Display Animation Status";
BA_ "GenSigSendType" SG_ 2151047168 HUDActv 10;
BA_ "VNSigAllNodes" SG_ 2151047168 HUDActv 1;
BA_ "SignalType" SG_ 2151047168 HUDActv "BLN";
BA_ "SignalLongName" SG_ 2151047168 HUDActv "Head Up Display Active";
BA_ "GenSigSendType" SG_ 2154225664 RLDrHndleSwAtv 10;
BA_ "VNSigAllNodes" SG_ 2154225664 RLDrHndleSwAtv 1;
BA_ "SignalType" SG_ 2154225664 RLDrHndleSwAtv "BLN";
BA_ "SignalLongName" SG_ 2154225664 RLDrHndleSwAtv "Rear Left Door Handle Switch Active";
BA_ "GenSigSendType" SG_ 2154225664 RRDrHndleSwAtv 10;
BA_ "VNSigAllNodes" SG_ 2154225664 RRDrHndleSwAtv 1;
BA_ "SignalType" SG_ 2154225664 RRDrHndleSwAtv "BLN";
BA_ "SignalLongName" SG_ 2154225664 RRDrHndleSwAtv "Rear Right Door Handle Switch Active";
BA_ "GenSigSendType" SG_ 2154225664 RCHndleSwAtv 10;
BA_ "VNSigAllNodes" SG_ 2154225664 RCHndleSwAtv 1;
BA_ "SignalType" SG_ 2154225664 RCHndleSwAtv "BLN";
BA_ "SignalLongName" SG_ 2154225664 RCHndleSwAtv "Rear Closure Handle Switch Active";
BA_ "GenSigSendType" SG_ 2154225664 PasDrHndleSwAtv 10;
BA_ "VNSigAllNodes" SG_ 2154225664 PasDrHndleSwAtv 1;
BA_ "SignalType" SG_ 2154225664 PasDrHndleSwAtv "BLN";
BA_ "SignalLongName" SG_ 2154225664 PasDrHndleSwAtv "Passenger Door Handle Switch Active";
BA_ "GenSigSendType" SG_ 2154225664 DrvDrHndleSwAtv 10;
BA_ "VNSigAllNodes" SG_ 2154225664 DrvDrHndleSwAtv 1;
BA_ "SignalType" SG_ 2154225664 DrvDrHndleSwAtv "BLN";
BA_ "SignalLongName" SG_ 2154225664 DrvDrHndleSwAtv "Driver Door Handle Switch Active";
BA_ "GenSigSendType" SG_ 2149900288 BTTethrngPrngReq 10;
BA_ "VNSigAllNodes" SG_ 2149900288 BTTethrngPrngReq 1;
BA_ "SignalType" SG_ 2149900288 BTTethrngPrngReq "ENM";
BA_ "SignalLongName" SG_ 2149900288 BTTethrngPrngReq "Bluetooth Tethering Pairing Request";
BA_ "GenSigSendType" SG_ 2149900288 EnhSrvAudAlRq 10;
BA_ "VNSigAllNodes" SG_ 2149900288 EnhSrvAudAlRq 1;
BA_ "SignalType" SG_ 2149900288 EnhSrvAudAlRq "ENM";
BA_ "SignalLongName" SG_ 2149900288 EnhSrvAudAlRq "Enhanced Services Audible External Alert Request";
BA_ "GenSigSendType" SG_ 2149900288 EnhSvVehTopSpdLim 12;
BA_ "GenSigDeltaValue" SG_ 2149900288 EnhSvVehTopSpdLim 1;
BA_ "VNSigAllNodes" SG_ 2149900288 EnhSvVehTopSpdLim 1;
BA_ "SignalType" SG_ 2149900288 EnhSvVehTopSpdLim "UNM";
BA_ "SignalLongName" SG_ 2149900288 EnhSvVehTopSpdLim "Enhanced Services Vehicle Top Speed Limit Value";
BA_ "GenSigStartValue" SG_ 2149900288 EnhSvVehTopSpdLim 255;
BA_ "GenSigSendOnInit" SG_ 2149900288 EnhSrvVisAlRq 1;
BA_ "GenSigSendType" SG_ 2149900288 EnhSrvVisAlRq 10;
BA_ "VNSigAllNodes" SG_ 2149900288 EnhSrvVisAlRq 1;
BA_ "SignalType" SG_ 2149900288 EnhSrvVisAlRq "ENM";
BA_ "SignalLongName" SG_ 2149900288 EnhSrvVisAlRq "Enhanced Services Visible External Alert Request";
BA_ "GenSigSendType" SG_ 2149900288 EnhSrvRmStrtRq 10;
BA_ "VNSigAllNodes" SG_ 2149900288 EnhSrvRmStrtRq 1;
BA_ "SignalType" SG_ 2149900288 EnhSrvRmStrtRq "ENM";
BA_ "SignalLongName" SG_ 2149900288 EnhSrvRmStrtRq "Enhanced Services Remote Start Request";
BA_ "GenSigSendType" SG_ 2149900288 EnhSrvRClsRlsRq 10;
BA_ "VNSigAllNodes" SG_ 2149900288 EnhSrvRClsRlsRq 1;
BA_ "SignalType" SG_ 2149900288 EnhSrvRClsRlsRq "ENM";
BA_ "SignalLongName" SG_ 2149900288 EnhSrvRClsRlsRq "Enhanced Services Rear Closure Release Request";
BA_ "GenSigSendType" SG_ 2149900288 EnhSrvLckRq 10;
BA_ "VNSigAllNodes" SG_ 2149900288 EnhSrvLckRq 1;
BA_ "SignalType" SG_ 2149900288 EnhSrvLckRq "ENM";
BA_ "SignalLongName" SG_ 2149900288 EnhSrvLckRq "Enhanced Services Locking Request";
BA_ "GenSigSendOnInit" SG_ 2157985792 FobProgEvntRqd 2;
BA_ "GenSigSendType" SG_ 2157985792 FobProgEvntRqd 10;
BA_ "VNSigAllNodes" SG_ 2157985792 FobProgEvntRqd 1;
BA_ "SignalType" SG_ 2157985792 FobProgEvntRqd "BLN";
BA_ "SignalLongName" SG_ 2157985792 FobProgEvntRqd "Fob Programming Event Requested";
BA_ "GenSigSendType" SG_ 2155479040 DrvStyPerfMdCsStReq 10;
BA_ "VNSigAllNodes" SG_ 2155479040 DrvStyPerfMdCsStReq 1;
BA_ "SignalType" SG_ 2155479040 DrvStyPerfMdCsStReq "ENM";
BA_ "SignalLongName" SG_ 2155479040 DrvStyPerfMdCsStReq "Driving Style Performance Mode Customization Setting Request";
BA_ "GenSigSendType" SG_ 2155479040 PsngStPerfMdCsStReq 10;
BA_ "VNSigAllNodes" SG_ 2155479040 PsngStPerfMdCsStReq 1;
BA_ "SignalType" SG_ 2155479040 PsngStPerfMdCsStReq "ENM";
BA_ "SignalLongName" SG_ 2155479040 PsngStPerfMdCsStReq "Passenger Seat Performance Mode Customization Setting Request";
BA_ "GenSigSendType" SG_ 2155479040 DrvrStPerfMdCsStReq 10;
BA_ "VNSigAllNodes" SG_ 2155479040 DrvrStPerfMdCsStReq 1;
BA_ "SignalType" SG_ 2155479040 DrvrStPerfMdCsStReq "ENM";
BA_ "SignalLongName" SG_ 2155479040 DrvrStPerfMdCsStReq "Driver Seat Performance Mode Customization Setting Request";
BA_ "GenSigSendType" SG_ 2155479040 ACCPerfMdCsStReq 10;
BA_ "VNSigAllNodes" SG_ 2155479040 ACCPerfMdCsStReq 1;
BA_ "SignalType" SG_ 2155479040 ACCPerfMdCsStReq "ENM";
BA_ "SignalLongName" SG_ 2155479040 ACCPerfMdCsStReq "Adaptive Cruise Control Performance Mode Customization Setting Request";
BA_ "GenSigSendType" SG_ 2155479040 ElvtdIdlCstStReq 10;
BA_ "VNSigAllNodes" SG_ 2155479040 ElvtdIdlCstStReq 1;
BA_ "SignalType" SG_ 2155479040 ElvtdIdlCstStReq "ENM";
BA_ "SignalLongName" SG_ 2155479040 ElvtdIdlCstStReq "Elevated Idle Customization Setting Request";
BA_ "GenSigSendType" SG_ 2155479040 PedFrndlyAlrtCsStReq 10;
BA_ "VNSigAllNodes" SG_ 2155479040 PedFrndlyAlrtCsStReq 1;
BA_ "SignalType" SG_ 2155479040 PedFrndlyAlrtCsStReq "ENM";
BA_ "SignalLongName" SG_ 2155479040 PedFrndlyAlrtCsStReq "Pedestrian Friendly Alert Customization Setting Request";
BA_ "GenSigSendType" SG_ 2155479040 SndPerfMdCsStRq 10;
BA_ "VNSigAllNodes" SG_ 2155479040 SndPerfMdCsStRq 1;
BA_ "SignalType" SG_ 2155479040 SndPerfMdCsStRq "ENM";
BA_ "SignalLongName" SG_ 2155479040 SndPerfMdCsStRq "Sound Performance Mode Customization Setting Request";
BA_ "GenSigSendType" SG_ 2155479040 DispPerfMdCsStRq 10;
BA_ "VNSigAllNodes" SG_ 2155479040 DispPerfMdCsStRq 1;
BA_ "SignalType" SG_ 2155479040 DispPerfMdCsStRq "ENM";
BA_ "SignalLongName" SG_ 2155479040 DispPerfMdCsStRq "Display Performance Mode Customization Setting Request";
BA_ "GenSigSendOnInit" SG_ 2155479040 SusCustStngReq 1;
BA_ "GenSigSendType" SG_ 2155479040 SusCustStngReq 10;
BA_ "VNSigAllNodes" SG_ 2155479040 SusCustStngReq 1;
BA_ "SignalType" SG_ 2155479040 SusCustStngReq "ENM";
BA_ "SignalLongName" SG_ 2155479040 SusCustStngReq "Suspension Customization Setting Request";
BA_ "GenSigSendOnInit" SG_ 2155479040 StrCustStngReq 1;
BA_ "GenSigSendType" SG_ 2155479040 StrCustStngReq 10;
BA_ "VNSigAllNodes" SG_ 2155479040 StrCustStngReq 1;
BA_ "SignalType" SG_ 2155479040 StrCustStngReq "ENM";
BA_ "SignalLongName" SG_ 2155479040 StrCustStngReq "Steering Customization Setting Request";
BA_ "GenSigSendOnInit" SG_ 2155479040 RstrCustFctrDef 1;
BA_ "GenSigSendType" SG_ 2155479040 RstrCustFctrDef 10;
BA_ "VNSigAllNodes" SG_ 2155479040 RstrCustFctrDef 1;
BA_ "SignalType" SG_ 2155479040 RstrCustFctrDef "ENM";
BA_ "SignalLongName" SG_ 2155479040 RstrCustFctrDef "Restore Customization Factory Defaults";
BA_ "GenSigSendOnInit" SG_ 2155479040 DrvlnCustStngReq 1;
BA_ "GenSigSendType" SG_ 2155479040 DrvlnCustStngReq 10;
BA_ "VNSigAllNodes" SG_ 2155479040 DrvlnCustStngReq 1;
BA_ "SignalType" SG_ 2155479040 DrvlnCustStngReq "ENM";
BA_ "SignalLongName" SG_ 2155479040 DrvlnCustStngReq "Driveline Customization Setting Request";
BA_ "GenSigSendType" SG_ 2151383040 TreInfMonSysRstReq 10;
BA_ "VNSigAllNodes" SG_ 2151383040 TreInfMonSysRstReq 1;
BA_ "SignalType" SG_ 2151383040 TreInfMonSysRstReq "BLN";
BA_ "SignalLongName" SG_ 2151383040 TreInfMonSysRstReq "Tire Inflation Monitoring System Reset Requested";
BA_ "GenSigSendOnInit" SG_ 2155421696 ServKylsStSysIO 2;
BA_ "GenSigSendType" SG_ 2155421696 ServKylsStSysIO 10;
BA_ "VNSigAllNodes" SG_ 2155421696 ServKylsStSysIO 1;
BA_ "SignalType" SG_ 2155421696 ServKylsStSysIO "BLN";
BA_ "SignalLongName" SG_ 2155421696 ServKylsStSysIO "Service Keyless Start System Indication On";
BA_ "GenSigSendOnInit" SG_ 2155421696 PsvEntAprchDrctn 2;
BA_ "GenSigSendType" SG_ 2155421696 PsvEntAprchDrctn 10;
BA_ "VNSigAllNodes" SG_ 2155421696 PsvEntAprchDrctn 1;
BA_ "SignalType" SG_ 2155421696 PsvEntAprchDrctn "ENM";
BA_ "SignalLongName" SG_ 2155421696 PsvEntAprchDrctn "Passive Entry Approach Direction";
BA_ "GenSigSendOnInit" SG_ 2155421696 PsvEntApprchDtcd 2;
BA_ "GenSigSendType" SG_ 2155421696 PsvEntApprchDtcd 10;
BA_ "VNSigAllNodes" SG_ 2155421696 PsvEntApprchDtcd 1;
BA_ "SignalType" SG_ 2155421696 PsvEntApprchDtcd "BLN";
BA_ "SignalLongName" SG_ 2155421696 PsvEntApprchDtcd "Passive Entry Approach Detected";
BA_ "GenSigSendOnInit" SG_ 2155421696 PsvEntApprchCnfgReq 2;
BA_ "GenSigSendType" SG_ 2155421696 PsvEntApprchCnfgReq 10;
BA_ "VNSigAllNodes" SG_ 2155421696 PsvEntApprchCnfgReq 1;
BA_ "SignalType" SG_ 2155421696 PsvEntApprchCnfgReq "ENM";
BA_ "SignalLongName" SG_ 2155421696 PsvEntApprchCnfgReq "Passive Entry Approach Configuration Request";
BA_ "GenSigSendOnInit" SG_ 2155421696 PsvEntChlng 2;
BA_ "GenSigSendType" SG_ 2155421696 PsvEntChlng 12;
BA_ "GenSigDeltaValue" SG_ 2155421696 PsvEntChlng 1;
BA_ "VNSigAllNodes" SG_ 2155421696 PsvEntChlng 1;
BA_ "SignalType" SG_ 2155421696 PsvEntChlng "UNM";
BA_ "SignalLongName" SG_ 2155421696 PsvEntChlng "Passive Entry Challenge";
BA_ "GenSigSendOnInit" SG_ 2151972864 VehFuelRngCalcV 1;
BA_ "GenSigSendType" SG_ 2151972864 VehFuelRngCalcV 10;
BA_ "VNSigAllNodes" SG_ 2151972864 VehFuelRngCalcV 1;
BA_ "SignalType" SG_ 2151972864 VehFuelRngCalcV "ENM";
BA_ "SignalLongName" SG_ 2151972864 VehFuelRngCalcV "Vehicle Fuel Range Calculated Validity";
BA_ "GenSigSendOnInit" SG_ 2151972864 VehFuelRngCalc 1;
BA_ "GenSigSendType" SG_ 2151972864 VehFuelRngCalc 12;
BA_ "GenSigDeltaValue" SG_ 2151972864 VehFuelRngCalc 1;
BA_ "VNSigAllNodes" SG_ 2151972864 VehFuelRngCalc 1;
BA_ "SignalType" SG_ 2151972864 VehFuelRngCalc "UNM";
BA_ "SignalLongName" SG_ 2151972864 VehFuelRngCalc "Vehicle Fuel Range Calculated";
BA_ "GenSigSendOnInit" SG_ 2151972864 FuelLvlLwIO 2;
BA_ "GenSigSendType" SG_ 2151972864 FuelLvlLwIO 10;
BA_ "VNSigAllNodes" SG_ 2151972864 FuelLvlLwIO 1;
BA_ "SignalType" SG_ 2151972864 FuelLvlLwIO "BLN";
BA_ "SignalLongName" SG_ 2151972864 FuelLvlLwIO "Fuel Level Low Indication On";
BA_ "GenSigSendType" SG_ 2151972864 LnchCtrlWhlSlpReq 10;
BA_ "VNSigAllNodes" SG_ 2151972864 LnchCtrlWhlSlpReq 1;
BA_ "SignalType" SG_ 2151972864 LnchCtrlWhlSlpReq "ENM";
BA_ "SignalLongName" SG_ 2151972864 LnchCtrlWhlSlpReq "Launch Control Wheel Slip Request";
BA_ "GenSigSendType" SG_ 2151972864 LnchCtrlMdReq 10;
BA_ "VNSigAllNodes" SG_ 2151972864 LnchCtrlMdReq 1;
BA_ "SignalType" SG_ 2151972864 LnchCtrlMdReq "ENM";
BA_ "SignalLongName" SG_ 2151972864 LnchCtrlMdReq "Launch Control Mode Request";
BA_ "GenSigSendType" SG_ 2151972864 LnchCtrlEngRPMReq 10;
BA_ "VNSigAllNodes" SG_ 2151972864 LnchCtrlEngRPMReq 1;
BA_ "SignalType" SG_ 2151972864 LnchCtrlEngRPMReq "ENM";
BA_ "SignalLongName" SG_ 2151972864 LnchCtrlEngRPMReq "Launch Control Engine RPM Request";
BA_ "GenSigSendType" SG_ 2156789760 FrPedDetCsStReq 10;
BA_ "VNSigAllNodes" SG_ 2156789760 FrPedDetCsStReq 1;
BA_ "SignalType" SG_ 2156789760 FrPedDetCsStReq "ENM";
BA_ "SignalLongName" SG_ 2156789760 FrPedDetCsStReq "Front Pedestrian Detection Customization Setting Request";
BA_ "GenSigSendType" SG_ 2156789760 SurdVwLightgCsSetReq 10;
BA_ "VNSigAllNodes" SG_ 2156789760 SurdVwLightgCsSetReq 1;
BA_ "SignalType" SG_ 2156789760 SurdVwLightgCsSetReq "ENM";
BA_ "SignalLongName" SG_ 2156789760 SurdVwLightgCsSetReq "Surround View Lighting Customization Setting Request";
BA_ "GenSigSendType" SG_ 2156789760 SmrtHgBmAstCstSetReq 10;
BA_ "VNSigAllNodes" SG_ 2156789760 SmrtHgBmAstCstSetReq 1;
BA_ "SignalType" SG_ 2156789760 SmrtHgBmAstCstSetReq "ENM";
BA_ "SignalLongName" SG_ 2156789760 SmrtHgBmAstCstSetReq "Smart High Beam Assist Customization Setting Request";
BA_ "GenSigSendOnInit" SG_ 2156789760 CldrYr 1;
BA_ "GenSigSendType" SG_ 2156789760 CldrYr 12;
BA_ "GenSigDeltaValue" SG_ 2156789760 CldrYr 1;
BA_ "VNSigAllNodes" SG_ 2156789760 CldrYr 1;
BA_ "SignalType" SG_ 2156789760 CldrYr "UNM";
BA_ "SignalLongName" SG_ 2156789760 CldrYr "Calendar Year";
BA_ "GenSigSendOnInit" SG_ 2156789760 CldrMth 1;
BA_ "GenSigSendType" SG_ 2156789760 CldrMth 10;
BA_ "VNSigAllNodes" SG_ 2156789760 CldrMth 1;
BA_ "SignalType" SG_ 2156789760 CldrMth "ENM";
BA_ "SignalLongName" SG_ 2156789760 CldrMth "Calendar Month";
BA_ "GenSigSendOnInit" SG_ 2156789760 CldrDay 1;
BA_ "GenSigSendType" SG_ 2156789760 CldrDay 12;
BA_ "GenSigDeltaValue" SG_ 2156789760 CldrDay 1;
BA_ "VNSigAllNodes" SG_ 2156789760 CldrDay 1;
BA_ "SignalType" SG_ 2156789760 CldrDay "UNM";
BA_ "SignalLongName" SG_ 2156789760 CldrDay "Calendar Day";
BA_ "GenSigSendOnInit" SG_ 2156789760 TOD_SecofMin 1;
BA_ "GenSigSendType" SG_ 2156789760 TOD_SecofMin 12;
BA_ "GenSigDeltaValue" SG_ 2156789760 TOD_SecofMin 1;
BA_ "VNSigAllNodes" SG_ 2156789760 TOD_SecofMin 1;
BA_ "SignalType" SG_ 2156789760 TOD_SecofMin "UNM";
BA_ "PacketOrder" SG_ 2156789760 TOD_SecofMin 3;
BA_ "SignalLongName" SG_ 2156789760 TOD_SecofMin "Time of Day : Seconds of Minute";
BA_ "GenSigSendOnInit" SG_ 2156789760 TOD_MinofHr 1;
BA_ "GenSigSendType" SG_ 2156789760 TOD_MinofHr 12;
BA_ "GenSigDeltaValue" SG_ 2156789760 TOD_MinofHr 1;
BA_ "VNSigAllNodes" SG_ 2156789760 TOD_MinofHr 1;
BA_ "SignalType" SG_ 2156789760 TOD_MinofHr "UNM";
BA_ "PacketOrder" SG_ 2156789760 TOD_MinofHr 2;
BA_ "SignalLongName" SG_ 2156789760 TOD_MinofHr "Time of Day : Minute of Hour";
BA_ "GenSigSendOnInit" SG_ 2156789760 TOD_HrofDay 1;
BA_ "GenSigSendType" SG_ 2156789760 TOD_HrofDay 12;
BA_ "GenSigDeltaValue" SG_ 2156789760 TOD_HrofDay 1;
BA_ "VNSigAllNodes" SG_ 2156789760 TOD_HrofDay 1;
BA_ "SignalType" SG_ 2156789760 TOD_HrofDay "UNM";
BA_ "PacketOrder" SG_ 2156789760 TOD_HrofDay 1;
BA_ "SignalLongName" SG_ 2156789760 TOD_HrofDay "Time of Day : Hour of Day";
BA_ "GenSigSendOnInit" SG_ 2156789760 TimeDispFormat 1;
BA_ "GenSigSendType" SG_ 2156789760 TimeDispFormat 10;
BA_ "VNSigAllNodes" SG_ 2156789760 TimeDispFormat 1;
BA_ "SignalType" SG_ 2156789760 TimeDispFormat "ENM";
BA_ "SignalLongName" SG_ 2156789760 TimeDispFormat "Time Display Format";
BA_ "GenSigSendType" SG_ 2155298816 EngAirFltMonDrvrReq 10;
BA_ "VNSigAllNodes" SG_ 2155298816 EngAirFltMonDrvrReq 1;
BA_ "SignalType" SG_ 2155298816 EngAirFltMonDrvrReq "ENM";
BA_ "SignalLongName" SG_ 2155298816 EngAirFltMonDrvrReq "Engine Air Filter Monitor Driver Request";
BA_ "GenSigSendType" SG_ 2155298816 TrPrsMntrTrLdRstRqstd 10;
BA_ "VNSigAllNodes" SG_ 2155298816 TrPrsMntrTrLdRstRqstd 1;
BA_ "SignalType" SG_ 2155298816 TrPrsMntrTrLdRstRqstd "ENM";
BA_ "SignalLongName" SG_ 2155298816 TrPrsMntrTrLdRstRqstd "Tire Pressure Monitoring Tire Loading Reset Requested";
BA_ "GenSigSendOnInit" SG_ 2155298816 TrPrsSnsProgEvntRqd 2;
BA_ "GenSigSendType" SG_ 2155298816 TrPrsSnsProgEvntRqd 10;
BA_ "VNSigAllNodes" SG_ 2155298816 TrPrsSnsProgEvntRqd 1;
BA_ "SignalType" SG_ 2155298816 TrPrsSnsProgEvntRqd "BLN";
BA_ "SignalLongName" SG_ 2155298816 TrPrsSnsProgEvntRqd "Tire Pressure Sensor Programming Event Requested";
BA_ "GenSigSendType" SG_ 2158878720 ODDLC_SubIdReqM 12;
BA_ "GenSigDeltaValue" SG_ 2158878720 ODDLC_SubIdReqM 1;
BA_ "VNSigAllNodes" SG_ 2158878720 ODDLC_SubIdReqM 1;
BA_ "SignalType" SG_ 2158878720 ODDLC_SubIdReqM "UNM";
BA_ "PacketOrder" SG_ 2158878720 ODDLC_SubIdReqM 10;
BA_ "SignalLongName" SG_ 2158878720 ODDLC_SubIdReqM "Open Display Interface Dynamic Data List Request CenterStack : Sub Id Request Mask";
BA_ "GenSigSendType" SG_ 2158878720 ODDLC_WrpArnd 10;
BA_ "VNSigAllNodes" SG_ 2158878720 ODDLC_WrpArnd 1;
BA_ "SignalType" SG_ 2158878720 ODDLC_WrpArnd "BLN";
BA_ "PacketOrder" SG_ 2158878720 ODDLC_WrpArnd 9;
BA_ "SignalLongName" SG_ 2158878720 ODDLC_WrpArnd "Open Display Interface Dynamic Data List Request CenterStack : Wrap Around";
BA_ "GenSigSendType" SG_ 2158878720 ODDLC_ReqType 10;
BA_ "VNSigAllNodes" SG_ 2158878720 ODDLC_ReqType 1;
BA_ "SignalType" SG_ 2158878720 ODDLC_ReqType "ENM";
BA_ "PacketOrder" SG_ 2158878720 ODDLC_ReqType 7;
BA_ "SignalLongName" SG_ 2158878720 ODDLC_ReqType "Open Display Interface Dynamic Data List Request CenterStack : Request Type";
BA_ "GenSigSendType" SG_ 2158878720 ODDLC_ReqDir 10;
BA_ "VNSigAllNodes" SG_ 2158878720 ODDLC_ReqDir 1;
BA_ "SignalType" SG_ 2158878720 ODDLC_ReqDir "BLN";
BA_ "PacketOrder" SG_ 2158878720 ODDLC_ReqDir 5;
BA_ "SignalLongName" SG_ 2158878720 ODDLC_ReqDir "Open Display Interface Dynamic Data List Request CenterStack : Req Direction";
BA_ "GenSigSendType" SG_ 2158878720 ODDLC_NmEntries 12;
BA_ "GenSigDeltaValue" SG_ 2158878720 ODDLC_NmEntries 1;
BA_ "VNSigAllNodes" SG_ 2158878720 ODDLC_NmEntries 1;
BA_ "SignalType" SG_ 2158878720 ODDLC_NmEntries "UNM";
BA_ "PacketOrder" SG_ 2158878720 ODDLC_NmEntries 4;
BA_ "SignalLongName" SG_ 2158878720 ODDLC_NmEntries "Open Display Interface Dynamic Data List Request CenterStack : Num Entries";
BA_ "GenSigSendType" SG_ 2158878720 ODDLC_Idx 12;
BA_ "GenSigDeltaValue" SG_ 2158878720 ODDLC_Idx 1;
BA_ "VNSigAllNodes" SG_ 2158878720 ODDLC_Idx 1;
BA_ "SignalType" SG_ 2158878720 ODDLC_Idx "UNM";
BA_ "PacketOrder" SG_ 2158878720 ODDLC_Idx 6;
BA_ "SignalLongName" SG_ 2158878720 ODDLC_Idx "Open Display Interface Dynamic Data List Request CenterStack : Index";
BA_ "GenSigSendType" SG_ 2158878720 ODDLC_FUCID 12;
BA_ "GenSigDeltaValue" SG_ 2158878720 ODDLC_FUCID 1;
BA_ "VNSigAllNodes" SG_ 2158878720 ODDLC_FUCID 1;
BA_ "SignalType" SG_ 2158878720 ODDLC_FUCID "UNM";
BA_ "PacketOrder" SG_ 2158878720 ODDLC_FUCID 1;
BA_ "SignalLongName" SG_ 2158878720 ODDLC_FUCID "Open Display Interface Dynamic Data List Request CenterStack : Functional Unit Class ID";
BA_ "GenSigSendType" SG_ 2158878720 ODDLC_DspMID 10;
BA_ "VNSigAllNodes" SG_ 2158878720 ODDLC_DspMID 1;
BA_ "SignalType" SG_ 2158878720 ODDLC_DspMID "ENM";
BA_ "PacketOrder" SG_ 2158878720 ODDLC_DspMID 3;
BA_ "SignalLongName" SG_ 2158878720 ODDLC_DspMID "Open Display Interface Dynamic Data List Request CenterStack : Display Mask Id";
BA_ "GenSigSendType" SG_ 2158878720 ODDLC_DataId 12;
BA_ "GenSigDeltaValue" SG_ 2158878720 ODDLC_DataId 1;
BA_ "VNSigAllNodes" SG_ 2158878720 ODDLC_DataId 1;
BA_ "SignalType" SG_ 2158878720 ODDLC_DataId "UNM";
BA_ "PacketOrder" SG_ 2158878720 ODDLC_DataId 2;
BA_ "SignalLongName" SG_ 2158878720 ODDLC_DataId "Open Display Interface Dynamic Data List Request CenterStack : Data Id";
BA_ "GenSigSendType" SG_ 2158878720 ODDLC_BckgndFlag 10;
BA_ "VNSigAllNodes" SG_ 2158878720 ODDLC_BckgndFlag 1;
BA_ "SignalType" SG_ 2158878720 ODDLC_BckgndFlag "ENM";
BA_ "PacketOrder" SG_ 2158878720 ODDLC_BckgndFlag 8;
BA_ "SignalLongName" SG_ 2158878720 ODDLC_BckgndFlag "Open Display Interface Dynamic Data List Request CenterStack : Background Flag";
BA_ "VNSigRemoteDiagnostics" SG_ 2153938944 RmtRflshMdReqtd 1;
BA_ "GenSigSendType" SG_ 2153938944 RmtRflshMdReqtd 10;
BA_ "SignalType" SG_ 2153938944 RmtRflshMdReqtd "BLN";
BA_ "SignalLongName" SG_ 2153938944 RmtRflshMdReqtd "Remote Reflash Mode Requested";
BA_ "GenSigSendType" SG_ 2150662144 EnvIdRsp3 12;
BA_ "GenSigDeltaValue" SG_ 2150662144 EnvIdRsp3 1;
BA_ "VNSigAllNodes" SG_ 2150662144 EnvIdRsp3 1;
BA_ "SignalType" SG_ 2150662144 EnvIdRsp3 "UNM";
BA_ "SignalLongName" SG_ 2150662144 EnvIdRsp3 "Environment Identification Response 3";
BA_ "GenSigSendType" SG_ 2150662144 EnvIdRspSt3 10;
BA_ "VNSigAllNodes" SG_ 2150662144 EnvIdRspSt3 1;
BA_ "SignalType" SG_ 2150662144 EnvIdRspSt3 "ENM";
BA_ "SignalLongName" SG_ 2150662144 EnvIdRspSt3 "Environment Identification Response Status 3";
BA_ "GenSigSendType" SG_ 2150653952 EnvIdRspSt2 10;
BA_ "VNSigAllNodes" SG_ 2150653952 EnvIdRspSt2 1;
BA_ "SignalType" SG_ 2150653952 EnvIdRspSt2 "ENM";
BA_ "SignalLongName" SG_ 2150653952 EnvIdRspSt2 "Environment Identification Response Status 2";
BA_ "GenSigSendType" SG_ 2150653952 EnvIdRsp2 12;
BA_ "GenSigDeltaValue" SG_ 2150653952 EnvIdRsp2 1;
BA_ "VNSigAllNodes" SG_ 2150653952 EnvIdRsp2 1;
BA_ "SignalType" SG_ 2150653952 EnvIdRsp2 "UNM";
BA_ "SignalLongName" SG_ 2150653952 EnvIdRsp2 "Environment Identification Response 2";
BA_ "GenSigSendType" SG_ 2153922560 ClmtCtrlHtrEngRunRq 10;
BA_ "VNSigAllNodes" SG_ 2153922560 ClmtCtrlHtrEngRunRq 1;
BA_ "SignalType" SG_ 2153922560 ClmtCtrlHtrEngRunRq "ENM";
BA_ "SignalLongName" SG_ 2153922560 ClmtCtrlHtrEngRunRq "Climate Control Heater Engine Run Request";
BA_ "GenSigSendOnInit" SG_ 2153922560 ClimCtrlVoltBstModReq 1;
BA_ "GenSigSendType" SG_ 2153922560 ClimCtrlVoltBstModReq 10;
BA_ "VNSigAllNodes" SG_ 2153922560 ClimCtrlVoltBstModReq 1;
BA_ "SignalType" SG_ 2153922560 ClimCtrlVoltBstModReq "BLN";
BA_ "SignalLongName" SG_ 2153922560 ClimCtrlVoltBstModReq "Climate Control Voltage Boost Mode Requested";
BA_ "GenSigSendType" SG_ 2153922560 HtrVlvRqstdPstn 10;
BA_ "VNSigAllNodes" SG_ 2153922560 HtrVlvRqstdPstn 1;
BA_ "SignalType" SG_ 2153922560 HtrVlvRqstdPstn "ENM";
BA_ "SignalLongName" SG_ 2153922560 HtrVlvRqstdPstn "Heater Valve Requested Position";
BA_ "GenSigSendType" SG_ 2153922560 ClntHtrElecPwrRatV 10;
BA_ "VNSigAllNodes" SG_ 2153922560 ClntHtrElecPwrRatV 1;
BA_ "SignalType" SG_ 2153922560 ClntHtrElecPwrRatV "ENM";
BA_ "SignalLongName" SG_ 2153922560 ClntHtrElecPwrRatV "Coolant Heater Electrical Power Rationalized Validity";
BA_ "GenSigSendType" SG_ 2153922560 ClntHtrElecPwrRat 12;
BA_ "GenSigDeltaValue" SG_ 2153922560 ClntHtrElecPwrRat 1;
BA_ "VNSigAllNodes" SG_ 2153922560 ClntHtrElecPwrRat 1;
BA_ "SignalType" SG_ 2153922560 ClntHtrElecPwrRat "UNM";
BA_ "SignalLongName" SG_ 2153922560 ClntHtrElecPwrRat "Coolant Heater Electrical Power Rationalized";
BA_ "GenSigSendOnInit" SG_ 2153922560 ClmCtrHiVltPwrRqtd 1;
BA_ "GenSigSendType" SG_ 2153922560 ClmCtrHiVltPwrRqtd 12;
BA_ "GenSigDeltaValue" SG_ 2153922560 ClmCtrHiVltPwrRqtd 1;
BA_ "VNSigAllNodes" SG_ 2153922560 ClmCtrHiVltPwrRqtd 1;
BA_ "SignalType" SG_ 2153922560 ClmCtrHiVltPwrRqtd "UNM";
BA_ "SignalLongName" SG_ 2153922560 ClmCtrHiVltPwrRqtd "Climate Control High Voltage Power Requested";
BA_ "GenSigSendType" SG_ 2153807872 PsvStrtStrngClmnLckTT 10;
BA_ "VNSigAllNodes" SG_ 2153807872 PsvStrtStrngClmnLckTT 1;
BA_ "SignalType" SG_ 2153807872 PsvStrtStrngClmnLckTT "ENM";
BA_ "SignalLongName" SG_ 2153807872 PsvStrtStrngClmnLckTT "Passive Start Steering Column Lock Telltale";
BA_ "GenSigSendType" SG_ 2153807872 ClmSysAuxFlrIndOn 10;
BA_ "VNSigAllNodes" SG_ 2153807872 ClmSysAuxFlrIndOn 1;
BA_ "SignalType" SG_ 2153807872 ClmSysAuxFlrIndOn "BLN";
BA_ "SignalLongName" SG_ 2153807872 ClmSysAuxFlrIndOn "Column System Auxiliary Failure Indication On";
BA_ "GenSigSendType" SG_ 2153807872 PsDoorOpenSwActV 10;
BA_ "VNSigAllNodes" SG_ 2153807872 PsDoorOpenSwActV 1;
BA_ "SignalType" SG_ 2153807872 PsDoorOpenSwActV "ENM";
BA_ "SignalLongName" SG_ 2153807872 PsDoorOpenSwActV "Passenger Door Open Switch Active Validity";
BA_ "GenSigSendOnInit" SG_ 2153807872 PsDoorOpenSwAct 1;
BA_ "GenSigSendType" SG_ 2153807872 PsDoorOpenSwAct 10;
BA_ "VNSigAllNodes" SG_ 2153807872 PsDoorOpenSwAct 1;
BA_ "SignalType" SG_ 2153807872 PsDoorOpenSwAct "BLN";
BA_ "SignalLongName" SG_ 2153807872 PsDoorOpenSwAct "Passenger Door Open Switch Active";
BA_ "GenSigSendType" SG_ 2153807872 DrDoorOpenSwActV 10;
BA_ "VNSigAllNodes" SG_ 2153807872 DrDoorOpenSwActV 1;
BA_ "SignalType" SG_ 2153807872 DrDoorOpenSwActV "ENM";
BA_ "SignalLongName" SG_ 2153807872 DrDoorOpenSwActV "Driver Door Open Switch Active Validity";
BA_ "GenSigSendOnInit" SG_ 2153807872 DrDoorOpenSwAct 1;
BA_ "GenSigSendType" SG_ 2153807872 DrDoorOpenSwAct 10;
BA_ "VNSigAllNodes" SG_ 2153807872 DrDoorOpenSwAct 1;
BA_ "SignalType" SG_ 2153807872 DrDoorOpenSwAct "BLN";
BA_ "SignalLongName" SG_ 2153807872 DrDoorOpenSwAct "Driver Door Open Switch Active";
BA_ "GenSigSendOnInit" SG_ 2151399424 VhlFlRngLwIO 2;
BA_ "GenSigSendType" SG_ 2151399424 VhlFlRngLwIO 10;
BA_ "VNSigAllNodes" SG_ 2151399424 VhlFlRngLwIO 1;
BA_ "SignalType" SG_ 2151399424 VhlFlRngLwIO "BLN";
BA_ "SignalLongName" SG_ 2151399424 VhlFlRngLwIO "Vehicle Fuel Range Low Indication On";
BA_ "GenSigSendOnInit" SG_ 2151399424 WshFldLw 1;
BA_ "GenSigSendType" SG_ 2151399424 WshFldLw 10;
BA_ "VNSigAllNodes" SG_ 2151399424 WshFldLw 1;
BA_ "SignalType" SG_ 2151399424 WshFldLw "BLN";
BA_ "SignalLongName" SG_ 2151399424 WshFldLw "Washer Fluid Low";
BA_ "GenSigSendType" SG_ 2151940096 EstIntRfSrfcTmpV 10;
BA_ "VNSigAllNodes" SG_ 2151940096 EstIntRfSrfcTmpV 1;
BA_ "SignalType" SG_ 2151940096 EstIntRfSrfcTmpV "ENM";
BA_ "SignalLongName" SG_ 2151940096 EstIntRfSrfcTmpV "Estimated Interior Roof Surface Temperature Validity";
BA_ "GenSigSendType" SG_ 2151940096 EstIntRfSrfcTmp 12;
BA_ "GenSigDeltaValue" SG_ 2151940096 EstIntRfSrfcTmp 1;
BA_ "VNSigAllNodes" SG_ 2151940096 EstIntRfSrfcTmp 1;
BA_ "SignalType" SG_ 2151940096 EstIntRfSrfcTmp "UNM";
BA_ "SignalLongName" SG_ 2151940096 EstIntRfSrfcTmp "Estimated Interior Roof Surface Temperature";
BA_ "GenSigSendType" SG_ 2151940096 EstBulkIntAirTmpV 10;
BA_ "VNSigAllNodes" SG_ 2151940096 EstBulkIntAirTmpV 1;
BA_ "SignalType" SG_ 2151940096 EstBulkIntAirTmpV "ENM";
BA_ "SignalLongName" SG_ 2151940096 EstBulkIntAirTmpV "Estimated Bulk Interior Air Temperature Validity";
BA_ "GenSigSendType" SG_ 2151940096 EstBulkIntAirTmp 12;
BA_ "GenSigDeltaValue" SG_ 2151940096 EstBulkIntAirTmp 1;
BA_ "VNSigAllNodes" SG_ 2151940096 EstBulkIntAirTmp 1;
BA_ "SignalType" SG_ 2151940096 EstBulkIntAirTmp "UNM";
BA_ "SignalLongName" SG_ 2151940096 EstBulkIntAirTmp "Estimated Bulk Interior Air Temperature";
BA_ "GenSigSendType" SG_ 2151940096 EstIntHorzDshSrfTmpM 10;
BA_ "VNSigAllNodes" SG_ 2151940096 EstIntHorzDshSrfTmpM 1;
BA_ "SignalType" SG_ 2151940096 EstIntHorzDshSrfTmpM "ENM";
BA_ "SignalLongName" SG_ 2151940096 EstIntHorzDshSrfTmpM "Estimated Interior Horizontal Dash Surface Temperature Mask";
BA_ "GenSigSendType" SG_ 2151940096 EstIntHorzDshSrfTmp 12;
BA_ "GenSigDeltaValue" SG_ 2151940096 EstIntHorzDshSrfTmp 1;
BA_ "VNSigAllNodes" SG_ 2151940096 EstIntHorzDshSrfTmp 1;
BA_ "SignalType" SG_ 2151940096 EstIntHorzDshSrfTmp "UNM";
BA_ "SignalLongName" SG_ 2151940096 EstIntHorzDshSrfTmp "Estimated Interior Horizontal Dash Surface Temperature";
BA_ "VNSigIntermediate" SG_ 2151940096 A2ERRAlrmTime 1;
BA_ "GenSigSendType" SG_ 2151940096 A2ERRAlrmTime 12;
BA_ "GenSigDeltaValue" SG_ 2151940096 A2ERRAlrmTime 1;
BA_ "VNSigAllNodes" SG_ 2151940096 A2ERRAlrmTime 1;
BA_ "SignalType" SG_ 2151940096 A2ERRAlrmTime "UNM";
BA_ "PacketOrder" SG_ 2151940096 A2ERRAlrmTime 2;
BA_ "SignalLongName" SG_ 2151940096 A2ERRAlrmTime "Alarm 2 Extended Range Request : Alarm Time";
BA_ "VNSigIntermediate" SG_ 2151940096 A2ERRAlrmReq 1;
BA_ "GenSigSendType" SG_ 2151940096 A2ERRAlrmReq 10;
BA_ "VNSigAllNodes" SG_ 2151940096 A2ERRAlrmReq 1;
BA_ "SignalType" SG_ 2151940096 A2ERRAlrmReq "ENM";
BA_ "PacketOrder" SG_ 2151940096 A2ERRAlrmReq 1;
BA_ "SignalLongName" SG_ 2151940096 A2ERRAlrmReq "Alarm 2 Extended Range Request : Alarm Request";
BA_ "GenSigSendOnInit" SG_ 2151923712 HLOCCstCurrSetVal 2;
BA_ "GenSigSendType" SG_ 2151923712 HLOCCstCurrSetVal 10;
BA_ "VNSigAllNodes" SG_ 2151923712 HLOCCstCurrSetVal 1;
BA_ "SignalType" SG_ 2151923712 HLOCCstCurrSetVal "ENM";
BA_ "SignalLongName" SG_ 2151923712 HLOCCstCurrSetVal "Handfree Liftgate Open Close Customization Current Setting Value";
BA_ "GenSigSendOnInit" SG_ 2151923712 HLOCCstSetAvail 2;
BA_ "GenSigSendType" SG_ 2151923712 HLOCCstSetAvail 10;
BA_ "VNSigAllNodes" SG_ 2151923712 HLOCCstSetAvail 1;
BA_ "SignalType" SG_ 2151923712 HLOCCstSetAvail "BLN";
BA_ "SignalLongName" SG_ 2151923712 HLOCCstSetAvail "Handsfree Liftgate Open Close Customization Setting Available";
BA_ "GenSigSendOnInit" SG_ 2151923712 HLOCCA_Res4Avail 2;
BA_ "GenSigSendType" SG_ 2151923712 HLOCCA_Res4Avail 10;
BA_ "VNSigAllNodes" SG_ 2151923712 HLOCCA_Res4Avail 1;
BA_ "SignalType" SG_ 2151923712 HLOCCA_Res4Avail "BLN";
BA_ "PacketOrder" SG_ 2151923712 HLOCCA_Res4Avail 7;
BA_ "SignalLongName" SG_ 2151923712 HLOCCA_Res4Avail "Handsfree Liftgate Open Close Customization Available : Reserved 4 Available";
BA_ "GenSigSendOnInit" SG_ 2151923712 HLOCCA_Res3Avail 2;
BA_ "GenSigSendType" SG_ 2151923712 HLOCCA_Res3Avail 10;
BA_ "VNSigAllNodes" SG_ 2151923712 HLOCCA_Res3Avail 1;
BA_ "SignalType" SG_ 2151923712 HLOCCA_Res3Avail "BLN";
BA_ "PacketOrder" SG_ 2151923712 HLOCCA_Res3Avail 6;
BA_ "SignalLongName" SG_ 2151923712 HLOCCA_Res3Avail "Handsfree Liftgate Open Close Customization Available : Reserved 3 Available";
BA_ "GenSigSendOnInit" SG_ 2151923712 HLOCCA_Res2Avail 2;
BA_ "GenSigSendType" SG_ 2151923712 HLOCCA_Res2Avail 10;
BA_ "VNSigAllNodes" SG_ 2151923712 HLOCCA_Res2Avail 1;
BA_ "SignalType" SG_ 2151923712 HLOCCA_Res2Avail "BLN";
BA_ "PacketOrder" SG_ 2151923712 HLOCCA_Res2Avail 5;
BA_ "SignalLongName" SG_ 2151923712 HLOCCA_Res2Avail "Handsfree Liftgate Open Close Customization Available : Reserved 2 Available";
BA_ "GenSigSendOnInit" SG_ 2151923712 HLOCCA_Res1Avail 2;
BA_ "GenSigSendType" SG_ 2151923712 HLOCCA_Res1Avail 10;
BA_ "VNSigAllNodes" SG_ 2151923712 HLOCCA_Res1Avail 1;
BA_ "SignalType" SG_ 2151923712 HLOCCA_Res1Avail "BLN";
BA_ "PacketOrder" SG_ 2151923712 HLOCCA_Res1Avail 4;
BA_ "SignalLongName" SG_ 2151923712 HLOCCA_Res1Avail "Handsfree Liftgate Open Close Customization Available : Reserved 1 Available";
BA_ "GenSigSendOnInit" SG_ 2151923712 HLOCCA_OnOpnOnlyAvail 2;
BA_ "GenSigSendType" SG_ 2151923712 HLOCCA_OnOpnOnlyAvail 10;
BA_ "VNSigAllNodes" SG_ 2151923712 HLOCCA_OnOpnOnlyAvail 1;
BA_ "SignalType" SG_ 2151923712 HLOCCA_OnOpnOnlyAvail "BLN";
BA_ "PacketOrder" SG_ 2151923712 HLOCCA_OnOpnOnlyAvail 3;
BA_ "SignalLongName" SG_ 2151923712 HLOCCA_OnOpnOnlyAvail "Handsfree Liftgate Open Close Customization Available : On Open Only Available";
BA_ "GenSigSendOnInit" SG_ 2151923712 HLOCCA_OnAvail 2;
BA_ "GenSigSendType" SG_ 2151923712 HLOCCA_OnAvail 10;
BA_ "VNSigAllNodes" SG_ 2151923712 HLOCCA_OnAvail 1;
BA_ "SignalType" SG_ 2151923712 HLOCCA_OnAvail "BLN";
BA_ "PacketOrder" SG_ 2151923712 HLOCCA_OnAvail 2;
BA_ "SignalLongName" SG_ 2151923712 HLOCCA_OnAvail "Handsfree Liftgate Open Close Customization Available : On Available";
BA_ "GenSigSendOnInit" SG_ 2151923712 HLOCCA_OffAvail 2;
BA_ "GenSigSendType" SG_ 2151923712 HLOCCA_OffAvail 10;
BA_ "VNSigAllNodes" SG_ 2151923712 HLOCCA_OffAvail 1;
BA_ "SignalType" SG_ 2151923712 HLOCCA_OffAvail "BLN";
BA_ "PacketOrder" SG_ 2151923712 HLOCCA_OffAvail 1;
BA_ "SignalLongName" SG_ 2151923712 HLOCCA_OffAvail "Handsfree Liftgate Open Close Customization Available : Off Available";
BA_ "GenSigSendType" SG_ 2151923712 A1ERRAlrmTime 12;
BA_ "GenSigDeltaValue" SG_ 2151923712 A1ERRAlrmTime 1;
BA_ "VNSigAllNodes" SG_ 2151923712 A1ERRAlrmTime 1;
BA_ "SignalType" SG_ 2151923712 A1ERRAlrmTime "UNM";
BA_ "PacketOrder" SG_ 2151923712 A1ERRAlrmTime 2;
BA_ "SignalLongName" SG_ 2151923712 A1ERRAlrmTime "Alarm 1 Extended Range Request : Alarm Time";
BA_ "GenSigSendType" SG_ 2151923712 A1ERRAlrmReq 10;
BA_ "VNSigAllNodes" SG_ 2151923712 A1ERRAlrmReq 1;
BA_ "SignalType" SG_ 2151923712 A1ERRAlrmReq "ENM";
BA_ "PacketOrder" SG_ 2151923712 A1ERRAlrmReq 1;
BA_ "SignalLongName" SG_ 2151923712 A1ERRAlrmReq "Alarm 1 Extended Range Request : Alarm Request";
BA_ "GenSigSendType" SG_ 2150645760 EnvIdRspSt1 10;
BA_ "VNSigAllNodes" SG_ 2150645760 EnvIdRspSt1 1;
BA_ "SignalType" SG_ 2150645760 EnvIdRspSt1 "ENM";
BA_ "SignalLongName" SG_ 2150645760 EnvIdRspSt1 "Environment Identification Response Status 1";
BA_ "GenSigSendType" SG_ 2150645760 EnvIdRsp1 12;
BA_ "GenSigDeltaValue" SG_ 2150645760 EnvIdRsp1 1;
BA_ "VNSigAllNodes" SG_ 2150645760 EnvIdRsp1 1;
BA_ "SignalType" SG_ 2150645760 EnvIdRsp1 "UNM";
BA_ "SignalLongName" SG_ 2150645760 EnvIdRsp1 "Environment Identification Response 1";
BA_ "GenSigSendType" SG_ 2152464384 RtLnDepWrnSt 10;
BA_ "VNSigAllNodes" SG_ 2152464384 RtLnDepWrnSt 1;
BA_ "SignalType" SG_ 2152464384 RtLnDepWrnSt "ENM";
BA_ "SignalLongName" SG_ 2152464384 RtLnDepWrnSt "Right Lane Departure Warning Status";
BA_ "GenSigSendType" SG_ 2152464384 LftLnDepWrnSt 10;
BA_ "VNSigAllNodes" SG_ 2152464384 LftLnDepWrnSt 1;
BA_ "SignalType" SG_ 2152464384 LftLnDepWrnSt "ENM";
BA_ "SignalLongName" SG_ 2152464384 LftLnDepWrnSt "Left Lane Departure Warning Status";
BA_ "GenSigSendType" SG_ 2152464384 TnDrvLDWOffUnbIO 10;
BA_ "VNSigAllNodes" SG_ 2152464384 TnDrvLDWOffUnbIO 1;
BA_ "SignalType" SG_ 2152464384 TnDrvLDWOffUnbIO "BLN";
BA_ "SignalLongName" SG_ 2152464384 TnDrvLDWOffUnbIO "Teen Driver Lane Departure Warning Off Unavailable Indication On";
BA_ "GenSigSendType" SG_ 2152464384 HndsOffStrWhlDtIO 10;
BA_ "VNSigAllNodes" SG_ 2152464384 HndsOffStrWhlDtIO 1;
BA_ "SignalType" SG_ 2152464384 HndsOffStrWhlDtIO "BLN";
BA_ "SignalLongName" SG_ 2152464384 HndsOffStrWhlDtIO "Hands Off Steering Wheel Detection Indication On";
BA_ "GenSigSendType" SG_ 2152464384 LnKpAstDisbldIO 10;
BA_ "VNSigAllNodes" SG_ 2152464384 LnKpAstDisbldIO 1;
BA_ "SignalType" SG_ 2152464384 LnKpAstDisbldIO "BLN";
BA_ "SignalLongName" SG_ 2152464384 LnKpAstDisbldIO "Lane Keeping Assist Disabled Indication On";
BA_ "GenSigSendType" SG_ 2152464384 LaneDepWrnDisbldIO 10;
BA_ "VNSigAllNodes" SG_ 2152464384 LaneDepWrnDisbldIO 1;
BA_ "SignalType" SG_ 2152464384 LaneDepWrnDisbldIO "BLN";
BA_ "SignalLongName" SG_ 2152464384 LaneDepWrnDisbldIO "Lane Departure Warning Disabled Indication On";
BA_ "GenSigSendType" SG_ 2152464384 SrvcLnKpAstSysIO 10;
BA_ "VNSigAllNodes" SG_ 2152464384 SrvcLnKpAstSysIO 1;
BA_ "SignalType" SG_ 2152464384 SrvcLnKpAstSysIO "BLN";
BA_ "SignalLongName" SG_ 2152464384 SrvcLnKpAstSysIO "Service Lane Keeping Assist System Indication On";
BA_ "GenSigSendType" SG_ 2152464384 LKAIC_AdbWngLn 10;
BA_ "VNSigAllNodes" SG_ 2152464384 LKAIC_AdbWngLn 1;
BA_ "SignalType" SG_ 2152464384 LKAIC_AdbWngLn "ENM";
BA_ "PacketOrder" SG_ 2152464384 LKAIC_AdbWngLn 4;
BA_ "SignalLongName" SG_ 2152464384 LKAIC_AdbWngLn "Lane Keeping Assist Indication Control : Audible Warning Location";
BA_ "GenSigSendType" SG_ 2152464384 LKAIC_Ind2 10;
BA_ "VNSigAllNodes" SG_ 2152464384 LKAIC_Ind2 1;
BA_ "SignalType" SG_ 2152464384 LKAIC_Ind2 "BLN";
BA_ "PacketOrder" SG_ 2152464384 LKAIC_Ind2 3;
BA_ "SignalLongName" SG_ 2152464384 LKAIC_Ind2 "Lane Keeping Assist Indication Control : Indicator 2";
BA_ "GenSigSendType" SG_ 2152464384 LKAIC_Ind1 10;
BA_ "VNSigAllNodes" SG_ 2152464384 LKAIC_Ind1 1;
BA_ "SignalType" SG_ 2152464384 LKAIC_Ind1 "BLN";
BA_ "PacketOrder" SG_ 2152464384 LKAIC_Ind1 2;
BA_ "SignalLongName" SG_ 2152464384 LKAIC_Ind1 "Lane Keeping Assist Indication Control : Indicator 1";
BA_ "GenSigSendType" SG_ 2152464384 LKAIC_IndReq 10;
BA_ "VNSigAllNodes" SG_ 2152464384 LKAIC_IndReq 1;
BA_ "SignalType" SG_ 2152464384 LKAIC_IndReq "ENM";
BA_ "PacketOrder" SG_ 2152464384 LKAIC_IndReq 1;
BA_ "SignalLongName" SG_ 2152464384 LKAIC_IndReq "Lane Keeping Assist Indication Control : Indication Request";
BA_ "GenSigSendType" SG_ 2152464384 SrvcLaneDepWrnSysIO 10;
BA_ "VNSigAllNodes" SG_ 2152464384 SrvcLaneDepWrnSysIO 1;
BA_ "SignalType" SG_ 2152464384 SrvcLaneDepWrnSysIO "BLN";
BA_ "SignalLongName" SG_ 2152464384 SrvcLaneDepWrnSysIO "Service Lane Departure Warning System Indication On";
BA_ "GenSigSendOnInit" SG_ 2152464384 LDWIC_LnDepWAWLn 2;
BA_ "GenSigSendType" SG_ 2152464384 LDWIC_LnDepWAWLn 10;
BA_ "VNSigAllNodes" SG_ 2152464384 LDWIC_LnDepWAWLn 1;
BA_ "SignalType" SG_ 2152464384 LDWIC_LnDepWAWLn "ENM";
BA_ "PacketOrder" SG_ 2152464384 LDWIC_LnDepWAWLn 4;
BA_ "SignalLongName" SG_ 2152464384 LDWIC_LnDepWAWLn "Lane Departure Warning Indication Control : Lane Deparature Warning Audible Warning Location";
BA_ "GenSigSendOnInit" SG_ 2152464384 LDWIC_Ind2 2;
BA_ "GenSigSendType" SG_ 2152464384 LDWIC_Ind2 10;
BA_ "VNSigAllNodes" SG_ 2152464384 LDWIC_Ind2 1;
BA_ "SignalType" SG_ 2152464384 LDWIC_Ind2 "BLN";
BA_ "PacketOrder" SG_ 2152464384 LDWIC_Ind2 3;
BA_ "SignalLongName" SG_ 2152464384 LDWIC_Ind2 "Lane Departure Warning Indication Control : Indicator 2";
BA_ "GenSigSendOnInit" SG_ 2152464384 LDWIC_Ind1 2;
BA_ "GenSigSendType" SG_ 2152464384 LDWIC_Ind1 10;
BA_ "VNSigAllNodes" SG_ 2152464384 LDWIC_Ind1 1;
BA_ "SignalType" SG_ 2152464384 LDWIC_Ind1 "BLN";
BA_ "PacketOrder" SG_ 2152464384 LDWIC_Ind1 2;
BA_ "SignalLongName" SG_ 2152464384 LDWIC_Ind1 "Lane Departure Warning Indication Control : Indicator 1";
BA_ "GenSigSendOnInit" SG_ 2152464384 LDWIC_IndReq 2;
BA_ "GenSigSendType" SG_ 2152464384 LDWIC_IndReq 10;
BA_ "VNSigAllNodes" SG_ 2152464384 LDWIC_IndReq 1;
BA_ "SignalType" SG_ 2152464384 LDWIC_IndReq "ENM";
BA_ "PacketOrder" SG_ 2152464384 LDWIC_IndReq 1;
BA_ "SignalLongName" SG_ 2152464384 LDWIC_IndReq "Lane Departure Warning Indication Control : Indication Request";
BA_ "GenSigSendOnInit" SG_ 2154971136 PassHCSeatSw3Act 2;
BA_ "GenSigSendType" SG_ 2154971136 PassHCSeatSw3Act 10;
BA_ "VNSigAllNodes" SG_ 2154971136 PassHCSeatSw3Act 1;
BA_ "SignalType" SG_ 2154971136 PassHCSeatSw3Act "BLN";
BA_ "SignalLongName" SG_ 2154971136 PassHCSeatSw3Act "Passenger Heated/Cooled Seat Switch #3 Active";
BA_ "GenSigSendOnInit" SG_ 2154971136 PassHCSeatSw2Act 2;
BA_ "GenSigSendType" SG_ 2154971136 PassHCSeatSw2Act 10;
BA_ "VNSigAllNodes" SG_ 2154971136 PassHCSeatSw2Act 1;
BA_ "SignalType" SG_ 2154971136 PassHCSeatSw2Act "BLN";
BA_ "SignalLongName" SG_ 2154971136 PassHCSeatSw2Act "Passenger Heated/Cooled Seat Switch #2 Active";
BA_ "GenSigSendOnInit" SG_ 2154971136 PassHCSeatSw1Act 2;
BA_ "GenSigSendType" SG_ 2154971136 PassHCSeatSw1Act 10;
BA_ "VNSigAllNodes" SG_ 2154971136 PassHCSeatSw1Act 1;
BA_ "SignalType" SG_ 2154971136 PassHCSeatSw1Act "BLN";
BA_ "SignalLongName" SG_ 2154971136 PassHCSeatSw1Act "Passenger Heated/Cooled Seat Switch #1 Active";
BA_ "GenSigSendOnInit" SG_ 2154971136 DrvHCSeatSw3Act 2;
BA_ "GenSigSendType" SG_ 2154971136 DrvHCSeatSw3Act 10;
BA_ "VNSigAllNodes" SG_ 2154971136 DrvHCSeatSw3Act 1;
BA_ "SignalType" SG_ 2154971136 DrvHCSeatSw3Act "BLN";
BA_ "SignalLongName" SG_ 2154971136 DrvHCSeatSw3Act "Driver Heated/Cooled Seat Switch #3 Active";
BA_ "GenSigSendOnInit" SG_ 2154971136 DrvHCSeatSw2Act 2;
BA_ "GenSigSendType" SG_ 2154971136 DrvHCSeatSw2Act 10;
BA_ "VNSigAllNodes" SG_ 2154971136 DrvHCSeatSw2Act 1;
BA_ "SignalType" SG_ 2154971136 DrvHCSeatSw2Act "BLN";
BA_ "SignalLongName" SG_ 2154971136 DrvHCSeatSw2Act "Driver Heated/Cooled Seat Switch #2 Active";
BA_ "GenSigSendOnInit" SG_ 2154971136 DrvHCSeatSw1Act 2;
BA_ "GenSigSendType" SG_ 2154971136 DrvHCSeatSw1Act 10;
BA_ "VNSigAllNodes" SG_ 2154971136 DrvHCSeatSw1Act 1;
BA_ "SignalType" SG_ 2154971136 DrvHCSeatSw1Act "BLN";
BA_ "SignalLongName" SG_ 2154971136 DrvHCSeatSw1Act "Driver Heated/Cooled Seat Switch #1 Active";
BA_ "GenSigSendType" SG_ 2154676224 CmpsModSlfTstReq 10;
BA_ "VNSigAllNodes" SG_ 2154676224 CmpsModSlfTstReq 1;
BA_ "SignalType" SG_ 2154676224 CmpsModSlfTstReq "ENM";
BA_ "SignalLongName" SG_ 2154676224 CmpsModSlfTstReq "Compass Module Self Test Request";
BA_ "GenSigSendType" SG_ 2154676224 CmpsModManCalReq 10;
BA_ "VNSigAllNodes" SG_ 2154676224 CmpsModManCalReq 1;
BA_ "SignalType" SG_ 2154676224 CmpsModManCalReq "ENM";
BA_ "SignalLongName" SG_ 2154676224 CmpsModManCalReq "Compass Module Manual Calibration Request";
BA_ "GenSigSendType" SG_ 2154676224 CmpsDecZonSetReq 10;
BA_ "VNSigAllNodes" SG_ 2154676224 CmpsDecZonSetReq 1;
BA_ "SignalType" SG_ 2154676224 CmpsDecZonSetReq "ENM";
BA_ "SignalLongName" SG_ 2154676224 CmpsDecZonSetReq "Compass Declination Zone Set Request";
BA_ "GenSigSendType" SG_ 2154676224 CmpsDecZonCmndVal 10;
BA_ "VNSigAllNodes" SG_ 2154676224 CmpsDecZonCmndVal 1;
BA_ "SignalType" SG_ 2154676224 CmpsDecZonCmndVal "ENM";
BA_ "SignalLongName" SG_ 2154676224 CmpsDecZonCmndVal "Compass Declination Zone Commanded Value";
BA_ "GenSigSendType" SG_ 2154643456 AuxHtrAtv 10;
BA_ "VNSigAllNodes" SG_ 2154643456 AuxHtrAtv 1;
BA_ "SignalType" SG_ 2154643456 AuxHtrAtv "BLN";
BA_ "SignalLongName" SG_ 2154643456 AuxHtrAtv "Auxiliary Heater Active";
BA_ "GenSigSendOnInit" SG_ 2154643456 CCClntCrcFlwRtReq 2;
BA_ "GenSigSendType" SG_ 2154643456 CCClntCrcFlwRtReq 12;
BA_ "GenSigDeltaValue" SG_ 2154643456 CCClntCrcFlwRtReq 1;
BA_ "VNSigAllNodes" SG_ 2154643456 CCClntCrcFlwRtReq 1;
BA_ "SignalType" SG_ 2154643456 CCClntCrcFlwRtReq "UNM";
BA_ "SignalLongName" SG_ 2154643456 CCClntCrcFlwRtReq "Climate Control Coolant Circulation Flow Rate Request";
BA_ "GenSigSendType" SG_ 2154643456 HtrCoreInltClntTmpCalcV 10;
BA_ "VNSigAllNodes" SG_ 2154643456 HtrCoreInltClntTmpCalcV 1;
BA_ "SignalType" SG_ 2154643456 HtrCoreInltClntTmpCalcV "ENM";
BA_ "SignalLongName" SG_ 2154643456 HtrCoreInltClntTmpCalcV "Heater Core Inlet Coolant Temperature Calculated Validity";
BA_ "GenSigSendType" SG_ 2154643456 HtrCoreInltClntTmpCalc 12;
BA_ "GenSigDeltaValue" SG_ 2154643456 HtrCoreInltClntTmpCalc 1;
BA_ "VNSigAllNodes" SG_ 2154643456 HtrCoreInltClntTmpCalc 1;
BA_ "SignalType" SG_ 2154643456 HtrCoreInltClntTmpCalc "UNM";
BA_ "SignalLongName" SG_ 2154643456 HtrCoreInltClntTmpCalc "Heater Core Inlet Coolant Temperature Calculated";
BA_REL_ "GenSigSuprvResp" BU_SG_REL_ ECC_LS SG_ 2150080512 EngAstHtDfrdHtMdAct 1;
BA_REL_ "GenSigSuprvResp" BU_SG_REL_ ECC_LS SG_ 2150055936 ClmCntCmpPwrUsdClc 1;
BA_REL_ "GenSigSuprvResp" BU_SG_REL_ ECC_LS SG_ 2150039552 EvpCorOtltAirTmpCalcd 1;
BA_REL_ "GenSigSuprvResp" BU_SG_REL_ VIS2_LS SG_ 2155216896 DgtlMapPstdSpdLimAsrd 1;
BA_REL_ "GenSigSuprvResp" BU_SG_REL_ BCM_LS SG_ 2155216896 ISA2CCC_ScndCdChr 1;
BA_REL_ "GenSigSuprvResp" BU_SG_REL_ BCM_LS SG_ 2155216896 ISA2CCC_FrstCdChr 1;
BA_REL_ "GenSigSuprvResp" BU_SG_REL_ BCM_LS SG_ 2155216896 SpdLmtUnits 1;
BA_REL_ "GenSigSuprvResp" BU_SG_REL_ EOCM_F_LS SG_ 2155216896 RdSpdCatType 1;
BA_REL_ "GenSigSuprvResp" BU_SG_REL_ EOCM_F_LS SG_ 2155216896 FncRdClass 1;
BA_REL_ "GenSigSuprvResp" BU_SG_REL_ EOCM_F_LS SG_ 2155216896 BldUpArDet 1;
BA_REL_ "GenSigSuprvResp" BU_SG_REL_ EOCM_F_LS SG_ 2155216896 MpDataAvlbl 1;
BA_REL_ "GenSigSuprvResp" BU_SG_REL_ EOCM_F_LS SG_ 2150277120 PsngSysLong 1;
BA_REL_ "GenSigSuprvResp" BU_SG_REL_ EOCM_F_LS SG_ 2150277120 PsngSysLat 1;
BA_REL_ "GenSigSuprvResp" BU_SG_REL_ EOCM_F_LS SG_ 2150285312 PsngSysCalcSpd 1;
BA_REL_ "GenSigSuprvResp" BU_SG_REL_ EOCM_F_LS SG_ 2150285312 PsngSysHding 1;
BA_REL_ "GenSigSuprvResp" BU_SG_REL_ EOCM_F_LS SG_ 2150285312 PsngSysElvtn 1;
BA_REL_ "GenSigSuprvResp" BU_SG_REL_ BSM_LS SG_ 2150285312 PsngSysElvtn 1;
BA_REL_ "GenSigSuprvResp" BU_SG_REL_ EOCM_F_LS SG_ 2150285312 PsngSysDilPrcs 1;
BA_REL_ "GenSigSuprvResp" BU_SG_REL_ EOCM_F_LS SG_ 2151047168 HUDActv 1;
BA_REL_ "GenSigSuprvResp" BU_SG_REL_ BCM_LS SG_ 2151047168 HUDActv 1;
BA_REL_ "GenSigSuprvResp" BU_SG_REL_ BCM_LS SG_ 2149900288 EnhSrvVisAlRq 1;
BA_REL_ "GenSigSuprvResp" BU_SG_REL_ BCM_LS SG_ 2155479040 DrvStyPerfMdCsStReq 1;
BA_REL_ "GenSigSuprvResp" BU_SG_REL_ BCM_LS SG_ 2155479040 PsngStPerfMdCsStReq 1;
BA_REL_ "GenSigSuprvResp" BU_SG_REL_ BCM_LS SG_ 2155479040 DrvrStPerfMdCsStReq 1;
BA_REL_ "GenSigSuprvResp" BU_SG_REL_ BCM_LS SG_ 2155479040 ACCPerfMdCsStReq 1;
BA_REL_ "GenSigSuprvResp" BU_SG_REL_ BCM_LS SG_ 2155479040 PedFrndlyAlrtCsStReq 1;
BA_REL_ "GenSigSuprvResp" BU_SG_REL_ VIS2_LS SG_ 2155479040 RstrCustFctrDef 1;
BA_REL_ "GenSigSuprvResp" BU_SG_REL_ BSM_LS SG_ 2155479040 RstrCustFctrDef 1;
BA_REL_ "GenSigSuprvResp" BU_SG_REL_ BCM_LS SG_ 2155421696 PsvEntAprchDrctn 1;
BA_REL_ "GenSigSuprvResp" BU_SG_REL_ BCM_LS SG_ 2155421696 PsvEntApprchDtcd 1;
BA_REL_ "GenSigSuprvResp" BU_SG_REL_ BCM_LS SG_ 2155421696 PsvEntApprchCnfgReq 1;
BA_REL_ "GenSigSuprvResp" BU_SG_REL_ BCM_LS SG_ 2155421696 PsvEntChlng 1;
BA_REL_ "GenSigSuprvResp" BU_SG_REL_ BCM_LS SG_ 2155298816 TrPrsMntrTrLdRstRqstd 1;
BA_REL_ "GenSigSuprvResp" BU_SG_REL_ BCM_LS SG_ 2153938944 RmtRflshMdReqtd 1;
BA_REL_ "GenSigSuprvResp" BU_SG_REL_ BCM_LS SG_ 2153922560 ClmtCtrlHtrEngRunRq 1;
BA_REL_ "GenSigSuprvResp" BU_SG_REL_ BCM_LS SG_ 2153922560 ClimCtrlVoltBstModReq 1;
BA_REL_ "GenSigSuprvResp" BU_SG_REL_ BSM_LS SG_ 2153922560 HtrVlvRqstdPstn 1;
BA_REL_ "GenSigSuprvResp" BU_SG_REL_ BSM_LS SG_ 2153922560 ClntHtrElecPwrRat 1;
BA_REL_ "GenSigSuprvResp" BU_SG_REL_ BSM_LS SG_ 2153922560 ClmCtrHiVltPwrRqtd 1;
BA_REL_ "GenSigSuprvResp" BU_SG_REL_ BCM_LS SG_ 2153807872 PsDoorOpenSwAct 1;
BA_REL_ "GenSigVBitResp" BU_SG_REL_ BCM_LS SG_ 2153807872 PsDoorOpenSwAct 1;
BA_REL_ "GenSigSuprvResp" BU_SG_REL_ EOCM_F_LS SG_ 2153807872 DrDoorOpenSwAct 1;
BA_REL_ "GenSigSuprvResp" BU_SG_REL_ BCM_LS SG_ 2153807872 DrDoorOpenSwAct 1;
BA_REL_ "GenSigVBitResp" BU_SG_REL_ BCM_LS SG_ 2153807872 DrDoorOpenSwAct 1;
BA_REL_ "GenSigSuprvResp" BU_SG_REL_ BCM_LS SG_ 2151399424 WshFldLw 1;
BA_REL_ "GenSigSuprvRespSubValue" BU_SG_REL_ BCM_LS SG_ 2151399424 WshFldLw 1;
BA_REL_ "GenSigSuprvResp" BU_SG_REL_ BCM_LS SG_ 2151940096 EstIntHorzDshSrfTmp 1;
BA_REL_ "GenSigSuprvResp" BU_SG_REL_ BCM_LS SG_ 2152464384 SrvcLnKpAstSysIO 1;
BA_REL_ "GenSigSuprvResp" BU_SG_REL_ BCM_LS SG_ 2152464384 LKAIC_AdbWngLn 1;
BA_REL_ "GenSigSuprvResp" BU_SG_REL_ BCM_LS SG_ 2152464384 LKAIC_Ind2 1;
BA_REL_ "GenSigSuprvResp" BU_SG_REL_ BCM_LS SG_ 2152464384 LKAIC_Ind1 1;
BA_REL_ "GenSigSuprvResp" BU_SG_REL_ BCM_LS SG_ 2152464384 LKAIC_IndReq 1;
BA_REL_ "GenSigSuprvResp" BU_SG_REL_ BCM_LS SG_ 2152464384 SrvcLaneDepWrnSysIO 1;
BA_REL_ "GenSigSuprvResp" BU_SG_REL_ BCM_LS SG_ 2152464384 LDWIC_LnDepWAWLn 1;
BA_REL_ "GenSigSuprvResp" BU_SG_REL_ BCM_LS SG_ 2152464384 LDWIC_Ind2 1;
BA_REL_ "GenSigSuprvResp" BU_SG_REL_ BCM_LS SG_ 2152464384 LDWIC_Ind1 1;
BA_REL_ "GenSigSuprvResp" BU_SG_REL_ BCM_LS SG_ 2152464384 LDWIC_IndReq 1;
BA_REL_ "GenSigSuprvResp" BU_SG_REL_ MSM_LS SG_ 2154971136 PassHCSeatSw3Act 1;
BA_REL_ "GenSigSuprvResp" BU_SG_REL_ MSM_LS SG_ 2154971136 PassHCSeatSw2Act 1;
BA_REL_ "GenSigSuprvResp" BU_SG_REL_ MSM_LS SG_ 2154971136 PassHCSeatSw1Act 1;
BA_REL_ "GenSigSuprvResp" BU_SG_REL_ MSM_LS SG_ 2154971136 DrvHCSeatSw3Act 1;
BA_REL_ "GenSigSuprvResp" BU_SG_REL_ MSM_LS SG_ 2154971136 DrvHCSeatSw2Act 1;
BA_REL_ "GenSigSuprvResp" BU_SG_REL_ MSM_LS SG_ 2154971136 DrvHCSeatSw1Act 1;
BA_REL_ "GenSigSuprvResp" BU_SG_REL_ BSM_LS SG_ 2154643456 CCClntCrcFlwRtReq 1;
BA_REL_ "GenSigSuprvResp" BU_SG_REL_ BSM_LS SG_ 2154643456 HtrCoreInltClntTmpCalc 1;
VAL_ 2154954752 WPwrdRmStEnbld 1 "true" 0 "false" ;
VAL_ 2154954752 HtdStWhlInd 3 "High" 2 "Medium" 1 "Low" 0 "Off" ;
VAL_ 2154954752 HtdStWhlCtrlSrc 1 "Remote Switch Control" 0 "Local Switch Control" ;
VAL_ 2154954752 HtdStWhlCmd 3 "High" 2 "Medium" 1 "Low" 0 "Off" ;
VAL_ 2154954752 ClmtHtPwrRqd 1 "true" 0 "false" ;
VAL_ 2150252544 ECHG_YAxisMaxVal 0 "6" 1 "12" 2 "16" 3 "20" 4 "32" 5 "40" 6 "48" 7 "60" ;
VAL_ 2150252544 ECHG_XAxisTkMrkIntvl 0 "0.5" 1 "1" 2 "5" 3 "10" 4 "20" 5 "50" 6 "80" 7 "100" ;
VAL_ 2150252544 ECHG_MeasUnit 0 "km/kWh" 1 "mi/kWh" 2 "kWh/100km" 3 "km/L" 4 "mi/gal" 5 "L/100km" 6 "mi/kg" 7 "kg/100km" ;
VAL_ 2153308160 RdHVltBatPckVltV 1 "Invalid" 0 "Valid" ;
VAL_ 2153308160 RdHVltBatPckVltM 1 "Use Data" 0 "Don't Use Data" ;
VAL_ 2153308160 RdHVltBatPckCrntV 1 "Invalid" 0 "Valid" ;
VAL_ 2153308160 RdHVltBatPckCrntM 1 "Use Data" 0 "Don't Use Data" ;
VAL_ 2150580224 CstmrNonUsblSOCV 1 "Invalid" 0 "Valid" ;
VAL_ 2150080512 LBCVLS_VehGPSLctV 1 "Invalid" 0 "Valid" ;
VAL_ 2150080512 LBCVLS_VehGPSLct 4 "Vehicle Within Stored GPS Region 4" 3 "Vehicle Within Stored GPS Region 3" 2 "Vehicle Within Stored GPS Region 2" 1 "Vehicle Within Stored GPS Region 1" 0 "Vehicle Not Within Stored GPS Region" ;
VAL_ 2150080512 LBCPSS_PosUpdtStat 2 "Position Modification Failed " 1 "Position  Updated  " 0 "No Action" ;
VAL_ 2150080512 LBCPSS_PosUpdtLct 4 "Position 4" 3 "Position 3" 2 "Position 2" 1 "Position 1" 0 "No Action" ;
VAL_ 2150080512 LBCCsStAvl 1 "true" 0 "false" ;
VAL_ 2150080512 LBCCsCrStVal 2 "On" 1 "Off" 0 "No Action" ;
VAL_ 2150080512 LBCCF_Lct4PosStrdIO 1 "true" 0 "false" ;
VAL_ 2150080512 LBCCF_Lct3PosStrdIO 1 "true" 0 "false" ;
VAL_ 2150080512 LBCCF_Lct2PosStrdIO 1 "true" 0 "false" ;
VAL_ 2150080512 LBCCF_Lct1PosStrdIO 1 "true" 0 "false" ;
VAL_ 2150080512 LBCCDRR_PosNumbr 4 "Position Number 4 " 3 "Position Number 3" 2 "Position Number 2" 1 "Position Number 1" 0 "No Action" ;
VAL_ 2150080512 LBCCDRR_ClrStrdPosResp 2 "Clear Position Performed" 1 "Clear Position Request Acknowledged" 0 "No Action" ;
VAL_ 2150080512 LBCChrgLvlPrfExpIO 1 "true" 0 "false" ;
VAL_ 2150080512 EngAstHtDfrdHtMdAct 1 "true" 0 "false" ;
VAL_ 2150080512 AuxClntHtrVlvStat 7 "Unused and Reserved 2" 6 "De-Aeration Routine Active" 5 "Diagnostic Override" 4 "Re-Calibration" 3 "Fault Active" 2 "Engine Link" 1 "Transition" 0 "Engine Bypass" ;
VAL_ 2150383616 LssOfPrplsnIO 1 "true" 0 "false" ;
VAL_ 2150383616 EngMntnceMdAct 1 "true" 0 "false" ;
VAL_ 2150383616 MntnceMdDsplyRq 15 "Unused and Reserved" 14 "Continue FM" 13 "Force FM" 12 "FM 1 Day Warning" 11 "FM 2 Day Warning" 10 "FM 3 Day Warning" 9 "FM 4 Day Warning" 8 "FM 5 Day Warning" 7 "Continue EM" 6 "Force EM" 5 "EM 1 Day Warning" 4 "EM 2 Day Warning" 3 "EM 3 Day Warning" 2 "EM 4 Day Warning" 1 "EM 5 Day Warning" 0 "No Request" ;
VAL_ 2150055936 ClimCtrlHVDvcShtdwnCmd 1 "true" 0 "false" ;
VAL_ 2150039552 EvpCorOtltAirTmpCalcdV 1 "true" 0 "false" ;
VAL_ 2150039552 ThrmlRefCompStat 0 "Unknown" 1 "Has never moved" 2 "Has moved but currently stopped" 3 "Moving in same direction as host" ;
VAL_ 2150039552 ThrmlRefCompSpdV 1 "Invalid" 0 "Valid" ;
VAL_ 2150039552 ThrmlRfCmpOvTmpFltPr 1 "true" 0 "false" ;
VAL_ 2150023168 OffBrdVehImmbNot 0 "No Action" 1 "Immobilization State 1" 2 "Immobilization State 2" ;
VAL_ 2150023168 HVInvRatVltV 1 "Invalid" 0 "Valid" ;
VAL_ 2150023168 HybChrgMdStat 3 "Unused and reserved 2" 2 "Unused and reserved 1" 1 "Charge Sustaining" 0 "Charge Depleting" ;
VAL_ 2153988096 PwrElecCoolLpTempM 0 "Don't Use Data" 1 "Use Data" ;
VAL_ 2153988096 PwrElecCoolLpTempV 1 "Invalid" 0 "Valid" ;
VAL_ 2155233280 RtBsChrgCmplnTmPrfRsp 2 "Latest Possible" 1 "Earliest Possible" 0 "No Action" ;
VAL_ 2155233280 EngRnngDutoVehSpdIO 1 "true" 0 "false" ;
VAL_ 2155233280 ShftPrkIO_3B2 1 "true" 0 "false" ;
VAL_ 2155233280 FlDrOpenIndOn 1 "true" 0 "false" ;
VAL_ 2155233280 VehRefuelSt 7 "Unused and Reserved 4" 6 "Unused and Reserved 3" 5 "Unused and Reserved 2" 4 "Unused and Reserved 1" 3 "Close Fuel Door" 2 "Ready To Refuel" 1 "Wait To Refuel" 0 "Inactive" ;
VAL_ 2155233280 NtrlCstdwnCrtMdActvIO 1 "true" 0 "false" ;
VAL_ 2155233280 UtlChrgPopUpAct 1 "true" 0 "false" ;
VAL_ 2155233280 UtlChrgIntrfrIO 1 "true" 0 "false" ;
VAL_ 2155233280 InstnsFlEcnHybOvrdReq 7 "Unused and Reserved 3" 6 "Unused and Reserved 2" 5 "Unused and Reserved 1" 4 "EV" 3 "Auto Stop" 2 "Max Fuel Economy" 1 "Min Fuel Economy" 0 "No Action" ;
VAL_ 2155233280 NtrlGrWrngIO 1 "true" 0 "false" ;
VAL_ 2150121472 RmtTrlrLtngSeqReq 2 "On" 1 "Off" 0 "No Action" ;
VAL_ 2150105088 TrlrLghtAlrtEnbld 1 "true" 0 "false" ;
VAL_ 2150105088 TrlRvsLghtFldEnbld 1 "true" 0 "false" ;
VAL_ 2150105088 TrlrThftAlrtEnbld 1 "true" 0 "false" ;
VAL_ 2150105088 TrlrLtngSeqReq 2 "On" 1 "Off" 0 "No Action" ;
VAL_ 2152013824 SmrtHgBmAstCstSetAvail 1 "true" 0 "false" ;
VAL_ 2152013824 SmrtHgBmAstCstCurrSetVal 7 "Unused and Reserved 5" 6 "Unused and Reserved 4" 5 "Unused and Reserved 3" 4 "Unused and Reserved 2" 3 "Unused and Reserved 1" 2 "Adaptive High Beam" 1 "Auto High Beam" 0 "No Action" ;
VAL_ 2151849984 AutoThrmlStPassMdStRq 3 "Vent Cool" 2 "Back Only Heat" ;
VAL_ 2151849984 AutoThrmlStDrvMdStRq 3 "Vent Cool" 2 "Back Only Heat" ;
VAL_ 2151849984 AutoThrmlStPasLvlStRq 5 "Level 5" 4 "Level 4" 3 "Level 3" 2 "Level 2" ;
VAL_ 2151849984 AutoThrmlStDrvLvStRq 5 "Level 5" 4 "Level 4" 3 "Level 3" 2 "Level 2" ;
VAL_ 2154618880 ClmCntPrtyHtRqV 1 "Invalid" 0 "Valid" ;
VAL_ 2154618880 ClmCntPrtyHtRq 3 "HIGH" 2 "MEDIUM" 1 "LOW" 0 "NO ACTION" ;
VAL_ 2154618880 ClmCntCalcTrgtCbnHtLdV 1 "Invalid" 0 "Valid" ;
VAL_ 2154618880 ClmCntMinTrgtClntTmpV 1 "Invalid" 0 "Valid" ;
VAL_ 2154618880 ClmCntHtrMinFlwRtRqV 1 "Invalid" 0 "Valid" ;
VAL_ 2150129664 HtVwAutnmsEPBAplyReqd 1 "true" 0 "false" ;
VAL_ 2155216896 DgtlMapPstdSpdLimAsrd 1 "true" 0 "false" ;
VAL_ 2155216896 SpdLmtPstdSpdM 0 "Don't Use Data" 1 "Use Data" ;
VAL_ 2155216896 CurvAdvInd 3 "Winding Road" 2 "Right Turn" 1 "Left Turn" 0 "No Advisory" ;
VAL_ 2155216896 ISA2CCC_ScndCdChr 0 "Unknown" 1 "A" 2 "B" 3 "C" 4 "D" 5 "E" 6 "F" 7 "G" 8 "H" 9 "I" 10 "J" 11 "K" 12 "L" 13 "M" 14 "N" 15 "O" 16 "P" 17 "Q" 18 "R" 19 "S" 20 "T" 21 "U" 22 "V" 23 "W" 24 "X" 25 "Y" 26 "Z" ;
VAL_ 2155216896 ISA2CCC_FrstCdChr 0 "Unknown" 1 "A" 2 "B" 3 "C" 4 "D" 5 "E" 6 "F" 7 "G" 8 "H" 9 "I" 10 "J" 11 "K" 12 "L" 13 "M" 14 "N" 15 "O" 16 "P" 17 "Q" 18 "R" 19 "S" 20 "T" 21 "U" 22 "V" 23 "W" 24 "X" 25 "Y" 26 "Z" ;
VAL_ 2155216896 SpdLmtUnits 1 "km/h" 0 "mph" ;
VAL_ 2155216896 LnCat 3 "Four Or More Lanes" 2 "Two Or Three Lanes" 1 "One lane" 0 "no info available" ;
VAL_ 2155216896 RdSpdCatType 3 "all speed categories 0 - 50 km/h" 2 "all speed categories 51-80 km/h" 1 "all speed categories 81-130 km/h" 0 "all speed categories > 130 km/h" ;
VAL_ 2155216896 FncRdClass 7 "COLLECTOR" 6 "ALLEY" 5 "ARTERIAL" 4 "HIGHWAY" 3 "PED-MALL" 2 "FREEWAY" 1 "SFREEWAY" 0 "LOCAL (Residential Road)" ;
VAL_ 2155216896 SprtLnRd 1 "true" 0 "false" ;
VAL_ 2155216896 CntrldAccRd 1 "true" 0 "false" ;
VAL_ 2155216896 BldUpArDet 1 "true" 0 "false" ;
VAL_ 2155216896 MpDataAvlbl 1 "true" 0 "false" ;
VAL_ 2150277120 PsngSysLongV 1 "Invalid" 0 "Valid" ;
VAL_ 2150277120 PsngSysLatV 1 "Invalid" 0 "Valid" ;
VAL_ 2150285312 PsngSysCalcSpdV 1 "Invalid" 0 "Valid" ;
VAL_ 2150285312 PsngSysHdingV 1 "Invalid" 0 "Valid" ;
VAL_ 2150285312 PsngSysElvtnV 1 "Invalid" 0 "Valid" ;
VAL_ 2150285312 PsngSysDilPrcsV 1 "Invalid" 0 "Valid" ;
VAL_ 2151047168 HdUpDspAnmtStat 0 "Animation Not Available" 1 "Animation Available" 2 "Welcome Active" 3 "CRANK Active" 4 "RUN Active" 5 "Good Bye Active" ;
VAL_ 2151047168 HUDActv 1 "true" 0 "false" ;
VAL_ 2154225664 RLDrHndleSwAtv 1 "true" 0 "false" ;
VAL_ 2154225664 RRDrHndleSwAtv 1 "true" 0 "false" ;
VAL_ 2154225664 RCHndleSwAtv 1 "true" 0 "false" ;
VAL_ 2154225664 PasDrHndleSwAtv 1 "true" 0 "false" ;
VAL_ 2154225664 DrvDrHndleSwAtv 1 "true" 0 "false" ;
VAL_ 2149900288 BTTethrngPrngReq 0 "No Action" 1 "Available" 2 "Bluetooth Address" 3 "Pairing PIN" 4 "Unused and Reserved" 5 "Delete Pairing Information" 6 "Enter Bluetooth Pairing Mode" ;
VAL_ 2149900288 EnhSrvAudAlRq 3 "Alarm" 2 "Chirp" 1 "Off" 0 "No Action" ;
VAL_ 2149900288 EnhSrvVisAlRq 3 "Repeated Flash" 2 "Single Flash" 1 "Off" 0 "No Action" ;
VAL_ 2149900288 EnhSrvRmStrtRq 2 "Engine Requested On" 1 "Engine Requested Off" 0 "No Activation" ;
VAL_ 2149900288 EnhSrvRClsRlsRq 1 "Release" 0 "No Action" ;
VAL_ 2149900288 EnhSrvLckRq 5 "Undeadbolt All" 4 "Deadbolt All" 3 "Unlock All" 2 "Unlock Driver Door" 1 "Lock All" 0 "No Action" ;
VAL_ 2157985792 FobProgEvntRqd 1 "true" 0 "false" ;
VAL_ 2155479040 DrvStyPerfMdCsStReq 7 "Performance Mode 7" 6 "Performance Mode 6" 5 "Performance Mode 5" 4 "Performance Mode 4" 3 "Performance Mode 3" 2 "Performance Mode 2" 1 "Performance Mode 1" 0 "No Action" ;
VAL_ 2155479040 PsngStPerfMdCsStReq 7 "Auto" 6 "Performance Mode 6" 5 "Performance Mode 5" 4 "Performance Mode 4" 3 "Performance Mode 3" 2 "Performance Mode 2" 1 "Performance Mode 1" 0 "No Action" ;
VAL_ 2155479040 DrvrStPerfMdCsStReq 7 "Auto" 6 "Performance Mode 6" 5 "Performance Mode 5" 4 "Performance Mode 4" 3 "Performance Mode 3" 2 "Performance Mode 2" 1 "Performance Mode 1" 0 "No Action" ;
VAL_ 2155479040 ACCPerfMdCsStReq 7 "Auto" 6 "Performance Mode 6" 5 "Performance Mode 5" 4 "Performance Mode 4" 3 "Performance Mode 3" 2 "Performance Mode 2" 1 "Performance Mode 1" 0 "No Action" ;
VAL_ 2155479040 ElvtdIdlCstStReq 0 "No Action" 1 "Off" 2 "On" ;
VAL_ 2155479040 PedFrndlyAlrtCsStReq 0 "No Action" 1 "Off" 2 "On" ;
VAL_ 2155479040 SndPerfMdCsStRq 0 "No Action" 1 "Performance Mode 1" 2 "Performance Mode 2" 3 "Performance Mode 3" 4 "Performance Mode 4" 5 "Performance Mode 5" 6 "Performance Mode 6" 7 "Auto" ;
VAL_ 2155479040 DispPerfMdCsStRq 0 "No Action" 1 "Performance Mode 1" 2 "Performance Mode 2" 3 "Performance Mode 3" 4 "Performance Mode 4" 5 "Performance Mode 5" 6 "Performance Mode 6" 7 "Auto" ;
VAL_ 2155479040 SusCustStngReq 7 "Auto" 6 "Performance Mode 6" 5 "Performance Mode 5" 4 "Performance Mode 4" 3 "Performance Mode 3" 2 "Performance Mode 2" 1 "Performance Mode 1" 0 "No Action" ;
VAL_ 2155479040 StrCustStngReq 7 "Auto" 6 "Performance Mode 6" 5 "Performance Mode 5" 4 "Performance Mode 4" 3 "Performance Mode 3" 2 "Performance Mode 2" 1 "Performance Mode 1" 0 "No Action" ;
VAL_ 2155479040 RstrCustFctrDef 1 "Restore Defaults" 0 "No Action" ;
VAL_ 2155479040 DrvlnCustStngReq 7 "Auto" 6 "Performance Mode 6" 5 "Performance Mode 5" 4 "Performance Mode 4" 3 "Performance Mode 3" 2 "Performance Mode 2" 1 "Performance Mode 1" 0 "No Action" ;
VAL_ 2151383040 TreInfMonSysRstReq 1 "true" 0 "false" ;
VAL_ 2155421696 ServKylsStSysIO 1 "true" 0 "false" ;
VAL_ 2155421696 PsvEntAprchDrctn 0 "Driver" 1 "Co-Driver" 2 "Front" 3 "Rear" ;
VAL_ 2155421696 PsvEntApprchDtcd 1 "true" 0 "false" ;
VAL_ 2155421696 PsvEntApprchCnfgReq 0 "Level 0" 1 "Level 1" 2 "Level 2" 3 "Level 3" 4 "Level 4" 5 "Level 5" 6 "Level 6" 7 "Level 7" ;
VAL_ 2151972864 VehFuelRngCalcV 1 "Invalid" 0 "Valid" ;
VAL_ 2151972864 FuelLvlLwIO 1 "true" 0 "false" ;
VAL_ 2151972864 LnchCtrlWhlSlpReq 31 "Unused and Reserved 10" 30 "Unused and Reserved 9" 29 "Unused and Reserved 8" 28 "Unused and Reserved 7" 27 "Unused and Reserved 6" 26 "Unused and Reserved 5" 25 "Unused and Reserved 4" 24 "Unused and Reserved 3" 23 "Unused and Reserved 2" 22 "Unused and Reserved 1" 21 "Fifteen Percent" 20 "Fourteen And A Half Percent" 19 "Fourteen Percent" 18 "Thirteen And A Half Percent" 17 "Thirteen Percent" 16 "Twelve And A Half Percent" 15 "Twelve Percent" 14 "Eleven And a Half Percent" 13 "Eleven Percent" 12 "Ten And A Half Percent" 11 "Ten Percent" 10 "Nine And A Half Percent" 9 "Nine Percent" 8 "Eight And A Half Percent" 7 "Eight Percent" 6 "Seven And A Half Percent" 5 "Seven Percent" 4 "Six And A Half Percent" 3 "Six Percent" 2 "Five And A Half Percent" 1 "Five Percent" 0 "No Action" ;
VAL_ 2151972864 LnchCtrlMdReq 3 "Burn Out" 2 "Custom" 1 "Automatic" 0 "No Action" ;
VAL_ 2151972864 LnchCtrlEngRPMReq 63 "Unused and Reserved 30" 62 "Unused and Reserved 29" 61 "Unused and Reserved 28" 60 "Unused and Reserved 27" 59 "Unused and Reserved 26" 58 "Unused and Reserved 25" 57 "Unused and Reserved 24" 56 "Unused and Reserved 23" 55 "Unused and Reserved 22" 54 "Unused and Reserved 21" 53 "Unused and Reserved 20" 52 "Unused and Reserved 19" 51 "Unused and Reserved 18" 50 "Unused and Reserved 17" 49 "Unused and Reserved 16" 48 "Unused and Reserved 15" 47 "Unused and Reserved 14" 46 "Unused and Reserved 13" 45 "Unused and Reserved 12" 44 "Unused and Reserved 11" 43 "Unused and Reserved 10" 42 "Unused and Reserved 9" 41 "Unused and Reserved 8" 40 "Unused and Reserved 7" 39 "Unused and Reserved 6" 38 "Unused and Reserved 5" 37 "Unused and Reserved 4" 36 "Unused and Reserved 3" 35 "Unused and Reserved 2" 34 "Unused and Reserved 1" 33 "4000" 32 "3900" 31 "3800" 30 "3700" 29 "3600" 28 "3500" 27 "3400" 26 "3300" 25 "3200" 24 "3100" 23 "3000" 22 "2900" 21 "2800" 20 "2700" 19 "2600" 18 "2500" 17 "2400" 16 "2300" 15 "2200" 14 "2100" 13 "2000" 12 "1900" 11 "1800" 10 "1700" 9 "1600" 8 "1500" 7 "1400" 6 "1300" 5 "1200" 4 "1100" 3 "1000" 2 "900" 1 "800" 0 "No Action" ;
VAL_ 2156789760 FrPedDetCsStReq 3 "Alert and Brake" 2 "Alert" 1 "Off" 0 "No Action" ;
VAL_ 2156789760 SurdVwLightgCsSetReq 7 "Unused and Reserved 5" 6 "Unused and Reserved 4" 5 "Unused and Reserved 3" 4 "Unused and Reserved 2" 3 "Unused and Reserved 1" 2 "ON" 1 "OFF" 0 "No Action" ;
VAL_ 2156789760 SmrtHgBmAstCstSetReq 7 "Unused and Reserved 5" 6 "Unused and Reserved 4" 5 "Unused and Reserved 3" 4 "Unused and Reserved 2" 3 "Unused and Reserved 1" 2 "Adaptive High Beam" 1 "Auto High Beam" 0 "No Action" ;
VAL_ 2156789760 CldrMth 12 "December" 11 "November" 10 "October" 9 "September" 8 "August" 7 "July" 6 "June" 5 "May" 4 "April" 3 "March" 2 "February" 1 "January" 0 "Unknown" ;
VAL_ 2156789760 TimeDispFormat 1 "24 hour mode" 0 "12 hour mode" ;
VAL_ 2155298816 EngAirFltMonDrvrReq 3 "Reset" 2 "Disable" 1 "Enable" 0 "No Action" ;
VAL_ 2155298816 TrPrsMntrTrLdRstRqstd 0 "Unknown" 1 "Light Load" 2 "Best Economy Load" 3 "Max Load" ;
VAL_ 2155298816 TrPrsSnsProgEvntRqd 1 "true" 0 "false" ;
VAL_ 2158878720 ODDLC_WrpArnd 1 "true" 0 "false" ;
VAL_ 2158878720 ODDLC_ReqType 0 "Subscribe: FU sends DynData back and then on change) " 1 "Unsubscribe: cancel previous Subscribe" ;
VAL_ 2158878720 ODDLC_ReqDir 1 "true" 0 "false" ;
VAL_ 2158878720 ODDLC_DspMID 128 "Reserved" 64 "Reserved" 32 "OTIM" 16 "RearDisplayTwo" 8 "RearDisplayOne" 4 "AuxIP" 2 "CenterStack" 1 "IPC" ;
VAL_ 2158878720 ODDLC_BckgndFlag 1 "Background response" 0 "Immediate response required" ;
VAL_ 2153938944 RmtRflshMdReqtd 1 "true" 0 "false" ;
VAL_ 2150662144 EnvIdRspSt3 3 "Environment_id_request" 2 "Incorrect_immo_id" 1 "Info_valid" 0 "No_info" ;
VAL_ 2150653952 EnvIdRspSt2 3 "Environment_id_request" 2 "Incorrect_immo_id" 1 "true" 0 "false" ;
VAL_ 2153922560 ClmtCtrlHtrEngRunRq 1 "Engine Run Requested" 0 "No Action" ;
VAL_ 2153922560 ClimCtrlVoltBstModReq 1 "true" 0 "false" ;
VAL_ 2153922560 HtrVlvRqstdPstn 0 "No Request" 1 "Engine Bypass" 2 "Engine Link" 3 "Hold Current Position" ;
VAL_ 2153922560 ClntHtrElecPwrRatV 1 "Invalid" 0 "Valid" ;
VAL_ 2153807872 PsvStrtStrngClmnLckTT 2 "Flashing Indication" 1 "Continous Indication" 0 "No indication" ;
VAL_ 2153807872 ClmSysAuxFlrIndOn 1 "true" 0 "false" ;
VAL_ 2153807872 PsDoorOpenSwActV 1 "Invalid" 0 "Valid" ;
VAL_ 2153807872 PsDoorOpenSwAct 1 "true" 0 "false" ;
VAL_ 2153807872 DrDoorOpenSwActV 1 "Invalid" 0 "Valid" ;
VAL_ 2153807872 DrDoorOpenSwAct 1 "true" 0 "false" ;
VAL_ 2151399424 VhlFlRngLwIO 1 "true" 0 "false" ;
VAL_ 2151399424 WshFldLw 1 "true" 0 "false" ;
VAL_ 2151940096 EstIntRfSrfcTmpV 1 "Invalid" 0 "Valid" ;
VAL_ 2151940096 EstBulkIntAirTmpV 1 "Invalid" 0 "Valid" ;
VAL_ 2151940096 EstIntHorzDshSrfTmpM 0 "Don't Use Data" 1 "Use Data" ;
VAL_ 2151940096 A2ERRAlrmReq 2 "Cancel Alarm" 1 "Set Alarm" 0 "No Action" ;
VAL_ 2151923712 HLOCCstCurrSetVal 3 "On Open Only" 2 "On" 1 "Off" 0 "No Action" ;
VAL_ 2151923712 HLOCCstSetAvail 1 "true" 0 "false" ;
VAL_ 2151923712 HLOCCA_Res4Avail 1 "true" 0 "false" ;
VAL_ 2151923712 HLOCCA_Res3Avail 1 "true" 0 "false" ;
VAL_ 2151923712 HLOCCA_Res2Avail 1 "true" 0 "false" ;
VAL_ 2151923712 HLOCCA_Res1Avail 1 "true" 0 "false" ;
VAL_ 2151923712 HLOCCA_OnOpnOnlyAvail 1 "true" 0 "false" ;
VAL_ 2151923712 HLOCCA_OnAvail 1 "true" 0 "false" ;
VAL_ 2151923712 HLOCCA_OffAvail 1 "true" 0 "false" ;
VAL_ 2151923712 A1ERRAlrmReq 2 "Cancel Alarm" 1 "Set Alarm" 0 "No Action" ;
VAL_ 2150645760 EnvIdRspSt1 3 "Environment_id_request" 2 "Incorrect_immo_id" 1 "true" 0 "false" ;
VAL_ 2152464384 RtLnDepWrnSt 3 "Service Alignment" 2 "Right Lane Alert" 1 "Right Lane Ready to Assist" 0 "Right Lane Not Ready to Assist" ;
VAL_ 2152464384 LftLnDepWrnSt 3 "Service Alignment" 2 "Left Lane Alert" 1 "Left Lane Ready to Assist" 0 "Left Lane Not Ready to Assist" ;
VAL_ 2152464384 TnDrvLDWOffUnbIO 1 "true" 0 "false" ;
VAL_ 2152464384 HndsOffStrWhlDtIO 1 "true" 0 "false" ;
VAL_ 2152464384 LnKpAstDisbldIO 1 "true" 0 "false" ;
VAL_ 2152464384 LaneDepWrnDisbldIO 1 "true" 0 "false" ;
VAL_ 2152464384 SrvcLnKpAstSysIO 1 "true" 0 "false" ;
VAL_ 2152464384 LKAIC_AdbWngLn 0 "Off" 1 "Left Front Speaker" 2 "Right Front Speaker" ;
VAL_ 2152464384 LKAIC_Ind2 1 "true" 0 "false" ;
VAL_ 2152464384 LKAIC_Ind1 1 "true" 0 "false" ;
VAL_ 2152464384 LKAIC_IndReq 0 "Off" 1 "Continuous Indication" 2 "Flash Rate #1 Indication" ;
VAL_ 2152464384 SrvcLaneDepWrnSysIO 1 "true" 0 "false" ;
VAL_ 2152464384 LDWIC_LnDepWAWLn 2 "Right Front Speaker" 1 "Left Front Speaker" 0 "Off" ;
VAL_ 2152464384 LDWIC_Ind2 1 "true" 0 "false" ;
VAL_ 2152464384 LDWIC_Ind1 1 "true" 0 "false" ;
VAL_ 2152464384 LDWIC_IndReq 2 "Flash Rate #1 Indication" 1 "Continuous Indication" 0 "Off" ;
VAL_ 2154971136 PassHCSeatSw3Act 1 "true" 0 "false" ;
VAL_ 2154971136 PassHCSeatSw2Act 1 "true" 0 "false" ;
VAL_ 2154971136 PassHCSeatSw1Act 1 "true" 0 "false" ;
VAL_ 2154971136 DrvHCSeatSw3Act 1 "true" 0 "false" ;
VAL_ 2154971136 DrvHCSeatSw2Act 1 "true" 0 "false" ;
VAL_ 2154971136 DrvHCSeatSw1Act 1 "true" 0 "false" ;
VAL_ 2154676224 CmpsModSlfTstReq 1 "Initiate Self Test" 0 "No Action" ;
VAL_ 2154676224 CmpsModManCalReq 1 "Calibrate Sensor" 0 "No Action" ;
VAL_ 2154676224 CmpsDecZonSetReq 1 "Set New Zone" 0 "No Request" ;
VAL_ 2154676224 CmpsDecZonCmndVal 15 "Zone 15" 14 "Zone 14" 13 "Zone 13" 12 "Zone 12" 11 "Zone 11" 10 "Zone 10" 9 "Zone 9" 8 "Zone 8" 7 "Zone 7" 6 "Zone 6" 5 "Zone 5" 4 "Zone 4" 3 "Zone 3" 2 "Zone 2" 1 "Zone 1" 0 "Unknown" ;
VAL_ 2154643456 AuxHtrAtv 1 "true" 0 "false" ;
VAL_ 2154643456 HtrCoreInltClntTmpCalcV 1 "Invalid" 0 "Valid" ;
SIG_GROUP_ 2153848832 EngyUsgScrScalExtd 1 : EUSSE_MaxBarDspRng EUSSE_ITEgUgScrMxScVal EUSSE_TrEgUgScrMxScVal EUSSE_TcEgUgScrMxScVal EUSSE_OTEgUgScrMxScVal EUSSE_TrEgUgScrMnScVal EUSSE_TcEgUgScrMnScVal EUSSE_OTEgUgScrMnScVal EUSSE_ITEgUgScrMnScVal;
SIG_GROUP_ 2153832448 EngyUsgScrExtd 1 : EUSE_TtEngyUsgScrAvVal EUSE_TrEngyUsgScrAvVal EUSE_TcEngyUsgScrAvVal EUSE_OTEngyUsgScrAvVal EUSE_ITEngyUsgScrAvVal;
SIG_GROUP_ 2150244352 EngyCnsHsGrphDspDtVal 1 : ECHGDDV_Col10 ECHGDDV_Col9 ECHGDDV_Col8 ECHGDDV_Col7 ECHGDDV_Col6 ECHGDDV_Col5 ECHGDDV_Col4 ECHGDDV_Col3 ECHGDDV_Col2 ECHGDDV_Col1 ECHGDDV_EngyConsAvg;
SIG_GROUP_ 2150252544 EngyConsmpHistGrph 1 : ECHG_YAxisMaxVal ECHG_XAxisTkMrkIntvl ECHG_Column10 ECHG_Column09 ECHG_Column08 ECHG_Column07 ECHG_Column06 ECHG_Column05 ECHG_Column04 ECHG_Column03 ECHG_Column02 ECHG_Column01 ECHG_EngyCnsmdAvg ECHG_MeasUnit;
SIG_GROUP_ 2153914368 EngyUsgScrScal 1 : EUSS_TrEgUgScrMxScVal EUSS_TrEgUgScrMnScVal EUSS_TcEgUgScrMxScVal EUSS_TcEgUgScrMnScVal EUSS_ITEgUgScrMxScVal EUSS_ITEgUgScrMnScVal EUSS_OTEgUgScrMxScVal EUSS_OTEgUgScrMnScVal;
SIG_GROUP_ 2150080512 LBCVehLctStat 1 : LBCVLS_VehGPSLctV LBCVLS_VehGPSLct;
SIG_GROUP_ 2150080512 LBCPosStgStat 1 : LBCPSS_PosUpdtStat LBCPSS_PosUpdtLct;
SIG_GROUP_ 2150080512 LBCCstmrFdbk 1 : LBCCF_Lct4PosStrdIO LBCCF_Lct3PosStrdIO LBCCF_Lct2PosStrdIO LBCCF_Lct1PosStrdIO;
SIG_GROUP_ 2150080512 LBCCstmrDaRstResp 1 : LBCCDRR_PosNumbr LBCCDRR_ClrStrdPosResp;
SIG_GROUP_ 2151981056 DstTrvldDt 1 : DTD_FuelPrpDstTrvld DTD_DrvCyclDstTrvld DTD_BattPrpDstTrvld;
SIG_GROUP_ 2151809024 DrvCycElecEngyCnsmd 1 : DCEEC_EngyPct4 DCEEC_EngyPct3 DCEEC_EngyPct2 DCEEC_EngyPct1;
SIG_GROUP_ 2153988096 EngyUsgScr 1 : EUS_TtEngyUsgScrAvVal EUS_ITEngyUsgScrAvVal EUS_OTEngyUsgScrAvVal EUS_TrEngyUsgScrAvVal EUS_TcEngyUsgScrAvVal;
SIG_GROUP_ 2155216896 IntlStdAlph2CddCntryCd 1 : ISA2CCC_ScndCdChr ISA2CCC_FrstCdChr;
SIG_GROUP_ 2156789760 TmofDay 1 : TOD_SecofMin TOD_MinofHr TOD_HrofDay;
SIG_GROUP_ 2158878720 ODIDynDataLstRq_CntrStck 1 : ODDLC_SubIdReqM ODDLC_WrpArnd ODDLC_ReqType ODDLC_ReqDir ODDLC_NmEntries ODDLC_Idx ODDLC_FUCID ODDLC_DspMID ODDLC_DataId ODDLC_BckgndFlag;
SIG_GROUP_ 2151940096 Alrm2ExtRngReq 1 :;
SIG_GROUP_ 2151923712 HLOCCstAvail 1 : HLOCCA_Res4Avail HLOCCA_Res3Avail HLOCCA_Res2Avail HLOCCA_Res1Avail HLOCCA_OnOpnOnlyAvail HLOCCA_OnAvail HLOCCA_OffAvail;
SIG_GROUP_ 2151923712 Alrm1ExtRngReq 1 :;
SIG_GROUP_ 2152464384 LnKpAstIndCntrl 1 : LKAIC_AdbWngLn LKAIC_Ind2 LKAIC_Ind1 LKAIC_IndReq;
SIG_GROUP_ 2152464384 LaneDepWrnIndCntrl 1 : LDWIC_LnDepWAWLn LDWIC_Ind2 LDWIC_Ind1 LDWIC_IndReq;
